VERSION "HNPBNNNYNNNNNNNNNNNNNNNNNNNNNNNNYNYYYYYYYY>4>%%%/4>'%**4YYY///"

NS_ :

BS_:

BU_: TPM TCM SCCM RF_HUB PTS ORC IC HaLF ETM ESM ESC EPS ECM Diagnost DTCM DASM CBC AFLS ADCM

BO_ 530 ECM_DIESEL: 8 ECM
 SG_ DEF_LOW : 0|2@1+ (1,0) [0|0] ""  IC
 SG_ PFW_Stat : 4|4@1+ (1,0) [0|0] ""  IC
 SG_ PrcntCplt : 8|4@1+ (10,0) [0|100] "%"  IC
 SG_ FuelFltrHtrReq : 13|2@1+ (1,0) [0|0] ""  CBC
 SG_ EngChmRq : 15|1@1+ (1,0) [0|0] ""  IC
 SG_ ECM_HMI_Timer_RQ : 16|3@1+ (1,0) [0|0] ""  IC
 SG_ PreHtIndLmp_On_Rq : 19|1@1+ (1,0) [0|0] ""  ETM,IC,CBC
 SG_ EngOilTemp_Above_Max : 20|1@1+ (1,0) [0|0] ""  IC
 SG_ PTC_REL1_RQ : 21|1@1+ (1,0) [0|0] ""  CBC
 SG_ PTC_REL2_RQ : 22|1@1+ (1,0) [0|0] ""  CBC
 SG_ PTC_REL3_RQ : 23|1@1+ (1,0) [0|0] ""  CBC
 SG_ PFW : 24|2@1+ (1,0) [0|0] ""  ETM,IC
 SG_ ParticleFltrCorrOffset : 26|4@1+ (0.03,0) [0|0.42] "" Vector__XXX
 SG_ WtrFuelIndLmp_On_Rq : 30|1@1+ (1,0) [0|0] ""  ETM,IC
 SG_ PF_RgnActv : 31|1@1+ (1,0) [0|0] ""  TCM
 SG_ Adblue_Stat : 32|6@1+ (1,0) [0|0] ""  IC
 SG_ RemainDistUnt : 38|1@1+ (1,0) [0|0] ""  IC
 SG_ Adblue_FL_LVL : 40|8@1+ (1,0) [0|100] "%"  IC
 SG_ AdblueRemainDist : 55|16@0+ (1,0) [0|65534] ""  IC

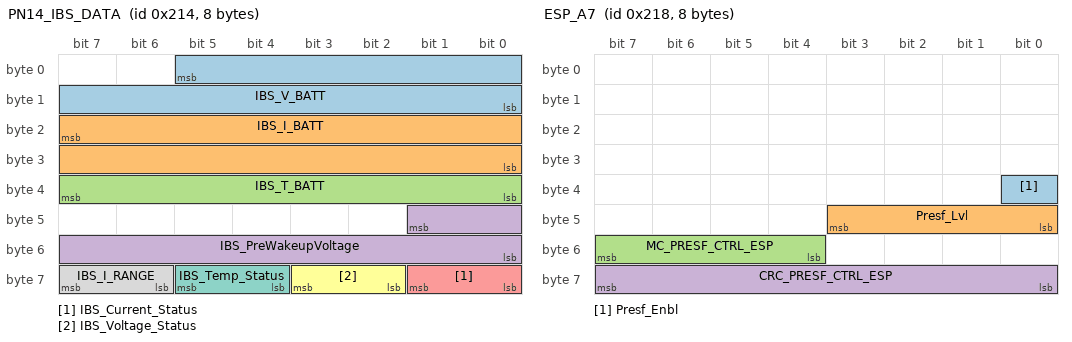
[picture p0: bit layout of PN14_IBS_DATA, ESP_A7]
BO_ 532 PN14_IBS_DATA: 8 CBC
 SG_ IBS_V_BATT : 5|14@0+ (0.0009765625,3) [3|18] "Volts"  ECM
 SG_ IBS_I_BATT : 23|16@0+ (1,-32768) [-32768|32766] "I_RANGE res."  ECM
 SG_ IBS_T_BATT : 32|8@1+ (1,-40) [-40|105] "°C"  ECM
 SG_ IBS_PreWakeupVoltage : 41|10@0+ (0.01,5) [5|15] "V"  ECM
 SG_ IBS_Current_Status : 56|2@1+ (1,0) [0|0] ""  ECM
 SG_ IBS_Voltage_Status : 58|2@1+ (1,0) [0|0] ""  ECM
 SG_ IBS_Temp_Status : 60|2@1+ (1,0) [0|0] ""  ECM
 SG_ IBS_I_RANGE : 62|2@1+ (1,0) [0|0] "Amp"  ECM

BO_ 536 ESP_A7: 8 ESC
 SG_ Presf_Enbl : 32|1@1+ (1,0) [0|0] "" Vector__XXX
 SG_ Presf_Lvl : 40|4@1+ (1,0) [0|0] "" Vector__XXX
 SG_ MC_PRESF_CTRL_ESP : 52|4@1+ (1,0) [0|15] "" Vector__XXX
 SG_ CRC_PRESF_CTRL_ESP : 56|8@1+ (1,0) [0|0] "" Vector__XXX

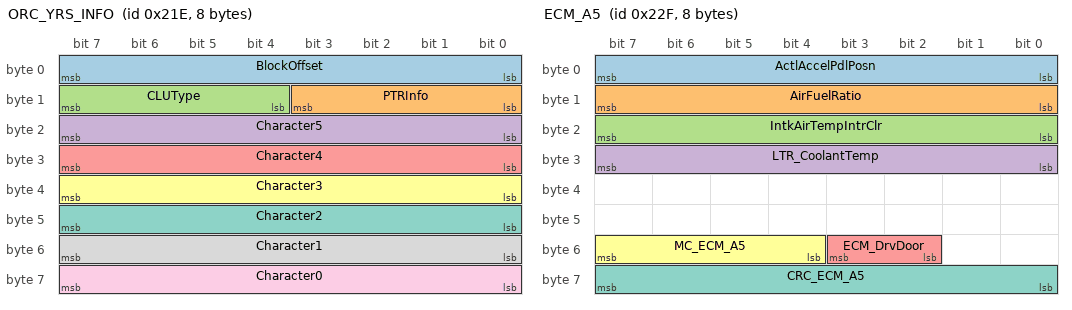
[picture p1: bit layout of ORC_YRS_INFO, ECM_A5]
BO_ 542 ORC_YRS_INFO: 8 Vector__XXX
 SG_ BlockOffset : 0|8@1+ (1,0) [0|0] ""  ESC
 SG_ PTRInfo : 8|4@1+ (1,0) [0|0] ""  ESC
 SG_ CLUType : 12|4@1+ (1,0) [0|0] ""  ESC
 SG_ Character5 : 16|8@1+ (1,0) [0|0] ""  ESC
 SG_ Character4 : 24|8@1+ (1,0) [0|0] ""  ESC
 SG_ Character3 : 32|8@1+ (1,0) [0|0] ""  ESC
 SG_ Character2 : 40|8@1+ (1,0) [0|0] ""  ESC
 SG_ Character1 : 48|8@1+ (1,0) [0|0] ""  ESC
 SG_ Character0 : 56|8@1+ (1,0) [0|0] ""  ESC

BO_ 544 EPS_1: 8 EPS
 SG_ StrClmTrq : 2|11@0+ (0.0078125,-8) [-8|7.98] "Nm"  HaLF,ECM,ESC,PTS
 SG_ TOI_Act_Sts : 3|4@1+ (1,0) [0|0] ""  HaLF,ESC,PTS
 SG_ StrClmTrqVD : 7|1@1+ (1,0) [0|0] ""  HaLF,ECM,ESC,PTS
 SG_ AssistanceTorque : 19|12@0+ (0.05,-100) [-100|104.65] "Nm"  HaLF,ESC,PTS
 SG_ PTSDriveStyleSts : 20|1@1+ (1,0) [0|0] ""  HaLF,ESC,PTS
 SG_ DSTTorqueOverlayFault : 21|1@1+ (1,0) [0|0] ""  HaLF,PTS
 SG_ HALFTorqueOverlayFault : 22|1@1+ (1,0) [0|0] ""  HaLF,ESC,PTS
 SG_ HALFTorqueOverlayIntActivated : 23|1@1+ (1,0) [0|0] ""  HaLF,ESC,PTS
 SG_ EPSMotorTorque : 34|11@0+ (0.001953125,-2) [-2|1.998047] "Nm"  HaLF
 SG_ DSTTorqueOverlayIntActivated : 37|1@1+ (1,0) [0|0] ""  HaLF,ESC
 SG_ EPSTemporaryDeactivationLDW : 38|1@1+ (1,0) [0|0] "" Vector__XXX
 SG_ EPSMotorTorqueValidData : 39|1@1+ (1,0) [0|0] ""  HaLF
 SG_ EPSHandsOnRecognition : 48|1@1+ (1,0) [0|0] ""  HaLF,ESC,PTS
 SG_ EPSTemporaryDeactivationPPPA : 49|1@1+ (1,0) [0|0] ""  HaLF,ESC,PTS
 SG_ PTSTorqueOverlayFault : 50|1@1+ (1,0) [0|0] ""  HaLF,ESC,PTS
 SG_ PTSTorqueOverlayIntActivated : 51|1@1+ (1,0) [0|0] ""  HaLF,ESC,PTS
 SG_ MC_EPS_1 : 52|4@1+ (1,0) [0|15] ""  HaLF,ECM,ESC,PTS
 SG_ CRC_EPS_1 : 56|8@1+ (1,0) [0|0] ""  HaLF,ECM,ESC,PTS

BO_ 557 SWS_8: 8 CBC
 SG_ StW_TempSts : 0|8@1+ (0.5,-40) [-40|85] "°C" Vector__XXX
 SG_ HrnSwPsd : 8|1@1+ (1,0) [0|0] ""  IC
 SG_ StW_TempSensSts : 9|2@1+ (1,0) [0|0] "" Vector__XXX
 SG_ Command_01 : 16|2@1+ (1,0) [0|0] ""  IC
 SG_ Command_02 : 18|2@1+ (1,0) [0|0] ""  IC
 SG_ Command_03 : 20|2@1+ (1,0) [0|0] ""  IC
 SG_ Command_04 : 22|2@1+ (1,0) [0|0] ""  IC
 SG_ Command_05 : 24|2@1+ (1,0) [0|0] ""  IC
 SG_ Command_06 : 26|2@1+ (1,0) [0|0] ""  IC
 SG_ Command_07 : 28|2@1+ (1,0) [0|0] ""  IC
 SG_ Command_08 : 30|2@1+ (1,0) [0|0] ""  IC
 SG_ Command_09 : 32|2@1+ (1,0) [0|0] ""  IC
 SG_ Command_10 : 34|2@1+ (1,0) [0|0] ""  IC
 SG_ Command_11 : 36|2@1+ (1,0) [0|0] ""  IC
 SG_ Command_12 : 38|2@1+ (1,0) [0|0] ""  IC
 SG_ Command_13 : 40|2@1+ (1,0) [0|0] ""  IC
 SG_ Command_14 : 42|2@1+ (1,0) [0|0] ""  IC
 SG_ Command_15 : 44|2@1+ (1,0) [0|0] ""  IC
 SG_ Command_16 : 46|2@1+ (1,0) [0|0] ""  IC

BO_ 559 ECM_A5: 8 ECM
 SG_ ActlAccelPdlPosn : 0|8@1+ (0.4,0) [0|100] "%"  DASM,ESC
 SG_ AirFuelRatio : 8|8@1+ (0.1,5.5) [5.5|18] "Lambda"  IC,CBC
 SG_ IntkAirTempIntrClr : 16|8@1+ (1,-64) [-64|190] "°C"  IC,CBC
 SG_ LTR_CoolantTemp : 24|8@1+ (1,-64) [-64|190] "°C"  IC,CBC
 SG_ ECM_DrvDoor : 50|2@1+ (1,0) [0|0] ""  DASM
 SG_ MC_ECM_A5 : 52|4@1+ (1,0) [0|15] ""  DASM
 SG_ CRC_ECM_A5 : 56|8@1+ (1,0) [0|0] ""  DASM

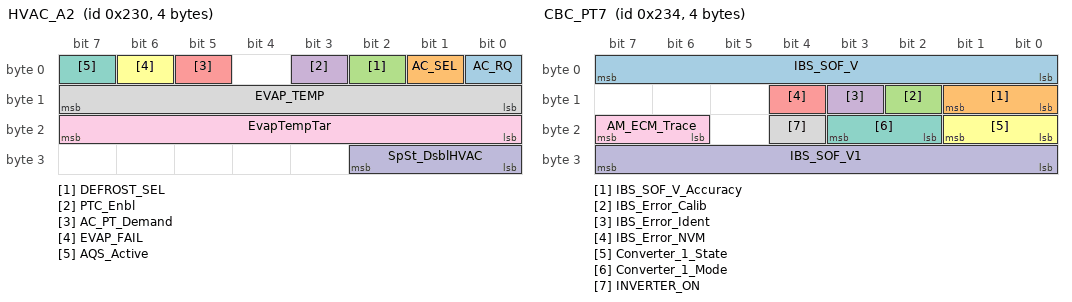
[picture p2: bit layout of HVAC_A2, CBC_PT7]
BO_ 560 HVAC_A2: 4 CBC
 SG_ AC_RQ : 0|1@1+ (1,0) [0|0] ""  ECM
 SG_ AC_SEL : 1|1@1+ (1,0) [0|0] ""  ECM
 SG_ DEFROST_SEL : 2|1@1+ (1,0) [0|0] ""  ECM
 SG_ PTC_Enbl : 3|1@1+ (1,0) [0|0] ""  ECM
 SG_ AC_PT_Demand : 5|1@1+ (1,0) [0|0] ""  ECM
 SG_ EVAP_FAIL : 6|1@1+ (1,0) [0|0] ""  ECM
 SG_ AQS_Active : 7|1@1+ (1,0) [0|0] "" Vector__XXX
 SG_ EVAP_TEMP : 8|8@1+ (0.5,-20) [-20|107] "°C"  ECM
 SG_ EvapTempTar : 16|8@1+ (0.5,-20) [-20|107] "°C"  ECM
 SG_ SpSt_DsblHVAC : 24|3@1+ (1,0) [0|0] ""  ECM

BO_ 564 CBC_PT7: 4 CBC
 SG_ IBS_SOF_V : 0|8@1+ (0.0625,0) [0|15.875] "V"  ECM
 SG_ IBS_SOF_V_Accuracy : 8|2@1+ (1,0) [0|0] ""  ECM
 SG_ IBS_Error_Calib : 10|1@1+ (1,0) [0|0] ""  ECM
 SG_ IBS_Error_Ident : 11|1@1+ (1,0) [0|0] ""  ECM
 SG_ IBS_Error_NVM : 12|1@1+ (1,0) [0|0] ""  ECM
 SG_ Converter_1_State : 16|2@1+ (1,0) [0|0] ""  ECM
 SG_ Converter_1_Mode : 18|2@1+ (1,0) [0|0] ""  ECM
 SG_ INVERTER_ON : 20|1@1+ (1,0) [0|0] ""  ECM
 SG_ AM_ECM_Trace : 22|2@1+ (1,0) [0|0] ""  ECM
 SG_ IBS_SOF_V1 : 24|8@1+ (0.0625,0) [0|15.875] "V"  ECM

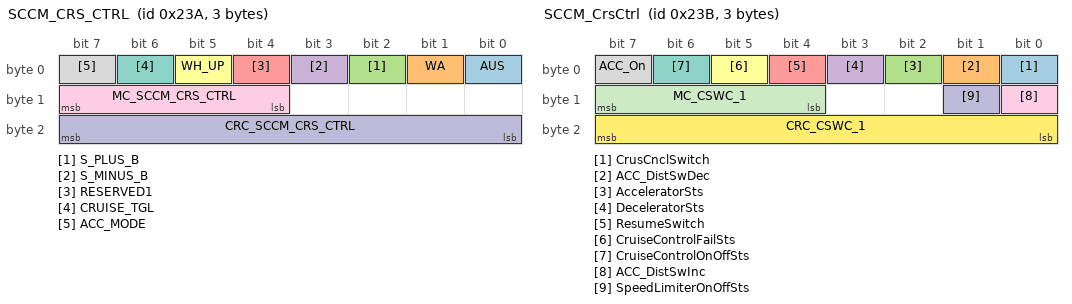
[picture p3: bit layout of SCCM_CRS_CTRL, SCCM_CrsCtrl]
BO_ 570 SCCM_CRS_CTRL: 3 Vector__XXX
 SG_ AUS : 0|1@1+ (1,0) [0|0] ""  ECM,DASM,ESC
 SG_ WA : 1|1@1+ (1,0) [0|0] ""  ECM,DASM,ESC
 SG_ S_PLUS_B : 2|1@1+ (1,0) [0|0] ""  ECM,DASM,ESC
 SG_ S_MINUS_B : 3|1@1+ (1,0) [0|0] ""  ECM,DASM,ESC
 SG_ RESERVED1 : 4|1@1+ (1,0) [0|0] ""  ECM,DASM,ESC
 SG_ WH_UP : 5|1@1+ (1,0) [0|0] ""  ECM,DASM,ESC
 SG_ CRUISE_TGL : 6|1@1+ (1,0) [0|0] ""  ECM,DASM,ESC
 SG_ ACC_MODE : 7|1@1+ (1,0) [0|0] ""  ECM,DASM,ESC
 SG_ MC_SCCM_CRS_CTRL : 12|4@1+ (1,0) [0|15] ""  ECM,DASM,ESC
 SG_ CRC_SCCM_CRS_CTRL : 16|8@1+ (1,0) [0|0] ""  ECM,DASM,ESC

BO_ 571 SCCM_CrsCtrl: 3 SCCM
 SG_ CrusCnclSwitch : 0|1@1+ (1,0) [0|0] ""  ECM,DASM,ESC
 SG_ ACC_DistSwDec : 1|1@1+ (1,0) [0|0] ""  ECM,DASM,ESC
 SG_ AcceleratorSts : 2|1@1+ (1,0) [0|0] ""  ECM,DASM,ESC
 SG_ DeceleratorSts : 3|1@1+ (1,0) [0|0] ""  ECM,DASM,ESC
 SG_ ResumeSwitch : 4|1@1+ (1,0) [0|0] ""  ECM,DASM,ESC
 SG_ CruiseControlFailSts : 5|1@1+ (1,0) [0|0] ""  ECM,DASM,ESC
 SG_ CruiseControlOnOffSts : 6|1@1+ (1,0) [0|0] ""  ECM,DASM,ESC
 SG_ ACC_On : 7|1@1+ (1,0) [0|0] ""  ECM,DASM,ESC
 SG_ ACC_DistSwInc : 8|1@1+ (1,0) [0|0] ""  ECM,DASM,ESC
 SG_ SpeedLimiterOnOffSts : 9|1@1+ (1,0) [0|0] ""  ECM,DASM,ESC
 SG_ MC_CSWC_1 : 12|4@1+ (1,0) [0|15] ""  ECM,DASM,ESC
 SG_ CRC_CSWC_1 : 16|8@1+ (1,0) [0|0] ""  ECM,DASM,ESC

BO_ 584 PN14_STAT: 8 CBC
 SG_ PN14_LS_Actv : 0|1@1+ (1,0) [0|0] ""  ECM,AFLS,TPM,PTS,IC
 SG_ PN14_Key_Off_Load_Shed : 1|2@1+ (1,0) [0|0] "" Vector__XXX
 SG_ PN14_LS_Lvl1 : 3|1@1+ (1,0) [0|0] "" Vector__XXX
 SG_ PN14_LS_Lvl2 : 4|1@1+ (1,0) [0|0] "" Vector__XXX
 SG_ PN14_LS_Lvl3 : 5|1@1+ (1,0) [0|0] "" Vector__XXX
 SG_ PN14_LS_Lvl4 : 6|1@1+ (1,0) [0|0] "" Vector__XXX
 SG_ PN14_LS_Lvl5 : 7|1@1+ (1,0) [0|0] "" Vector__XXX
 SG_ PN14_LS_Lvl6 : 8|1@1+ (1,0) [0|0] "" Vector__XXX
 SG_ PN14_LS_Lvl7 : 9|1@1+ (1,0) [0|0] "" Vector__XXX
 SG_ PN14_LS_Lvl8 : 10|1@1+ (1,0) [0|0] "" Vector__XXX
 SG_ PN14_LS_Lvl9 : 11|1@1+ (1,0) [0|0] "" Vector__XXX
 SG_ PN14_LS_Lvl10 : 12|1@1+ (1,0) [0|0] "" Vector__XXX
 SG_ IBS_SOC : 16|8@1+ (1,0) [0|100] "%"  ORC,ECM
 SG_ IBS_SOF_Q : 24|8@1+ (0.5,0) [0|127] "Ah"  ECM
 SG_ IBS_SOH_Q : 32|8@1+ (0.5,0) [0|127] "Ah"  ECM
 SG_ IBS_SOF_t : 41|10@0+ (1,0) [0|1022] "min"  ECM
 SG_ Batt_ST_Crit : 42|1@1+ (1,0) [0|0] ""  ECM
 SG_ IBS_SOC_Accuracy : 56|2@1+ (1,0) [0|0] ""  ECM
 SG_ IBS_SOF_Q_Accuracy : 58|2@1+ (1,0) [0|0] ""  ECM
 SG_ IBS_SOH_Q_Accuracy : 60|2@1+ (1,0) [0|0] ""  ECM
 SG_ IBS_SOF_t_Accuracy : 62|2@1+ (1,0) [0|0] ""  ECM

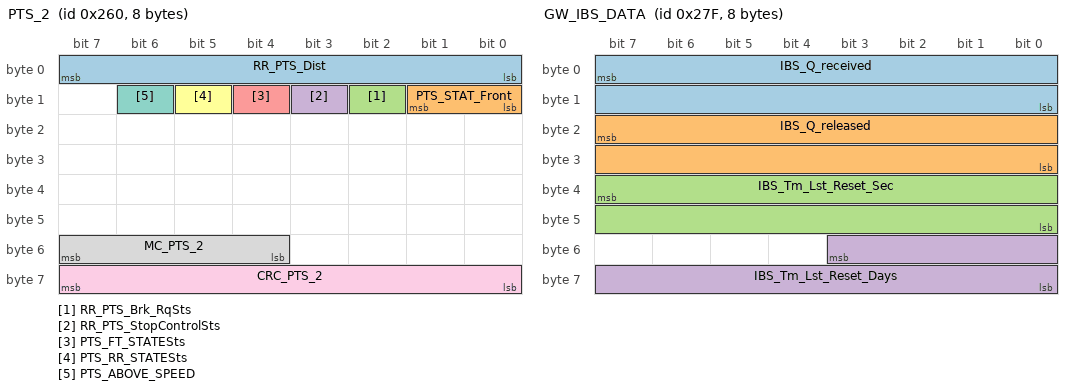
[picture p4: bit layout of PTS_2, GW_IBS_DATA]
BO_ 608 PTS_2: 8 PTS
 SG_ RR_PTS_Dist : 0|8@1+ (1,0) [0|254] "cm"  ESC
 SG_ PTS_STAT_Front : 8|2@1+ (1,0) [0|0] ""  CBC
 SG_ RR_PTS_Brk_RqSts : 10|1@1+ (1,0) [0|0] ""  ESC
 SG_ RR_PTS_StopControlSts : 11|1@1+ (1,0) [0|0] ""  ESC,CBC
 SG_ PTS_FT_STATESts : 12|1@1+ (1,0) [0|0] ""  IC
 SG_ PTS_RR_STATESts : 13|1@1+ (1,0) [0|0] ""  IC
 SG_ PTS_ABOVE_SPEED : 14|1@1+ (1,0) [0|0] ""  IC
 SG_ MC_PTS_2 : 52|4@1+ (1,0) [0|15] ""  ESC
 SG_ CRC_PTS_2 : 56|8@1+ (1,0) [0|0] ""  ESC

BO_ 624 CBC_PT8: 8 CBC
 SG_ PrkLmpFault : 0|1@1+ (1,0) [0|0] ""  IC
 SG_ LowBeamFault : 1|1@1+ (1,0) [0|0] ""  AFLS,IC
 SG_ HighBeamFault : 2|1@1+ (1,0) [0|0] ""  IC
 SG_ DRLFault : 3|1@1+ (1,0) [0|0] ""  IC
 SG_ FtFogLmpFault : 4|1@1+ (1,0) [0|0] ""  IC
 SG_ RearFogLmpFault : 5|1@1+ (1,0) [0|0] ""  IC
 SG_ SpLmpFault : 6|1@1+ (1,0) [0|0] ""  IC
 SG_ RevLmpFault : 7|1@1+ (1,0) [0|0] ""  IC
 SG_ PlateLmpFault : 8|1@1+ (1,0) [0|0] ""  IC
 SG_ TrlrSpTurnFault : 9|1@1+ (1,0) [0|0] ""  IC
 SG_ TrlrPrkFault : 10|1@1+ (1,0) [0|0] ""  IC
 SG_ HlSwFault : 11|1@1+ (1,0) [0|0] ""  IC
 SG_ AmbLgtSnsrFault : 12|1@1+ (1,0) [0|0] ""  IC
 SG_ AHB_Fault : 13|1@1+ (1,0) [0|0] ""  IC
 SG_ LgtSensFlt : 14|1@1+ (1,0) [0|0] ""  IC
 SG_ FuelTxfrSts : 42|2@1+ (1,0) [0|0] ""  ECM
 SG_ SecurePkSts : 44|3@1+ (1,0) [0|0] ""  IC
 SG_ HAZARD_STATUS : 47|1@1+ (1,0) [0|0] "" Vector__XXX
 SG_ EngineOffTimer : 51|12@0+ (1,0) [0|4080] "min"  ECM
 SG_ HL_Stat : 53|2@1+ (1,0) [0|0] "" Vector__XXX
 SG_ PNC_ALM_ACT : 55|1@1+ (1,0) [0|0] "" Vector__XXX

BO_ 632 ECM_B2: 8 ECM
 SG_ CC_SetSpdDspl : 0|8@1+ (1,0) [0|250] "km/h"  IC
 SG_ EngDrvMdStat : 8|3@1+ (1,0) [0|0] ""  TCM,CBC
 SG_ IdleShutDwnApply : 11|1@1+ (1,0) [0|0] ""  IC,CBC
 SG_ EVPmpStat : 12|2@1+ (1,0) [0|0] ""  ESC
 SG_ EconShftRq : 14|2@1+ (1,0) [0|0] ""  IC
 SG_ CoolVlvPos : 16|8@1+ (0.39374,0) [0|100] "%"  CBC
 SG_ VehMassCalc : 24|8@1+ (100,0) [0|25400] "Lbs."  DTCM,DASM,ESC
 SG_ VehMassCnfd : 32|3@1+ (1,0) [0|0] ""  DTCM,DASM,ESC
 SG_ EnblFuelTxfr : 35|1@1+ (1,0) [0|0] ""  CBC
 SG_ PerfShftRq : 36|2@1+ (1,0) [0|0] ""  TCM,IC
 SG_ CC_SetSpdDsplMPH : 40|8@1+ (1,0) [0|254] "mph"  IC
 SG_ SpStSwStat : 48|2@1+ (1,0) [0|0] ""  ORC,IC,CBC
 SG_ SpStTachMd : 50|2@1+ (1,0) [0|0] ""  IC,CBC
 SG_ SpStWarnStat : 52|4@1+ (1,0) [0|0] ""  ORC,IC
 SG_ SpStDispstat : 56|6@1+ (1,0) [0|0] ""  ORC,IC
 SG_ SpStIndRq : 62|1@1+ (1,0) [0|0] ""  IC
 SG_ SpStChmRq : 63|1@1+ (1,0) [0|0] ""  IC

BO_ 639 GW_IBS_DATA: 8 CBC
 SG_ IBS_Q_received : 7|16@0+ (0.125,0) [0|8191.75] "Ah" Vector__XXX
 SG_ IBS_Q_released : 23|16@0+ (0.125,0) [0|8191.75] "Ah" Vector__XXX
 SG_ IBS_Tm_Lst_Reset_Sec : 39|16@0+ (2,0) [0|86398] "sec"  ECM
 SG_ IBS_Tm_Lst_Reset_Days : 51|12@0+ (1,0) [0|4094] "Days" Vector__XXX

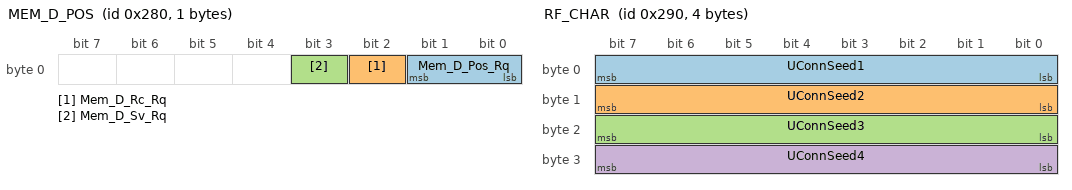
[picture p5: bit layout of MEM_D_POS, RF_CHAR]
BO_ 640 MEM_D_POS: 1 CBC
 SG_ Mem_D_Pos_Rq : 0|2@1+ (1,0) [0|0] ""  IC
 SG_ Mem_D_Rc_Rq : 2|1@1+ (1,0) [0|0] ""  IC
 SG_ Mem_D_Sv_Rq : 3|1@1+ (1,0) [0|0] ""  IC

BO_ 656 RF_CHAR: 4 RF_HUB
 SG_ UConnSeed1 : 0|8@1+ (1,0) [0|0] ""  ETM
 SG_ UConnSeed2 : 8|8@1+ (1,0) [0|0] ""  ETM
 SG_ UConnSeed3 : 16|8@1+ (1,0) [0|0] ""  ETM
 SG_ UConnSeed4 : 24|8@1+ (1,0) [0|0] ""  ETM

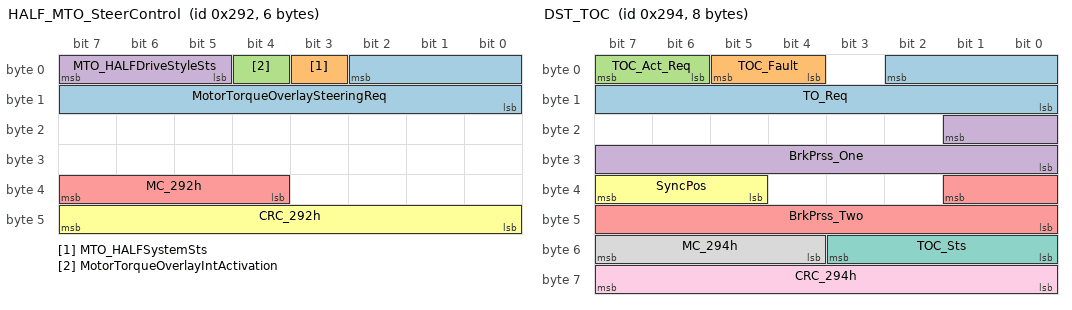
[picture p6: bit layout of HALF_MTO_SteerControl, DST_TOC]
BO_ 658 HALF_MTO_SteerControl: 6 HaLF
 SG_ MotorTorqueOverlaySteeringReq : 2|11@0+ (0.001953125,-2) [-2|1.998047] "Nm"  EPS
 SG_ MTO_HALFSystemSts : 3|1@1+ (1,0) [0|0] ""  EPS
 SG_ MotorTorqueOverlayIntActivation : 4|1@1+ (1,0) [0|0] ""  EPS
 SG_ MTO_HALFDriveStyleSts : 5|3@1+ (1,0) [0|0] ""  EPS
 SG_ MC_292h : 36|4@1+ (1,0) [0|15] ""  EPS
 SG_ CRC_292h : 40|8@1+ (1,0) [0|0] ""  EPS

BO_ 660 DST_TOC: 8 ESC
 SG_ TO_Req : 2|11@0+ (0.0078125,-8) [-8|7.9921875] "Nm"  EPS
 SG_ TOC_Fault : 4|2@1+ (1,0) [0|0] ""  EPS
 SG_ TOC_Act_Req : 6|2@1+ (1,0) [0|0] ""  EPS
 SG_ BrkPrss_One : 17|10@0+ (0.0048828125,0) [0|4.9951171875] "Volts"  ECM,EPS
 SG_ BrkPrss_Two : 33|10@0+ (0.0048828125,0) [0|4.9951171875] "Volts"  ECM,EPS
 SG_ SyncPos : 37|3@1+ (1,0) [0|0] ""  ECM,EPS
 SG_ TOC_Sts : 48|4@1+ (1,0) [0|0] ""  EPS
 SG_ MC_294h : 52|4@1+ (1,0) [0|15] ""  EPS
 SG_ CRC_294h : 56|8@1+ (1,0) [0|0] ""  EPS

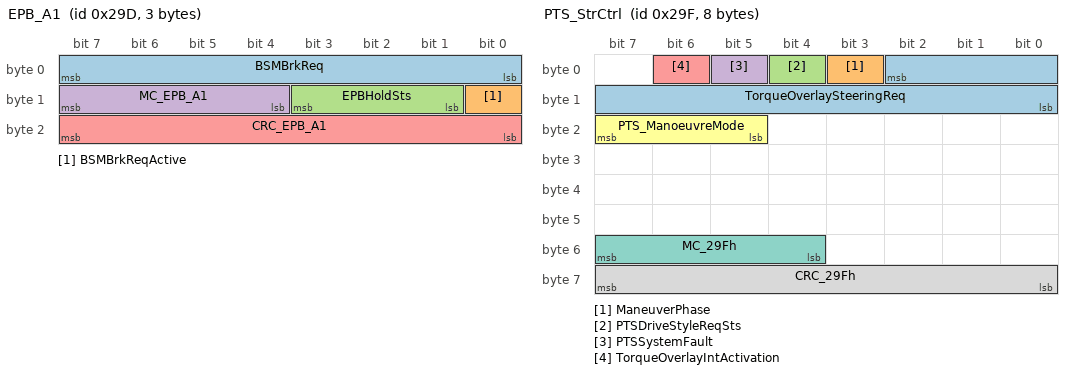
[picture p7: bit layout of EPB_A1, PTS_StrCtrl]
BO_ 669 EPB_A1: 3 Vector__XXX
 SG_ BSMBrkReq : 0|8@1+ (0.0312,0) [0|7.968] "m/s²"  ETM,TCM,ECM,DASM,ESC,CBC
 SG_ BSMBrkReqActive : 8|1@1+ (1,0) [0|0] ""  ETM,TCM,ECM,DASM,ESC,CBC
 SG_ EPBHoldSts : 9|3@1+ (1,0) [0|0] ""  ETM,ORC,TCM,ECM,DASM,ESC,CBC
 SG_ MC_EPB_A1 : 12|4@1+ (1,0) [0|15] ""  ETM,TCM,ECM,DASM,ESC,CBC
 SG_ CRC_EPB_A1 : 16|8@1+ (1,0) [0|0] ""  ETM,TCM,ECM,DASM,ESC,CBC

BO_ 671 PTS_StrCtrl: 8 PTS
 SG_ TorqueOverlaySteeringReq : 2|11@0+ (0.0078125,-8) [-8|7.9921875] "Nm"  EPS
 SG_ ManeuverPhase : 3|1@1+ (1,0) [0|0] ""  EPS
 SG_ PTSDriveStyleReqSts : 4|1@1+ (1,0) [0|0] ""  EPS
 SG_ PTSSystemFault : 5|1@1+ (1,0) [0|0] ""  EPS,IC
 SG_ TorqueOverlayIntActivation : 6|1@1+ (1,0) [0|0] ""  EPS
 SG_ PTS_ManoeuvreMode : 21|3@1+ (1,0) [0|0] ""  EPS,IC
 SG_ MC_29Fh : 52|4@1+ (1,0) [0|15] ""  EPS
 SG_ CRC_29Fh : 56|8@1+ (1,0) [0|0] ""  EPS

BO_ 672 ECM_INDICATORS: 8 ECM
 SG_ MIL_OnRq : 0|1@1+ (1,0) [0|0] ""  ORC,DASM,IC,CBC
 SG_ MIL_IND_BLINK : 1|1@1+ (1,0) [0|0] ""  ORC,IC,CBC
 SG_ ETC_IND_LMP : 2|2@1+ (1,0) [0|0] ""  ETM,IC,CBC
 SG_ MZR_MODE_ACT : 4|1@1+ (1,0) [0|0] ""  ETM,TCM,IC
 SG_ FUEL_SAV_MD_ACT : 5|2@1+ (1,0) [0|0] ""  IC,CBC
 SG_ OIL_IND_LMP_FLSH : 8|1@1+ (1,0) [0|0] ""  IC
 SG_ AutoOilChg : 9|1@1+ (1,0) [0|0] ""  IC,CBC
 SG_ EngOilIndLmp_On_Rq : 10|1@1+ (1,0) [0|0] ""  ETM,IC,CBC
 SG_ OIL_TEMP_IND_RQ : 11|2@1+ (1,0) [0|0] ""  ETM,IC
 SG_ OIL_TEMP_CHM_RQ : 13|2@1+ (1,0) [0|0] ""  ETM,IC
 SG_ ChkFuelCap : 15|1@1+ (1,0) [0|0] ""  ETM,IC
 SG_ OIL_PRESS : 16|8@1+ (4,0) [0|1016] "kPaG"  ETM,IC,CBC
 SG_ EngOilTemp : 24|8@1+ (1,-40) [-40|160] "°C"  EPS,TCM,IC,CBC
 SG_ FuelCons : 39|16@0+ (0.21668,0) [0|14200] "µl/100ms"  IC,CBC
 SG_ DefFuelEcon : 48|8@1+ (0.2,0) [0|50] "kmpl"  IC
 SG_ EngRun_Stat : 56|3@1+ (1,0) [0|0] ""  DASM,ESC,AFLS,PTS,IC,CBC,RF_HUB
 SG_ RedntHdStat : 59|2@1+ (1,0) [0|0] ""  IC

CM_ SG_ 530 DEF_LOW "DEF Low Indicator request";
CM_ SG_ 530 PFW_Stat "Particulate filter warning status";
CM_ SG_ 530 PrcntCplt "Percent complete";
CM_ SG_ 530 FuelFltrHtrReq "Fuel filter heater request on";
CM_ SG_ 530 EngChmRq "Engine chime request";
CM_ SG_ 530 ECM_HMI_Timer_RQ "DEF and DPF warning re-launch timer request";
CM_ SG_ 530 PreHtIndLmp_On_Rq "Request glow-plug (wait to start) lamp";
CM_ SG_ 530 EngOilTemp_Above_Max "Engine oil temperature too high (overheating)";
CM_ SG_ 530 PTC_REL1_RQ "Activate PTC Relay # 1 (diesel only)";
CM_ SG_ 530 PTC_REL2_RQ "Activate PTC Relay # 2 (diesel only)";
CM_ SG_ 530 PTC_REL3_RQ "Activate PTC Relay # 3 (diesel only)";
CM_ SG_ 530 PFW "Particulate filter warning";
CM_ SG_ 530 ParticleFltrCorrOffset "Particulate Filter Corection Offset SLP_MS_OFS";
CM_ SG_ 530 WtrFuelIndLmp_On_Rq "Request water in fuel lamp (diesel only)";
CM_ SG_ 530 PF_RgnActv "Particulate filter regeneration active";
CM_ SG_ 530 Adblue_Stat "Adblue status";
CM_ SG_ 530 RemainDistUnt "Adblue distance counter unit; miles = [0], km = [1]";
CM_ SG_ 530 Adblue_FL_LVL "Adblue fluid level";
CM_ SG_ 530 AdblueRemainDist "Adblue remaining distance";
CM_ SG_ 532 IBS_V_BATT "Batt. voltage measured at the terminals";
CM_ SG_ 532 IBS_I_BATT "Battery current (Using I_Range resolution)";
CM_ SG_ 532 IBS_T_BATT "Battery temperature";
CM_ SG_ 532 IBS_PreWakeupVoltage "IBS voltage before LIN wakeup";
CM_ SG_ 532 IBS_Current_Status "IBS Current Status";
CM_ SG_ 532 IBS_Voltage_Status "IBS Voltage Status";
CM_ SG_ 532 IBS_Temp_Status "IBS Temperature Status";
CM_ SG_ 532 IBS_I_RANGE "Current range sensor setting";
CM_ SG_ 536 Presf_Enbl "Presafe enabled";
CM_ SG_ 536 Presf_Lvl "Presafe level";
CM_ SG_ 536 MC_PRESF_CTRL_ESP "Message counter";
CM_ SG_ 536 CRC_PRESF_CTRL_ESP "CRC-checksum byte 1 to 7 according to SAE J1850";
CM_ SG_ 542 BlockOffset "Part number block offset";
CM_ SG_ 542 PTRInfo "Part number PTR information";
CM_ SG_ 542 CLUType "Part number CLU type";
CM_ SG_ 542 Character5 "Part number character 5";
CM_ SG_ 542 Character4 "Part number character 4";
CM_ SG_ 542 Character3 "Part number character 3";
CM_ SG_ 542 Character2 "Part number character 2";
CM_ SG_ 542 Character1 "Part number character 1";
CM_ SG_ 542 Character0 "Part number character 0";
CM_ SG_ 544 StrClmTrq "Steering column torque; counterclockwise positive [Nm]";
CM_ SG_ 544 TOI_Act_Sts "Torque overlay interface status";
CM_ SG_ 544 StrClmTrqVD "Steering column torque: valid data [1]";
CM_ SG_ 544 AssistanceTorque "Torque provided by EPS system to the shaft for the driver";
CM_ SG_ 544 PTSDriveStyleSts "PTS_TOC Actived = [1]";
CM_ SG_ 544 DSTTorqueOverlayFault "Torque overlay fault; True = 1";
CM_ SG_ 544 HALFTorqueOverlayFault "Fault of the HALF torque overlay interface";
CM_ SG_ 544 HALFTorqueOverlayIntActivated "Torque overlay interface has been successfully activated";
CM_ SG_ 544 EPSMotorTorque "EPS motor torque";
CM_ SG_ 544 DSTTorqueOverlayIntActivated "DST torque overlay interface activated; True = [1]";
CM_ SG_ 544 EPSTemporaryDeactivationLDW "Temporary deactivation of the EPS LDW torque overlay function";
CM_ SG_ 544 EPSMotorTorqueValidData "Motor torque: valid data [1]";
CM_ SG_ 544 EPSHandsOnRecognition "Driver interference during the semiautomatic parking maneuver";
CM_ SG_ 544 EPSTemporaryDeactivationPPPA "Temporary deactivation of the EPS PPPA torque overlay function";
CM_ SG_ 544 PTSTorqueOverlayFault "Fault of the PTS torque overlay interface";
CM_ SG_ 544 PTSTorqueOverlayIntActivated "Torque overlay interface has been successfully activated";
CM_ SG_ 544 MC_EPS_1 "Message counter";
CM_ SG_ 544 CRC_EPS_1 "CRC-checksum byte 1 to 7 according to SAE J1850";
CM_ SG_ 557 StW_TempSts "Steering wheel temperature";
CM_ SG_ 557 HrnSwPsd "Horn switch pressed (1=pressed)";
CM_ SG_ 557 StW_TempSensSts "Steering wheel temperature sensor status";
CM_ SG_ 557 Command_01 "Steering wheel switch 1";
CM_ SG_ 557 Command_02 "Steering wheel switch 2";
CM_ SG_ 557 Command_03 "Steering wheel switch 3";
CM_ SG_ 557 Command_04 "Steering wheel switch 4";
CM_ SG_ 557 Command_05 "Steering wheel switch 5";
CM_ SG_ 557 Command_06 "Steering wheel switch 6";
CM_ SG_ 557 Command_07 "Steering wheel switch 7";
CM_ SG_ 557 Command_08 "Steering wheel switch 8";
CM_ SG_ 557 Command_09 "Steering wheel switch 9";
CM_ SG_ 557 Command_10 "Steering wheel switch 10";
CM_ SG_ 557 Command_11 "Steering wheel switch 11";
CM_ SG_ 557 Command_12 "Steering wheel switch 12";
CM_ SG_ 557 Command_13 "Steering wheel switch 13";
CM_ SG_ 557 Command_14 "Steering wheel switch 14";
CM_ SG_ 557 Command_15 "Steering wheel switch 15";
CM_ SG_ 557 Command_16 "Steering wheel switch 16";
CM_ SG_ 559 ActlAccelPdlPosn "Throttle Pedal Position (actual)";
CM_ SG_ 559 AirFuelRatio "Air To fuel ratio";
CM_ SG_ 559 IntkAirTempIntrClr "Intake air temperature post intercooler";
CM_ SG_ 559 LTR_CoolantTemp "Low temp radiator (intercooler) coolant temperature";
CM_ SG_ 559 ECM_DrvDoor "ECM drivers door";
CM_ SG_ 559 MC_ECM_A5 "Message counter";
CM_ SG_ 559 CRC_ECM_A5 "CRC-checksum byte 1 to 7 according to SAE J1850";
CM_ SG_ 560 AC_RQ "A/C clutch request";
CM_ SG_ 560 AC_SEL "Customer has selected A/C";
CM_ SG_ 560 DEFROST_SEL "Defrost select switch";
CM_ SG_ 560 PTC_Enbl "PTC heater enable; [1] = enable";
CM_ SG_ 560 AC_PT_Demand "Maximum A/C demand to powertrain";
CM_ SG_ 560 EVAP_FAIL "Evaporator sensor failure";
CM_ SG_ 560 AQS_Active "Air quality sensor is active; active = [1]";
CM_ SG_ 560 EVAP_TEMP "AC evaporator temperature";
CM_ SG_ 560 EvapTempTar "Evaporator temperature target";
CM_ SG_ 560 SpSt_DsblHVAC "Stop start disable from HVAC";
CM_ SG_ 564 IBS_SOF_V "Predicted battery voltage during cranking V2";
CM_ SG_ 564 IBS_SOF_V_Accuracy "SOF_V accuracy status";
CM_ SG_ 564 IBS_Error_Calib "Error in IBS calibration data; Error = [1]";
CM_ SG_ 564 IBS_Error_Ident "Error in ECU identification; Error = [1]";
CM_ SG_ 564 IBS_Error_NVM "Error in IBS NVM data; Error = [1]";
CM_ SG_ 564 Converter_1_State "DC-DC converter_1 state";
CM_ SG_ 564 Converter_1_Mode "DC-DC converter_1 mode";
CM_ SG_ 564 INVERTER_ON "Inverter is on; [1] = True";
CM_ SG_ 564 AM_ECM_Trace "Aftermarket ECM trace";
CM_ SG_ 564 IBS_SOF_V1 "Predicted initial battery voltage dip during cranking";
CM_ SG_ 570 AUS "Cruise Switch: Cancel Pressed";
CM_ SG_ 570 WA "Cruise Switch: distance / launch mode pressed";
CM_ SG_ 570 S_PLUS_B "Cruise Switch: Resume/Accel Pressed";
CM_ SG_ 570 S_MINUS_B "Cruise Switch: Coast or Set/Decel Pressed";
CM_ SG_ 570 RESERVED1 "Place holder in 1,4 used in parity calculation";
CM_ SG_ 570 WH_UP "Cruise Switch: Implausible State=1";
CM_ SG_ 570 CRUISE_TGL "Cruise Switch: On/Off  Pressed";
CM_ SG_ 570 ACC_MODE "Cruise Switch: ACC or ESC mode pressed";
CM_ SG_ 570 MC_SCCM_CRS_CTRL "Message counter";
CM_ SG_ 570 CRC_SCCM_CRS_CTRL "CRC-checksum byte 1 to 2 according to SAE J1850";
CM_ SG_ 571 CrusCnclSwitch "Cruise Switch: Cancel Pressed";
CM_ SG_ 571 ACC_DistSwDec "Cruise Switch: Distance Decrease pressed";
CM_ SG_ 571 AcceleratorSts "Cruise Switch: Set/Accel Pressed";
CM_ SG_ 571 DeceleratorSts "Cruise Switch: Coast or Set/Decel Pressed";
CM_ SG_ 571 ResumeSwitch "Cruise Switch: Resume Pressed";
CM_ SG_ 571 CruiseControlFailSts "Cruise Switch: Implausible State=1";
CM_ SG_ 571 CruiseControlOnOffSts "Cruise Switch: On/Off  Pressed";
CM_ SG_ 571 ACC_On "Cruise Switch: ACC or ESC mode pressed";
CM_ SG_ 571 ACC_DistSwInc "Cruise Switch: Distance Increase pressed";
CM_ SG_ 571 SpeedLimiterOnOffSts "Cruise Switch:Speed Limiter On/Off Pressed";
CM_ SG_ 571 MC_CSWC_1 "Message counter";
CM_ SG_ 571 CRC_CSWC_1 "CRC-checksum byte 1 to 2 according to SAE J1850";
CM_ SG_ 584 PN14_LS_Actv "14 V powernet Load Shed active";
CM_ SG_ 584 PN14_Key_Off_Load_Shed "Key-off load shed";
CM_ SG_ 584 PN14_LS_Lvl1 "Load Shedding level1";
CM_ SG_ 584 PN14_LS_Lvl2 "Load Shedding level2";
CM_ SG_ 584 PN14_LS_Lvl3 "Load Shedding level3";
CM_ SG_ 584 PN14_LS_Lvl4 "Load Shedding level4";
CM_ SG_ 584 PN14_LS_Lvl5 "Load Shedding level5";
CM_ SG_ 584 PN14_LS_Lvl6 "Load Shedding level6";
CM_ SG_ 584 PN14_LS_Lvl7 "Load Shedding level7";
CM_ SG_ 584 PN14_LS_Lvl8 "Load Shedding level8";
CM_ SG_ 584 PN14_LS_Lvl9 "Load Shedding level9";
CM_ SG_ 584 PN14_LS_Lvl10 "Load Shedding level10";
CM_ SG_ 584 IBS_SOC "State of charge";
CM_ SG_ 584 IBS_SOF_Q "Residual battery charge in Ah";
CM_ SG_ 584 IBS_SOH_Q "State of health";
CM_ SG_ 584 IBS_SOF_t "Predicted time limit for start capability";
CM_ SG_ 584 Batt_ST_Crit "Battery reached critical state";
CM_ SG_ 584 IBS_SOC_Accuracy "SOC accuracy status";
CM_ SG_ 584 IBS_SOF_Q_Accuracy "SOF_Q accuracy status";
CM_ SG_ 584 IBS_SOH_Q_Accuracy "SOH_Q accuracy status";
CM_ SG_ 584 IBS_SOF_t_Accuracy "SOF_t accuracy status";
CM_ SG_ 608 RR_PTS_Dist "Rear distance to nearest obstacle";
CM_ SG_ 608 PTS_STAT_Front "Front park assist system - LED control status";
CM_ SG_ 608 RR_PTS_Brk_RqSts "PTS rear brake request flag; True = [1]";
CM_ SG_ 608 RR_PTS_StopControlSts "PTS rear park stop control status; Enabled = [1]";
CM_ SG_ 608 PTS_FT_STATESts "PTS front state status; True = [1]";
CM_ SG_ 608 PTS_RR_STATESts "PTS rear state status; True = [1]";
CM_ SG_ 608 PTS_ABOVE_SPEED "ParkSense active speed threshold is exceeded; True = [1]";
CM_ SG_ 608 MC_PTS_2 "Message counter";
CM_ SG_ 608 CRC_PTS_2 "CRC-checksum byte 1 to 7 according to SAE J1850";
CM_ SG_ 624 PrkLmpFault "Park lamp fault detected";
CM_ SG_ 624 LowBeamFault "Low beam headlamp faulted";
CM_ SG_ 624 HighBeamFault "High beam or shutter fault detected";
CM_ SG_ 624 DRLFault "DRL lamp display faulted";
CM_ SG_ 624 FtFogLmpFault "Front fog lamp fault detected";
CM_ SG_ 624 RearFogLmpFault "Rear fog lamp fault detected";
CM_ SG_ 624 SpLmpFault "Stop lamp or CHMSL display faulted";
CM_ SG_ 624 RevLmpFault "Backup lamp fault detected";
CM_ SG_ 624 PlateLmpFault "License lamp fault detected";
CM_ SG_ 624 TrlrSpTurnFault "Trailer stop or turn lamp relay control circuit is faulted";
CM_ SG_ 624 TrlrPrkFault "Trailer park lamp relay control circuit is faulted.";
CM_ SG_ 624 HlSwFault "Headlamp switch input fault";
CM_ SG_ 624 AmbLgtSnsrFault "Ambient light sensor value out of range";
CM_ SG_ 624 AHB_Fault "AHBM fault; Fault = [1]";
CM_ SG_ 624 LgtSensFlt "Light sensor fault; Fault = [1]";
CM_ SG_ 624 FuelTxfrSts "Fuel transfer relay status";
CM_ SG_ 624 SecurePkSts "Secure park status";
CM_ SG_ 624 HAZARD_STATUS "Hazard lamps; active = [1]";
CM_ SG_ 624 EngineOffTimer "Engine off timer - engine off ignition NOT lock.";
CM_ SG_ 624 HL_Stat "Headlamp status";
CM_ SG_ 624 PNC_ALM_ACT "Panic alarm active; [1] = True";
CM_ SG_ 632 CC_SetSpdDspl "Cruise control set speed for display (kmph only)";
CM_ SG_ 632 EngDrvMdStat "Engine driving mode status";
CM_ SG_ 632 IdleShutDwnApply "Idle Shut down applied; 1 = True";
CM_ SG_ 632 EVPmpStat "Electric vacuum pump status";
CM_ SG_ 632 EconShftRq "Economy transmission shift request";
CM_ SG_ 632 CoolVlvPos "Coolant (3-way) valve position";
CM_ SG_ 632 VehMassCalc "Vehicle mass calculation";
CM_ SG_ 632 VehMassCnfd "Vehicle mass confidence level";
CM_ SG_ 632 EnblFuelTxfr "Enable fuel transfer; True = [1]";
CM_ SG_ 632 PerfShftRq "Performance transmission shift request";
CM_ SG_ 632 CC_SetSpdDsplMPH "Cruise control set speed for display in miles per hour";
CM_ SG_ 632 SpStSwStat "Stop start switch status";
CM_ SG_ 632 SpStTachMd "Stop start tachometer mode";
CM_ SG_ 632 SpStWarnStat "Stop start warning status";
CM_ SG_ 632 SpStDispstat "Stop start display status";
CM_ SG_ 632 SpStIndRq "Stop start indicator request";
CM_ SG_ 632 SpStChmRq "Stop start chime request";
CM_ SG_ 639 IBS_Q_received "LifeTime charge received";
CM_ SG_ 639 IBS_Q_released "Lifetime charge released";
CM_ SG_ 639 IBS_Tm_Lst_Reset_Sec "Accumulated time since last reset in seconds";
CM_ SG_ 639 IBS_Tm_Lst_Reset_Days "Accumulated time since last reset in days";
CM_ SG_ 640 Mem_D_Pos_Rq "Memory driver - position request";
CM_ SG_ 640 Mem_D_Rc_Rq "Memory driver - recall position";
CM_ SG_ 640 Mem_D_Sv_Rq "Memory driver - save position";
CM_ SG_ 656 UConnSeed1 "Character 1";
CM_ SG_ 656 UConnSeed2 "Character 2";
CM_ SG_ 656 UConnSeed3 "Character 3";
CM_ SG_ 656 UConnSeed4 "Character 4";
CM_ SG_ 658 MotorTorqueOverlaySteeringReq "HaLF torque overlay steering request";
CM_ SG_ 658 MTO_HALFSystemSts "HaLF system status; Faulted = [1]";
CM_ SG_ 658 MotorTorqueOverlayIntActivation "Torques overlay interface activation; Active = [1]";
CM_ SG_ 658 MTO_HALFDriveStyleSts "HaLF drive style status acknowledgement";
CM_ SG_ 658 MC_292h "Message counter";
CM_ SG_ 658 CRC_292h "CRC-checksum byte 1 to 5 according to SAE J1850";
CM_ SG_ 660 TO_Req "Torque requested by the PTS torque overlay";
CM_ SG_ 660 TOC_Fault "Torque overlay controller fault";
CM_ SG_ 660 TOC_Act_Req "Torque overlay controller active request";
CM_ SG_ 660 BrkPrss_One "Brake Pressure One (P1)";
CM_ SG_ 660 BrkPrss_Two "Brake Pressure Two (P2 if supported)";
CM_ SG_ 660 SyncPos "Signal P2 sync position";
CM_ SG_ 660 TOC_Sts "Torque overlay controller status";
CM_ SG_ 660 MC_294h "Message counter";
CM_ SG_ 660 CRC_294h "CRC-checksum byte 1 to 7 according to SAE J1850";
CM_ SG_ 669 BSMBrkReq "Waiting on defined by Jingwei Sun";
CM_ SG_ 669 BSMBrkReqActive "Waiting on defined by Jingwei Sun; Active = 1";
CM_ SG_ 669 EPBHoldSts "Waiting on defined by Jingwei Sun";
CM_ SG_ 669 MC_EPB_A1 "Message counter";
CM_ SG_ 669 CRC_EPB_A1 "CRC-checksum byte 1 to 2 according to SAE J1850";
CM_ SG_ 671 TorqueOverlaySteeringReq "Torque requested by the PTS torque overlay";
CM_ SG_ 671 ManeuverPhase "Movement direction estimated by PTS; Forward = [1]";
CM_ SG_ 671 PTSDriveStyleReqSts "PTS drive style request status; Active = [1]";
CM_ SG_ 671 PTSSystemFault "PTS system fault; True = [1]";
CM_ SG_ 671 TorqueOverlayIntActivation "Torques overlay interface activiation request; Active = [1]";
CM_ SG_ 671 PTS_ManoeuvreMode "Parking maneuver mode status of the PTS";
CM_ SG_ 671 MC_29Fh "Message counter";
CM_ SG_ 671 CRC_29Fh "CRC-checksum byte 1 to 7 according to SAE J1850";
CM_ SG_ 672 MIL_OnRq "MIL on request from the engine";
CM_ SG_ 672 MIL_IND_BLINK "Request MIL blink (OBD II)";
CM_ SG_ 672 ETC_IND_LMP "ETC faulty, indicator lamp request";
CM_ SG_ 672 MZR_MODE_ACT "Mizer mode active (enabled = [1])";
CM_ SG_ 672 FUEL_SAV_MD_ACT "Engine operating in fuel efficient manner";
CM_ SG_ 672 OIL_IND_LMP_FLSH "Oil indicator lamp flash (for in plant use)";
CM_ SG_ 672 AutoOilChg "Automatic Oil Change Indicator";
CM_ SG_ 672 EngOilIndLmp_On_Rq "Request oil level/oil pressure indicator lamp";
CM_ SG_ 672 OIL_TEMP_IND_RQ "Engine oil overtemp. indicator request";
CM_ SG_ 672 OIL_TEMP_CHM_RQ "Engine oil overtemp. chime request";
CM_ SG_ 672 ChkFuelCap "Check fuel cap";
CM_ SG_ 672 OIL_PRESS "Oil pressure";
CM_ SG_ 672 EngOilTemp "Oil temperature";
CM_ SG_ 672 FuelCons "Fuel consumption";
CM_ SG_ 672 DefFuelEcon "Default fuel economy";
CM_ SG_ 672 EngRun_Stat "Engine running state";
CM_ SG_ 672 RedntHdStat "Redundant Hood Status";
BA_DEF_ SG_  "GenSigTimeout_ADCM" INT 0 65535;
BA_DEF_ SG_  "GenSigTimeout_AFLS" INT 0 65535;
BA_DEF_ SG_  "GenSigTimeout_CBC" INT 0 65535;
BA_DEF_ SG_  "GenSigTimeout_DTCM" INT 0 65535;
BA_DEF_ SG_  "GenSigTimeout_ECM" INT 0 65535;
BA_DEF_ SG_  "GenSigTimeout_EPS" INT 0 65535;
BA_DEF_ SG_  "GenSigTimeout_ESC" INT 0 65535;
BA_DEF_ SG_  "GenSigTimeout_ESM" INT 0 65535;
BA_DEF_ SG_  "GenSigTimeout_ETM" INT 0 65535;
BA_DEF_ SG_  "GenSigTimeout_HaLF" INT 0 65535;
BA_DEF_ SG_  "GenSigTimeout_IC" INT 0 65535;
BA_DEF_ SG_  "GenSigTimeout_ORC" INT 0 65535;
BA_DEF_ SG_  "GenSigTimeout_PTS" INT 0 65535;
BA_DEF_ SG_  "GenSigTimeout_RF_HUB" INT 0 65535;
BA_DEF_ SG_  "GenSigTimeout_SCCM" INT 0 65535;
BA_DEF_ SG_  "GenSigTimeout_TPM" INT 0 65535;
BA_DEF_ BO_  "GenMsgStartValue" STRING ;
BA_DEF_ SG_  "GenSigSNA" STRING ;
BA_DEF_ SG_  "FlexKomIsMotorola" ENUM  "nein","ja";
BA_DEF_ SG_  "FlexKomSigLaenge" INT 0 64;
BA_DEF_ SG_  "FlexKomSigStartPos" INT 0 63;
BA_DEF_ SG_  "FlexKomComment" STRING ;
BA_DEF_ SG_  "FlexKomSigName" STRING ;
BA_DEF_ SG_  "FlexKomSID" INT 0 2147483647;
BA_DEF_ SG_  "GenSigStartValue" HEX 0 4294967295;
BA_DEF_ SG_  "FlexKomSigStartValue" STRING ;
BA_DEF_ SG_  "GenSigCycleTimeActive" INT 0 65535;
BA_DEF_ SG_  "GenSigCycleTime" INT 0 65535;
BA_DEF_ SG_  "GenSigSendType" ENUM  "cyclicX","spontanX","cyclicIfActiveX","spontanWithDelay","cyclicAndSpontanX","cyclicAndSpontanWithDelay","spontanWithRepitition","cyclicIfActiveAndSpontanWD","cyclicIfActiveFast","cyclicWithRepeatOnDemand","none";
BA_DEF_ BO_  "GenMsgNrOfRepetitions" INT 0 65535;
BA_DEF_ BO_  "GenMsgDelayTime" INT 0 65535;
BA_DEF_ BO_  "GenMsgStartDelayTime" INT 0 65535;
BA_DEF_ BO_  "GenMsgCycleTimeActive" INT 0 65535;
BA_DEF_ BO_  "GenMsgCycleTime" INT 0 65535;
BA_DEF_ BO_  "GenMsgSendType" ENUM  "cyclicX","spontanX","cyclicIfActiveX","spontanWithDelay","cyclicAndSpontanX","cyclicAndSpontanWithDelay","spontanWithRepitition","cyclicIfActiveAndSpontanWD","cyclicIfActiveFast","cyclicWithRepeatOnDemand","none";
BA_DEF_ BO_  "DiagResponse" ENUM  "nein","ja";
BA_DEF_ BO_  "DiagRequest" ENUM  "nein","ja";
BA_DEF_ BO_  "DiagState" ENUM  "nein","ja";
BA_DEF_ BO_  "App-Botschaft" ENUM  "nein","ja";
BA_DEF_ BO_  "NWM-Botschaft" ENUM  "nein","ja";
BA_DEF_DEF_  "GenSigTimeout_ADCM" 0;
BA_DEF_DEF_  "GenSigTimeout_AFLS" 0;
BA_DEF_DEF_  "GenSigTimeout_CBC" 0;
BA_DEF_DEF_  "GenSigTimeout_DTCM" 0;
BA_DEF_DEF_  "GenSigTimeout_ECM" 0;
BA_DEF_DEF_  "GenSigTimeout_EPS" 0;
BA_DEF_DEF_  "GenSigTimeout_ESC" 0;
BA_DEF_DEF_  "GenSigTimeout_ESM" 0;
BA_DEF_DEF_  "GenSigTimeout_ETM" 0;
BA_DEF_DEF_  "GenSigTimeout_HaLF" 0;
BA_DEF_DEF_  "GenSigTimeout_IC" 0;
BA_DEF_DEF_  "GenSigTimeout_ORC" 0;
BA_DEF_DEF_  "GenSigTimeout_PTS" 0;
BA_DEF_DEF_  "GenSigTimeout_RF_HUB" 0;
BA_DEF_DEF_  "GenSigTimeout_SCCM" 0;
BA_DEF_DEF_  "GenSigTimeout_TPM" 0;
BA_DEF_DEF_  "GenMsgStartValue" "";
BA_DEF_DEF_  "GenSigSNA" "";
BA_DEF_DEF_  "FlexKomIsMotorola" "nein";
BA_DEF_DEF_  "FlexKomSigLaenge" 0;
BA_DEF_DEF_  "FlexKomSigStartPos" 0;
BA_DEF_DEF_  "FlexKomComment" "";
BA_DEF_DEF_  "FlexKomSigName" "";
BA_DEF_DEF_  "FlexKomSID" 0;
BA_DEF_DEF_  "GenSigStartValue" 0;
BA_DEF_DEF_  "FlexKomSigStartValue" "";
BA_DEF_DEF_  "GenSigCycleTimeActive" 0;
BA_DEF_DEF_  "GenSigCycleTime" 0;
BA_DEF_DEF_  "GenSigSendType" "cyclicX";
BA_DEF_DEF_  "GenMsgNrOfRepetitions" 0;
BA_DEF_DEF_  "GenMsgDelayTime" 0;
BA_DEF_DEF_  "GenMsgStartDelayTime" 0;
BA_DEF_DEF_  "GenMsgCycleTimeActive" 0;
BA_DEF_DEF_  "GenMsgCycleTime" 0;
BA_DEF_DEF_  "GenMsgSendType" "cyclicX";
BA_DEF_DEF_  "DiagResponse" "nein";
BA_DEF_DEF_  "DiagRequest" "nein";
BA_DEF_DEF_  "DiagState" "nein";
BA_DEF_DEF_  "App-Botschaft" "nein";
BA_DEF_DEF_  "NWM-Botschaft" "nein";
BA_ "GenMsgCycleTime" BO_ 530 100;
BA_ "GenMsgDelayTime" BO_ 530 20;
BA_ "GenMsgNrOfRepetitions" BO_ 530 2;
BA_ "GenMsgStartValue" BO_ 530 "000F000000FF0000h";
BA_ "GenMsgCycleTime" BO_ 532 100;
BA_ "GenMsgDelayTime" BO_ 532 20;
BA_ "GenMsgNrOfRepetitions" BO_ 532 2;
BA_ "GenMsgStartValue" BO_ 532 "3FFFFFFFFF03FFC0h";
BA_ "GenMsgStartDelayTime" BO_ 532 10;
BA_ "GenMsgSendType" BO_ 536 5;
BA_ "GenMsgCycleTime" BO_ 536 500;
BA_ "GenMsgDelayTime" BO_ 536 20;
BA_ "GenMsgNrOfRepetitions" BO_ 536 2;
BA_ "GenMsgStartValue" BO_ 536 "00000000000F00FFh";
BA_ "GenMsgSendType" BO_ 542 9;
BA_ "GenMsgCycleTime" BO_ 542 100;
BA_ "GenMsgDelayTime" BO_ 542 100;
BA_ "GenMsgNrOfRepetitions" BO_ 542 3;
BA_ "GenMsgStartValue" BO_ 542 "0000000000000000h";
BA_ "GenMsgCycleTime" BO_ 544 10;
BA_ "GenMsgDelayTime" BO_ 544 20;
BA_ "GenMsgNrOfRepetitions" BO_ 544 2;
BA_ "GenMsgStartValue" BO_ 544 "07FF0FFF1C0000FFh";
BA_ "GenMsgSendType" BO_ 557 5;
BA_ "GenMsgCycleTime" BO_ 557 1000;
BA_ "GenMsgDelayTime" BO_ 557 20;
BA_ "GenMsgNrOfRepetitions" BO_ 557 2;
BA_ "GenMsgStartValue" BO_ 557 "FF00000000000000h";
BA_ "GenMsgStartDelayTime" BO_ 557 110;
BA_ "GenMsgCycleTime" BO_ 559 20;
BA_ "GenMsgDelayTime" BO_ 559 20;
BA_ "GenMsgNrOfRepetitions" BO_ 559 2;
BA_ "GenMsgStartValue" BO_ 559 "FFFFFFFF00000CFFh";
BA_ "GenMsgSendType" BO_ 560 5;
BA_ "GenMsgCycleTime" BO_ 560 500;
BA_ "GenMsgDelayTime" BO_ 560 20;
BA_ "GenMsgNrOfRepetitions" BO_ 560 2;
BA_ "GenMsgStartValue" BO_ 560 "08000000h";
BA_ "GenMsgCycleTime" BO_ 564 100;
BA_ "GenMsgDelayTime" BO_ 564 20;
BA_ "GenMsgNrOfRepetitions" BO_ 564 2;
BA_ "GenMsgStartValue" BO_ 564 "FF0300FFh";
BA_ "GenMsgStartDelayTime" BO_ 564 10;
BA_ "GenMsgCycleTime" BO_ 570 20;
BA_ "GenMsgDelayTime" BO_ 570 20;
BA_ "GenMsgNrOfRepetitions" BO_ 570 2;
BA_ "GenMsgStartValue" BO_ 570 "0000FFh";
BA_ "GenMsgSendType" BO_ 571 1;
BA_ "GenMsgDelayTime" BO_ 571 20;
BA_ "GenMsgNrOfRepetitions" BO_ 571 2;
BA_ "GenMsgStartValue" BO_ 571 "0000FFh";
BA_ "GenMsgSendType" BO_ 584 5;
BA_ "GenMsgCycleTime" BO_ 584 500;
BA_ "GenMsgDelayTime" BO_ 584 20;
BA_ "GenMsgNrOfRepetitions" BO_ 584 2;
BA_ "GenMsgStartValue" BO_ 584 "0000FFFFFF03FFFFh";
BA_ "GenMsgStartDelayTime" BO_ 584 70;
BA_ "GenMsgSendType" BO_ 608 5;
BA_ "GenMsgCycleTime" BO_ 608 500;
BA_ "GenMsgDelayTime" BO_ 608 20;
BA_ "GenMsgNrOfRepetitions" BO_ 608 2;
BA_ "GenMsgStartValue" BO_ 608 "FF80AAAAAAAA0AFFh";
BA_ "GenMsgSendType" BO_ 624 5;
BA_ "GenMsgCycleTime" BO_ 624 1000;
BA_ "GenMsgDelayTime" BO_ 624 20;
BA_ "GenMsgNrOfRepetitions" BO_ 624 2;
BA_ "GenMsgStartValue" BO_ 624 "0000000000000FFFh";
BA_ "GenMsgStartDelayTime" BO_ 624 40;
BA_ "GenMsgCycleTime" BO_ 632 100;
BA_ "GenMsgDelayTime" BO_ 632 20;
BA_ "GenMsgNrOfRepetitions" BO_ 632 2;
BA_ "GenMsgStartValue" BO_ 632 "FF00FFFF00FF0000h";
BA_ "GenMsgCycleTime" BO_ 639 1000;
BA_ "GenMsgDelayTime" BO_ 639 20;
BA_ "GenMsgNrOfRepetitions" BO_ 639 2;
BA_ "GenMsgStartValue" BO_ 639 "FFFFFFFF00000000h";
BA_ "GenMsgStartDelayTime" BO_ 639 90;
BA_ "GenMsgSendType" BO_ 640 2;
BA_ "GenMsgCycleTimeActive" BO_ 640 100;
BA_ "GenMsgDelayTime" BO_ 640 20;
BA_ "GenMsgNrOfRepetitions" BO_ 640 2;
BA_ "GenMsgStartValue" BO_ 640 "00h";
BA_ "GenMsgSendType" BO_ 656 1;
BA_ "GenMsgDelayTime" BO_ 656 20;
BA_ "GenMsgNrOfRepetitions" BO_ 656 2;
BA_ "GenMsgStartValue" BO_ 656 "00000000h";
BA_ "GenMsgCycleTime" BO_ 658 10;
BA_ "GenMsgDelayTime" BO_ 658 20;
BA_ "GenMsgNrOfRepetitions" BO_ 658 2;
BA_ "GenMsgStartValue" BO_ 658 "0000000000FFh";
BA_ "GenMsgCycleTime" BO_ 660 20;
BA_ "GenMsgDelayTime" BO_ 660 20;
BA_ "GenMsgNrOfRepetitions" BO_ 660 2;
BA_ "GenMsgStartValue" BO_ 660 "00000000C00000FFh";
BA_ "GenMsgCycleTime" BO_ 669 20;
BA_ "GenMsgDelayTime" BO_ 669 20;
BA_ "GenMsgNrOfRepetitions" BO_ 669 2;
BA_ "GenMsgStartValue" BO_ 669 "0000FFh";
BA_ "GenMsgCycleTime" BO_ 671 20;
BA_ "GenMsgDelayTime" BO_ 671 20;
BA_ "GenMsgNrOfRepetitions" BO_ 671 2;
BA_ "GenMsgStartValue" BO_ 671 "00000000000000FFh";
BA_ "GenMsgCycleTime" BO_ 672 100;
BA_ "GenMsgDelayTime" BO_ 672 20;
BA_ "GenMsgNrOfRepetitions" BO_ 672 2;
BA_ "GenMsgStartValue" BO_ 672 "6000FFFFFFFFFF07h";
BA_ "GenSigCycleTime" SG_ 530 DEF_LOW 100;
BA_ "FlexKomSigStartValue" SG_ 530 DEF_LOW "000Fh";
BA_ "GenSigTimeout_IC" SG_ 530 DEF_LOW 1050;
BA_ "FlexKomSID" SG_ 530 DEF_LOW 1726;
BA_ "FlexKomSigStartPos" SG_ 530 DEF_LOW 7;
BA_ "FlexKomSigLaenge" SG_ 530 DEF_LOW 16;
BA_ "FlexKomSigName" SG_ 530 DEF_LOW "DEF_DPF_Pkt";
BA_ "FlexKomComment" SG_ 530 DEF_LOW "Exhaust fuel and particulate filter packet";
BA_ "FlexKomIsMotorola" SG_ 530 DEF_LOW 1;
BA_ "GenSigSNA" SG_ 530 DEF_LOW "3h";
BA_ "GenSigCycleTime" SG_ 530 PFW_Stat 100;
BA_ "FlexKomSigStartValue" SG_ 530 PFW_Stat "000Fh";
BA_ "GenSigTimeout_IC" SG_ 530 PFW_Stat 1050;
BA_ "FlexKomSID" SG_ 530 PFW_Stat 1726;
BA_ "FlexKomSigStartPos" SG_ 530 PFW_Stat 7;
BA_ "FlexKomSigLaenge" SG_ 530 PFW_Stat 16;
BA_ "FlexKomSigName" SG_ 530 PFW_Stat "DEF_DPF_Pkt";
BA_ "FlexKomComment" SG_ 530 PFW_Stat "Exhaust fuel and particulate filter packet";
BA_ "FlexKomIsMotorola" SG_ 530 PFW_Stat 1;
BA_ "GenSigSNA" SG_ 530 PFW_Stat "Fh";
BA_ "GenSigCycleTime" SG_ 530 PrcntCplt 100;
BA_ "FlexKomSigStartValue" SG_ 530 PrcntCplt "000Fh";
BA_ "GenSigStartValue" SG_ 530 PrcntCplt 15;
BA_ "GenSigTimeout_IC" SG_ 530 PrcntCplt 1050;
BA_ "FlexKomSID" SG_ 530 PrcntCplt 1726;
BA_ "FlexKomSigStartPos" SG_ 530 PrcntCplt 7;
BA_ "FlexKomSigLaenge" SG_ 530 PrcntCplt 16;
BA_ "FlexKomSigName" SG_ 530 PrcntCplt "DEF_DPF_Pkt";
BA_ "FlexKomComment" SG_ 530 PrcntCplt "Exhaust fuel and particulate filter packet";
BA_ "FlexKomIsMotorola" SG_ 530 PrcntCplt 1;
BA_ "GenSigSNA" SG_ 530 PrcntCplt "Fh";
BA_ "GenSigCycleTime" SG_ 530 FuelFltrHtrReq 100;
BA_ "FlexKomSigStartValue" SG_ 530 FuelFltrHtrReq "00h";
BA_ "GenSigTimeout_CBC" SG_ 530 FuelFltrHtrReq 1050;
BA_ "FlexKomSID" SG_ 530 FuelFltrHtrReq 1915;
BA_ "FlexKomSigStartPos" SG_ 530 FuelFltrHtrReq 14;
BA_ "FlexKomSigLaenge" SG_ 530 FuelFltrHtrReq 2;
BA_ "FlexKomSigName" SG_ 530 FuelFltrHtrReq "FuelFltrHtrReq";
BA_ "FlexKomComment" SG_ 530 FuelFltrHtrReq "Fuel filter heater request on";
BA_ "FlexKomIsMotorola" SG_ 530 FuelFltrHtrReq 1;
BA_ "GenSigSNA" SG_ 530 FuelFltrHtrReq "3h";
BA_ "GenSigCycleTime" SG_ 530 EngChmRq 100;
BA_ "FlexKomSigStartValue" SG_ 530 EngChmRq "00h";
BA_ "GenSigTimeout_IC" SG_ 530 EngChmRq 1050;
BA_ "FlexKomSID" SG_ 530 EngChmRq 1864;
BA_ "FlexKomSigStartPos" SG_ 530 EngChmRq 15;
BA_ "FlexKomSigLaenge" SG_ 530 EngChmRq 1;
BA_ "FlexKomSigName" SG_ 530 EngChmRq "EngChmRq";
BA_ "FlexKomComment" SG_ 530 EngChmRq "Engine chime request";
BA_ "FlexKomIsMotorola" SG_ 530 EngChmRq 1;
BA_ "GenSigSNA" SG_ 530 EngChmRq "0h";
BA_ "GenSigCycleTime" SG_ 530 ECM_HMI_Timer_RQ 100;
BA_ "FlexKomSigStartValue" SG_ 530 ECM_HMI_Timer_RQ "00h";
BA_ "GenSigTimeout_IC" SG_ 530 ECM_HMI_Timer_RQ 1050;
BA_ "FlexKomSID" SG_ 530 ECM_HMI_Timer_RQ 1727;
BA_ "FlexKomSigStartPos" SG_ 530 ECM_HMI_Timer_RQ 18;
BA_ "FlexKomSigLaenge" SG_ 530 ECM_HMI_Timer_RQ 3;
BA_ "FlexKomSigName" SG_ 530 ECM_HMI_Timer_RQ "ECM_HMI_Timer_RQ";
BA_ "FlexKomComment" SG_ 530 ECM_HMI_Timer_RQ "DEF and DPF warning re-launch timer request";
BA_ "FlexKomIsMotorola" SG_ 530 ECM_HMI_Timer_RQ 1;
BA_ "GenSigSNA" SG_ 530 ECM_HMI_Timer_RQ "7h";
BA_ "GenSigCycleTime" SG_ 530 PreHtIndLmp_On_Rq 100;
BA_ "FlexKomSigStartValue" SG_ 530 PreHtIndLmp_On_Rq "00h";
BA_ "GenSigTimeout_IC" SG_ 530 PreHtIndLmp_On_Rq 1050;
BA_ "GenSigTimeout_ETM" SG_ 530 PreHtIndLmp_On_Rq 1050;
BA_ "FlexKomSID" SG_ 530 PreHtIndLmp_On_Rq 720;
BA_ "FlexKomSigStartPos" SG_ 530 PreHtIndLmp_On_Rq 19;
BA_ "FlexKomSigLaenge" SG_ 530 PreHtIndLmp_On_Rq 1;
BA_ "FlexKomSigName" SG_ 530 PreHtIndLmp_On_Rq "PreHtIndLmp_On_Rq";
BA_ "FlexKomComment" SG_ 530 PreHtIndLmp_On_Rq "Request glow-plug (wait to start) lamp";
BA_ "FlexKomIsMotorola" SG_ 530 PreHtIndLmp_On_Rq 1;
BA_ "GenSigSNA" SG_ 530 PreHtIndLmp_On_Rq "0h";
BA_ "GenSigCycleTime" SG_ 530 EngOilTemp_Above_Max 100;
BA_ "FlexKomSigStartValue" SG_ 530 EngOilTemp_Above_Max "00h";
BA_ "GenSigTimeout_IC" SG_ 530 EngOilTemp_Above_Max 1050;
BA_ "FlexKomSID" SG_ 530 EngOilTemp_Above_Max 439;
BA_ "FlexKomSigStartPos" SG_ 530 EngOilTemp_Above_Max 20;
BA_ "FlexKomSigLaenge" SG_ 530 EngOilTemp_Above_Max 1;
BA_ "FlexKomSigName" SG_ 530 EngOilTemp_Above_Max "EngOilTemp_Above_Max";
BA_ "FlexKomComment" SG_ 530 EngOilTemp_Above_Max "Engine oil temperature too high (overheating)";
BA_ "FlexKomIsMotorola" SG_ 530 EngOilTemp_Above_Max 1;
BA_ "GenSigSNA" SG_ 530 EngOilTemp_Above_Max "1h";
BA_ "GenSigCycleTime" SG_ 530 PTC_REL1_RQ 100;
BA_ "FlexKomSigStartValue" SG_ 530 PTC_REL1_RQ "00h";
BA_ "FlexKomSID" SG_ 530 PTC_REL1_RQ 721;
BA_ "FlexKomSigStartPos" SG_ 530 PTC_REL1_RQ 23;
BA_ "FlexKomSigLaenge" SG_ 530 PTC_REL1_RQ 3;
BA_ "FlexKomSigName" SG_ 530 PTC_REL1_RQ "PTC_REL_RQ";
BA_ "FlexKomComment" SG_ 530 PTC_REL1_RQ "PTC relay requests";
BA_ "FlexKomIsMotorola" SG_ 530 PTC_REL1_RQ 1;
BA_ "GenSigSNA" SG_ 530 PTC_REL1_RQ "0h";
BA_ "GenSigCycleTime" SG_ 530 PTC_REL2_RQ 100;
BA_ "FlexKomSigStartValue" SG_ 530 PTC_REL2_RQ "00h";
BA_ "FlexKomSID" SG_ 530 PTC_REL2_RQ 721;
BA_ "FlexKomSigStartPos" SG_ 530 PTC_REL2_RQ 23;
BA_ "FlexKomSigLaenge" SG_ 530 PTC_REL2_RQ 3;
BA_ "FlexKomSigName" SG_ 530 PTC_REL2_RQ "PTC_REL_RQ";
BA_ "FlexKomComment" SG_ 530 PTC_REL2_RQ "PTC relay requests";
BA_ "FlexKomIsMotorola" SG_ 530 PTC_REL2_RQ 1;
BA_ "GenSigSNA" SG_ 530 PTC_REL2_RQ "0h";
BA_ "GenSigCycleTime" SG_ 530 PTC_REL3_RQ 100;
BA_ "FlexKomSigStartValue" SG_ 530 PTC_REL3_RQ "00h";
BA_ "FlexKomSID" SG_ 530 PTC_REL3_RQ 721;
BA_ "FlexKomSigStartPos" SG_ 530 PTC_REL3_RQ 23;
BA_ "FlexKomSigLaenge" SG_ 530 PTC_REL3_RQ 3;
BA_ "FlexKomSigName" SG_ 530 PTC_REL3_RQ "PTC_REL_RQ";
BA_ "FlexKomComment" SG_ 530 PTC_REL3_RQ "PTC relay requests";
BA_ "FlexKomIsMotorola" SG_ 530 PTC_REL3_RQ 1;
BA_ "GenSigSNA" SG_ 530 PTC_REL3_RQ "0h";
BA_ "GenSigCycleTime" SG_ 530 PFW 100;
BA_ "FlexKomSigStartValue" SG_ 530 PFW "00h";
BA_ "GenSigTimeout_IC" SG_ 530 PFW 1050;
BA_ "GenSigTimeout_ETM" SG_ 530 PFW 1050;
BA_ "FlexKomSID" SG_ 530 PFW 1108;
BA_ "FlexKomSigStartPos" SG_ 530 PFW 25;
BA_ "FlexKomSigLaenge" SG_ 530 PFW 2;
BA_ "FlexKomSigName" SG_ 530 PFW "PFW";
BA_ "FlexKomComment" SG_ 530 PFW "Particulate filter warning";
BA_ "FlexKomIsMotorola" SG_ 530 PFW 1;
BA_ "GenSigSNA" SG_ 530 PFW "3h";
BA_ "GenSigCycleTime" SG_ 530 ParticleFltrCorrOffset 100;
BA_ "FlexKomSigStartValue" SG_ 530 ParticleFltrCorrOffset "00h";
BA_ "FlexKomSID" SG_ 530 ParticleFltrCorrOffset 768;
BA_ "FlexKomSigStartPos" SG_ 530 ParticleFltrCorrOffset 29;
BA_ "FlexKomSigLaenge" SG_ 530 ParticleFltrCorrOffset 4;
BA_ "FlexKomSigName" SG_ 530 ParticleFltrCorrOffset "ParticleFltrCorrOffset";
BA_ "FlexKomComment" SG_ 530 ParticleFltrCorrOffset "Particulate Filter Corection Offset SLP_MS_OFS";
BA_ "FlexKomIsMotorola" SG_ 530 ParticleFltrCorrOffset 1;
BA_ "GenSigSNA" SG_ 530 ParticleFltrCorrOffset "Fh";
BA_ "GenSigCycleTime" SG_ 530 WtrFuelIndLmp_On_Rq 100;
BA_ "FlexKomSigStartValue" SG_ 530 WtrFuelIndLmp_On_Rq "00h";
BA_ "GenSigTimeout_IC" SG_ 530 WtrFuelIndLmp_On_Rq 1050;
BA_ "GenSigTimeout_ETM" SG_ 530 WtrFuelIndLmp_On_Rq 1050;
BA_ "FlexKomSID" SG_ 530 WtrFuelIndLmp_On_Rq 1109;
BA_ "FlexKomSigStartPos" SG_ 530 WtrFuelIndLmp_On_Rq 30;
BA_ "FlexKomSigLaenge" SG_ 530 WtrFuelIndLmp_On_Rq 1;
BA_ "FlexKomSigName" SG_ 530 WtrFuelIndLmp_On_Rq "WtrFuelIndLmp_On_Rq";
BA_ "FlexKomComment" SG_ 530 WtrFuelIndLmp_On_Rq "Request water in fuel lamp (diesel only)";
BA_ "FlexKomIsMotorola" SG_ 530 WtrFuelIndLmp_On_Rq 1;
BA_ "GenSigSNA" SG_ 530 WtrFuelIndLmp_On_Rq "0h";
BA_ "GenSigCycleTime" SG_ 530 PF_RgnActv 100;
BA_ "FlexKomSigStartValue" SG_ 530 PF_RgnActv "00h";
BA_ "FlexKomSID" SG_ 530 PF_RgnActv 1643;
BA_ "FlexKomSigStartPos" SG_ 530 PF_RgnActv 31;
BA_ "FlexKomSigLaenge" SG_ 530 PF_RgnActv 1;
BA_ "FlexKomSigName" SG_ 530 PF_RgnActv "PF_RgnActv";
BA_ "FlexKomComment" SG_ 530 PF_RgnActv "Particulate filter regeneration active";
BA_ "FlexKomIsMotorola" SG_ 530 PF_RgnActv 1;
BA_ "GenSigSNA" SG_ 530 PF_RgnActv "0h";
BA_ "GenSigCycleTime" SG_ 530 Adblue_Stat 100;
BA_ "FlexKomSigStartValue" SG_ 530 Adblue_Stat "00FF0000h";
BA_ "GenSigTimeout_IC" SG_ 530 Adblue_Stat 1050;
BA_ "FlexKomSID" SG_ 530 Adblue_Stat 1436;
BA_ "FlexKomSigStartPos" SG_ 530 Adblue_Stat 39;
BA_ "FlexKomSigLaenge" SG_ 530 Adblue_Stat 32;
BA_ "FlexKomSigName" SG_ 530 Adblue_Stat "AdblueDispRq";
BA_ "FlexKomComment" SG_ 530 Adblue_Stat "Adblue display request";
BA_ "FlexKomIsMotorola" SG_ 530 Adblue_Stat 1;
BA_ "GenSigSNA" SG_ 530 Adblue_Stat "3Fh";
BA_ "GenSigCycleTime" SG_ 530 RemainDistUnt 100;
BA_ "FlexKomSigStartValue" SG_ 530 RemainDistUnt "00FF0000h";
BA_ "GenSigTimeout_IC" SG_ 530 RemainDistUnt 1050;
BA_ "FlexKomSID" SG_ 530 RemainDistUnt 1436;
BA_ "FlexKomSigStartPos" SG_ 530 RemainDistUnt 39;
BA_ "FlexKomSigLaenge" SG_ 530 RemainDistUnt 32;
BA_ "FlexKomSigName" SG_ 530 RemainDistUnt "AdblueDispRq";
BA_ "FlexKomComment" SG_ 530 RemainDistUnt "Adblue display request";
BA_ "FlexKomIsMotorola" SG_ 530 RemainDistUnt 1;
BA_ "GenSigSNA" SG_ 530 RemainDistUnt "0h";
BA_ "GenSigCycleTime" SG_ 530 Adblue_FL_LVL 100;
BA_ "FlexKomSigStartValue" SG_ 530 Adblue_FL_LVL "00FF0000h";
BA_ "GenSigStartValue" SG_ 530 Adblue_FL_LVL 255;
BA_ "FlexKomSID" SG_ 530 Adblue_FL_LVL 1436;
BA_ "FlexKomSigStartPos" SG_ 530 Adblue_FL_LVL 39;
BA_ "FlexKomSigLaenge" SG_ 530 Adblue_FL_LVL 32;
BA_ "FlexKomSigName" SG_ 530 Adblue_FL_LVL "AdblueDispRq";
BA_ "FlexKomComment" SG_ 530 Adblue_FL_LVL "Adblue display request";
BA_ "FlexKomIsMotorola" SG_ 530 Adblue_FL_LVL 1;
BA_ "GenSigSNA" SG_ 530 Adblue_FL_LVL "FFh";
BA_ "GenSigCycleTime" SG_ 530 AdblueRemainDist 100;
BA_ "FlexKomSigStartValue" SG_ 530 AdblueRemainDist "00FF0000h";
BA_ "GenSigTimeout_IC" SG_ 530 AdblueRemainDist 1050;
BA_ "FlexKomSID" SG_ 530 AdblueRemainDist 1436;
BA_ "FlexKomSigStartPos" SG_ 530 AdblueRemainDist 39;
BA_ "FlexKomSigLaenge" SG_ 530 AdblueRemainDist 32;
BA_ "FlexKomSigName" SG_ 530 AdblueRemainDist "AdblueDispRq";
BA_ "FlexKomComment" SG_ 530 AdblueRemainDist "Adblue display request";
BA_ "FlexKomIsMotorola" SG_ 530 AdblueRemainDist 1;
BA_ "GenSigSNA" SG_ 530 AdblueRemainDist "FFFFh";
BA_ "GenSigCycleTime" SG_ 532 IBS_V_BATT 100;
BA_ "FlexKomSigStartValue" SG_ 532 IBS_V_BATT "3FFFFFFFFF03FFC0h";
BA_ "GenSigStartValue" SG_ 532 IBS_V_BATT 16383;
BA_ "FlexKomSID" SG_ 532 IBS_V_BATT 1094;
BA_ "FlexKomSigStartPos" SG_ 532 IBS_V_BATT 7;
BA_ "FlexKomSigLaenge" SG_ 532 IBS_V_BATT 64;
BA_ "FlexKomSigName" SG_ 532 IBS_V_BATT "PN14_IBS_DATA";
BA_ "FlexKomComment" SG_ 532 IBS_V_BATT "IBS Battery Information";
BA_ "FlexKomIsMotorola" SG_ 532 IBS_V_BATT 1;
BA_ "GenSigSNA" SG_ 532 IBS_V_BATT "3FFFh";
BA_ "GenSigCycleTime" SG_ 532 IBS_I_BATT 100;
BA_ "FlexKomSigStartValue" SG_ 532 IBS_I_BATT "3FFFFFFFFF03FFC0h";
BA_ "GenSigStartValue" SG_ 532 IBS_I_BATT 65535;
BA_ "FlexKomSID" SG_ 532 IBS_I_BATT 1094;
BA_ "FlexKomSigStartPos" SG_ 532 IBS_I_BATT 7;
BA_ "FlexKomSigLaenge" SG_ 532 IBS_I_BATT 64;
BA_ "FlexKomSigName" SG_ 532 IBS_I_BATT "PN14_IBS_DATA";
BA_ "FlexKomComment" SG_ 532 IBS_I_BATT "IBS Battery Information";
BA_ "FlexKomIsMotorola" SG_ 532 IBS_I_BATT 1;
BA_ "GenSigSNA" SG_ 532 IBS_I_BATT "FFFFh";
BA_ "GenSigCycleTime" SG_ 532 IBS_T_BATT 100;
BA_ "FlexKomSigStartValue" SG_ 532 IBS_T_BATT "3FFFFFFFFF03FFC0h";
BA_ "GenSigStartValue" SG_ 532 IBS_T_BATT 255;
BA_ "FlexKomSID" SG_ 532 IBS_T_BATT 1094;
BA_ "FlexKomSigStartPos" SG_ 532 IBS_T_BATT 7;
BA_ "FlexKomSigLaenge" SG_ 532 IBS_T_BATT 64;
BA_ "FlexKomSigName" SG_ 532 IBS_T_BATT "PN14_IBS_DATA";
BA_ "FlexKomComment" SG_ 532 IBS_T_BATT "IBS Battery Information";
BA_ "FlexKomIsMotorola" SG_ 532 IBS_T_BATT 1;
BA_ "GenSigSNA" SG_ 532 IBS_T_BATT "FFh";
BA_ "GenSigCycleTime" SG_ 532 IBS_PreWakeupVoltage 100;
BA_ "FlexKomSigStartValue" SG_ 532 IBS_PreWakeupVoltage "3FFFFFFFFF03FFC0h";
BA_ "GenSigStartValue" SG_ 532 IBS_PreWakeupVoltage 1023;
BA_ "FlexKomSID" SG_ 532 IBS_PreWakeupVoltage 1094;
BA_ "FlexKomSigStartPos" SG_ 532 IBS_PreWakeupVoltage 7;
BA_ "FlexKomSigLaenge" SG_ 532 IBS_PreWakeupVoltage 64;
BA_ "FlexKomSigName" SG_ 532 IBS_PreWakeupVoltage "PN14_IBS_DATA";
BA_ "FlexKomComment" SG_ 532 IBS_PreWakeupVoltage "IBS Battery Information";
BA_ "FlexKomIsMotorola" SG_ 532 IBS_PreWakeupVoltage 1;
BA_ "GenSigSNA" SG_ 532 IBS_PreWakeupVoltage "3FFh";
BA_ "GenSigCycleTime" SG_ 532 IBS_Current_Status 100;
BA_ "FlexKomSigStartValue" SG_ 532 IBS_Current_Status "3FFFFFFFFF03FFC0h";
BA_ "FlexKomSID" SG_ 532 IBS_Current_Status 1094;
BA_ "FlexKomSigStartPos" SG_ 532 IBS_Current_Status 7;
BA_ "FlexKomSigLaenge" SG_ 532 IBS_Current_Status 64;
BA_ "FlexKomSigName" SG_ 532 IBS_Current_Status "PN14_IBS_DATA";
BA_ "FlexKomComment" SG_ 532 IBS_Current_Status "IBS Battery Information";
BA_ "FlexKomIsMotorola" SG_ 532 IBS_Current_Status 1;
BA_ "GenSigSNA" SG_ 532 IBS_Current_Status "0h";
BA_ "GenSigCycleTime" SG_ 532 IBS_Voltage_Status 100;
BA_ "FlexKomSigStartValue" SG_ 532 IBS_Voltage_Status "3FFFFFFFFF03FFC0h";
BA_ "FlexKomSID" SG_ 532 IBS_Voltage_Status 1094;
BA_ "FlexKomSigStartPos" SG_ 532 IBS_Voltage_Status 7;
BA_ "FlexKomSigLaenge" SG_ 532 IBS_Voltage_Status 64;
BA_ "FlexKomSigName" SG_ 532 IBS_Voltage_Status "PN14_IBS_DATA";
BA_ "FlexKomComment" SG_ 532 IBS_Voltage_Status "IBS Battery Information";
BA_ "FlexKomIsMotorola" SG_ 532 IBS_Voltage_Status 1;
BA_ "GenSigSNA" SG_ 532 IBS_Voltage_Status "0h";
BA_ "GenSigCycleTime" SG_ 532 IBS_Temp_Status 100;
BA_ "FlexKomSigStartValue" SG_ 532 IBS_Temp_Status "3FFFFFFFFF03FFC0h";
BA_ "FlexKomSID" SG_ 532 IBS_Temp_Status 1094;
BA_ "FlexKomSigStartPos" SG_ 532 IBS_Temp_Status 7;
BA_ "FlexKomSigLaenge" SG_ 532 IBS_Temp_Status 64;
BA_ "FlexKomSigName" SG_ 532 IBS_Temp_Status "PN14_IBS_DATA";
BA_ "FlexKomComment" SG_ 532 IBS_Temp_Status "IBS Battery Information";
BA_ "FlexKomIsMotorola" SG_ 532 IBS_Temp_Status 1;
BA_ "GenSigSNA" SG_ 532 IBS_Temp_Status "0h";
BA_ "GenSigCycleTime" SG_ 532 IBS_I_RANGE 100;
BA_ "FlexKomSigStartValue" SG_ 532 IBS_I_RANGE "3FFFFFFFFF03FFC0h";
BA_ "GenSigStartValue" SG_ 532 IBS_I_RANGE 3;
BA_ "FlexKomSID" SG_ 532 IBS_I_RANGE 1094;
BA_ "FlexKomSigStartPos" SG_ 532 IBS_I_RANGE 7;
BA_ "FlexKomSigLaenge" SG_ 532 IBS_I_RANGE 64;
BA_ "FlexKomSigName" SG_ 532 IBS_I_RANGE "PN14_IBS_DATA";
BA_ "FlexKomComment" SG_ 532 IBS_I_RANGE "IBS Battery Information";
BA_ "FlexKomIsMotorola" SG_ 532 IBS_I_RANGE 1;
BA_ "GenSigSNA" SG_ 532 IBS_I_RANGE "3h";
BA_ "GenSigSendType" SG_ 536 Presf_Enbl 5;
BA_ "GenSigCycleTime" SG_ 536 Presf_Enbl 500;
BA_ "FlexKomSigStartValue" SG_ 536 Presf_Enbl "000F00FFh";
BA_ "FlexKomSID" SG_ 536 Presf_Enbl 10;
BA_ "FlexKomSigStartPos" SG_ 536 Presf_Enbl 39;
BA_ "FlexKomSigLaenge" SG_ 536 Presf_Enbl 32;
BA_ "FlexKomSigName" SG_ 536 Presf_Enbl "PresfCtrl_ESP";
BA_ "FlexKomComment" SG_ 536 Presf_Enbl "Presafe control";
BA_ "FlexKomIsMotorola" SG_ 536 Presf_Enbl 1;
BA_ "GenSigSNA" SG_ 536 Presf_Enbl "0h";
BA_ "GenSigSendType" SG_ 536 Presf_Lvl 5;
BA_ "GenSigCycleTime" SG_ 536 Presf_Lvl 500;
BA_ "FlexKomSigStartValue" SG_ 536 Presf_Lvl "000F00FFh";
BA_ "GenSigStartValue" SG_ 536 Presf_Lvl 15;
BA_ "FlexKomSID" SG_ 536 Presf_Lvl 10;
BA_ "FlexKomSigStartPos" SG_ 536 Presf_Lvl 39;
BA_ "FlexKomSigLaenge" SG_ 536 Presf_Lvl 32;
BA_ "FlexKomSigName" SG_ 536 Presf_Lvl "PresfCtrl_ESP";
BA_ "FlexKomComment" SG_ 536 Presf_Lvl "Presafe control";
BA_ "FlexKomIsMotorola" SG_ 536 Presf_Lvl 1;
BA_ "GenSigSNA" SG_ 536 Presf_Lvl "Fh";
BA_ "GenSigSendType" SG_ 536 MC_PRESF_CTRL_ESP 5;
BA_ "GenSigCycleTime" SG_ 536 MC_PRESF_CTRL_ESP 500;
BA_ "FlexKomSigStartValue" SG_ 536 MC_PRESF_CTRL_ESP "000F00FFh";
BA_ "FlexKomSID" SG_ 536 MC_PRESF_CTRL_ESP 10;
BA_ "FlexKomSigStartPos" SG_ 536 MC_PRESF_CTRL_ESP 39;
BA_ "FlexKomSigLaenge" SG_ 536 MC_PRESF_CTRL_ESP 32;
BA_ "FlexKomSigName" SG_ 536 MC_PRESF_CTRL_ESP "PresfCtrl_ESP";
BA_ "FlexKomComment" SG_ 536 MC_PRESF_CTRL_ESP "Presafe control";
BA_ "FlexKomIsMotorola" SG_ 536 MC_PRESF_CTRL_ESP 1;
BA_ "GenSigSNA" SG_ 536 MC_PRESF_CTRL_ESP "0h";
BA_ "GenSigSendType" SG_ 536 CRC_PRESF_CTRL_ESP 5;
BA_ "GenSigCycleTime" SG_ 536 CRC_PRESF_CTRL_ESP 500;
BA_ "FlexKomSigStartValue" SG_ 536 CRC_PRESF_CTRL_ESP "000F00FFh";
BA_ "GenSigStartValue" SG_ 536 CRC_PRESF_CTRL_ESP 255;
BA_ "FlexKomSID" SG_ 536 CRC_PRESF_CTRL_ESP 10;
BA_ "FlexKomSigStartPos" SG_ 536 CRC_PRESF_CTRL_ESP 39;
BA_ "FlexKomSigLaenge" SG_ 536 CRC_PRESF_CTRL_ESP 32;
BA_ "FlexKomSigName" SG_ 536 CRC_PRESF_CTRL_ESP "PresfCtrl_ESP";
BA_ "FlexKomComment" SG_ 536 CRC_PRESF_CTRL_ESP "Presafe control";
BA_ "FlexKomIsMotorola" SG_ 536 CRC_PRESF_CTRL_ESP 1;
BA_ "GenSigSNA" SG_ 536 CRC_PRESF_CTRL_ESP "FFh";
BA_ "GenSigSendType" SG_ 542 BlockOffset 9;
BA_ "GenSigCycleTime" SG_ 542 BlockOffset 100;
BA_ "FlexKomSigStartValue" SG_ 542 BlockOffset "0000000000000000h";
BA_ "FlexKomSID" SG_ 542 BlockOffset 1588;
BA_ "FlexKomSigStartPos" SG_ 542 BlockOffset 7;
BA_ "FlexKomSigLaenge" SG_ 542 BlockOffset 64;
BA_ "FlexKomSigName" SG_ 542 BlockOffset "ORC_YRS_INFO";
BA_ "FlexKomComment" SG_ 542 BlockOffset "Traceability - part number information packet";
BA_ "FlexKomIsMotorola" SG_ 542 BlockOffset 1;
BA_ "GenSigSNA" SG_ 542 BlockOffset "0h";
BA_ "GenSigSendType" SG_ 542 PTRInfo 9;
BA_ "GenSigCycleTime" SG_ 542 PTRInfo 100;
BA_ "FlexKomSigStartValue" SG_ 542 PTRInfo "0000000000000000h";
BA_ "FlexKomSID" SG_ 542 PTRInfo 1588;
BA_ "FlexKomSigStartPos" SG_ 542 PTRInfo 7;
BA_ "FlexKomSigLaenge" SG_ 542 PTRInfo 64;
BA_ "FlexKomSigName" SG_ 542 PTRInfo "ORC_YRS_INFO";
BA_ "FlexKomComment" SG_ 542 PTRInfo "Traceability - part number information packet";
BA_ "FlexKomIsMotorola" SG_ 542 PTRInfo 1;
BA_ "GenSigSNA" SG_ 542 PTRInfo "0h";
BA_ "GenSigSendType" SG_ 542 CLUType 9;
BA_ "GenSigCycleTime" SG_ 542 CLUType 100;
BA_ "FlexKomSigStartValue" SG_ 542 CLUType "0000000000000000h";
BA_ "FlexKomSID" SG_ 542 CLUType 1588;
BA_ "FlexKomSigStartPos" SG_ 542 CLUType 7;
BA_ "FlexKomSigLaenge" SG_ 542 CLUType 64;
BA_ "FlexKomSigName" SG_ 542 CLUType "ORC_YRS_INFO";
BA_ "FlexKomComment" SG_ 542 CLUType "Traceability - part number information packet";
BA_ "FlexKomIsMotorola" SG_ 542 CLUType 1;
BA_ "GenSigSNA" SG_ 542 CLUType "0h";
BA_ "GenSigSendType" SG_ 542 Character5 9;
BA_ "GenSigCycleTime" SG_ 542 Character5 100;
BA_ "FlexKomSigStartValue" SG_ 542 Character5 "0000000000000000h";
BA_ "FlexKomSID" SG_ 542 Character5 1588;
BA_ "FlexKomSigStartPos" SG_ 542 Character5 7;
BA_ "FlexKomSigLaenge" SG_ 542 Character5 64;
BA_ "FlexKomSigName" SG_ 542 Character5 "ORC_YRS_INFO";
BA_ "FlexKomComment" SG_ 542 Character5 "Traceability - part number information packet";
BA_ "FlexKomIsMotorola" SG_ 542 Character5 1;
BA_ "GenSigSNA" SG_ 542 Character5 "0h";
BA_ "GenSigSendType" SG_ 542 Character4 9;
BA_ "GenSigCycleTime" SG_ 542 Character4 100;
BA_ "FlexKomSigStartValue" SG_ 542 Character4 "0000000000000000h";
BA_ "FlexKomSID" SG_ 542 Character4 1588;
BA_ "FlexKomSigStartPos" SG_ 542 Character4 7;
BA_ "FlexKomSigLaenge" SG_ 542 Character4 64;
BA_ "FlexKomSigName" SG_ 542 Character4 "ORC_YRS_INFO";
BA_ "FlexKomComment" SG_ 542 Character4 "Traceability - part number information packet";
BA_ "FlexKomIsMotorola" SG_ 542 Character4 1;
BA_ "GenSigSNA" SG_ 542 Character4 "0h";
BA_ "GenSigSendType" SG_ 542 Character3 9;
BA_ "GenSigCycleTime" SG_ 542 Character3 100;
BA_ "FlexKomSigStartValue" SG_ 542 Character3 "0000000000000000h";
BA_ "FlexKomSID" SG_ 542 Character3 1588;
BA_ "FlexKomSigStartPos" SG_ 542 Character3 7;
BA_ "FlexKomSigLaenge" SG_ 542 Character3 64;
BA_ "FlexKomSigName" SG_ 542 Character3 "ORC_YRS_INFO";
BA_ "FlexKomComment" SG_ 542 Character3 "Traceability - part number information packet";
BA_ "FlexKomIsMotorola" SG_ 542 Character3 1;
BA_ "GenSigSNA" SG_ 542 Character3 "0h";
BA_ "GenSigSendType" SG_ 542 Character2 9;
BA_ "GenSigCycleTime" SG_ 542 Character2 100;
BA_ "FlexKomSigStartValue" SG_ 542 Character2 "0000000000000000h";
BA_ "FlexKomSID" SG_ 542 Character2 1588;
BA_ "FlexKomSigStartPos" SG_ 542 Character2 7;
BA_ "FlexKomSigLaenge" SG_ 542 Character2 64;
BA_ "FlexKomSigName" SG_ 542 Character2 "ORC_YRS_INFO";
BA_ "FlexKomComment" SG_ 542 Character2 "Traceability - part number information packet";
BA_ "FlexKomIsMotorola" SG_ 542 Character2 1;
BA_ "GenSigSNA" SG_ 542 Character2 "0h";
BA_ "GenSigSendType" SG_ 542 Character1 9;
BA_ "GenSigCycleTime" SG_ 542 Character1 100;
BA_ "FlexKomSigStartValue" SG_ 542 Character1 "0000000000000000h";
BA_ "FlexKomSID" SG_ 542 Character1 1588;
BA_ "FlexKomSigStartPos" SG_ 542 Character1 7;
BA_ "FlexKomSigLaenge" SG_ 542 Character1 64;
BA_ "FlexKomSigName" SG_ 542 Character1 "ORC_YRS_INFO";
BA_ "FlexKomComment" SG_ 542 Character1 "Traceability - part number information packet";
BA_ "FlexKomIsMotorola" SG_ 542 Character1 1;
BA_ "GenSigSNA" SG_ 542 Character1 "0h";
BA_ "GenSigSendType" SG_ 542 Character0 9;
BA_ "GenSigCycleTime" SG_ 542 Character0 100;
BA_ "FlexKomSigStartValue" SG_ 542 Character0 "0000000000000000h";
BA_ "FlexKomSID" SG_ 542 Character0 1588;
BA_ "FlexKomSigStartPos" SG_ 542 Character0 7;
BA_ "FlexKomSigLaenge" SG_ 542 Character0 64;
BA_ "FlexKomSigName" SG_ 542 Character0 "ORC_YRS_INFO";
BA_ "FlexKomComment" SG_ 542 Character0 "Traceability - part number information packet";
BA_ "FlexKomIsMotorola" SG_ 542 Character0 1;
BA_ "GenSigSNA" SG_ 542 Character0 "0h";
BA_ "GenSigCycleTime" SG_ 544 StrClmTrq 10;
BA_ "FlexKomSigStartValue" SG_ 544 StrClmTrq "07FF0FFF1C0000FFh";
BA_ "GenSigStartValue" SG_ 544 StrClmTrq 2047;
BA_ "GenSigTimeout_PTS" SG_ 544 StrClmTrq 105;
BA_ "GenSigTimeout_HaLF" SG_ 544 StrClmTrq 105;
BA_ "FlexKomSID" SG_ 544 StrClmTrq 1415;
BA_ "FlexKomSigStartPos" SG_ 544 StrClmTrq 7;
BA_ "FlexKomSigLaenge" SG_ 544 StrClmTrq 64;
BA_ "FlexKomSigName" SG_ 544 StrClmTrq "EPS_1_PKT";
BA_ "FlexKomComment" SG_ 544 StrClmTrq "EPS_1 packet";
BA_ "FlexKomIsMotorola" SG_ 544 StrClmTrq 1;
BA_ "GenSigSNA" SG_ 544 StrClmTrq "7FFh";
BA_ "GenSigCycleTime" SG_ 544 TOI_Act_Sts 10;
BA_ "FlexKomSigStartValue" SG_ 544 TOI_Act_Sts "07FF0FFF1C0000FFh";
BA_ "GenSigTimeout_PTS" SG_ 544 TOI_Act_Sts 105;
BA_ "GenSigTimeout_HaLF" SG_ 544 TOI_Act_Sts 105;
BA_ "FlexKomSID" SG_ 544 TOI_Act_Sts 1415;
BA_ "FlexKomSigStartPos" SG_ 544 TOI_Act_Sts 7;
BA_ "FlexKomSigLaenge" SG_ 544 TOI_Act_Sts 64;
BA_ "FlexKomSigName" SG_ 544 TOI_Act_Sts "EPS_1_PKT";
BA_ "FlexKomComment" SG_ 544 TOI_Act_Sts "EPS_1 packet";
BA_ "FlexKomIsMotorola" SG_ 544 TOI_Act_Sts 1;
BA_ "GenSigSNA" SG_ 544 TOI_Act_Sts "Fh";
BA_ "GenSigCycleTime" SG_ 544 StrClmTrqVD 10;
BA_ "FlexKomSigStartValue" SG_ 544 StrClmTrqVD "07FF0FFF1C0000FFh";
BA_ "GenSigTimeout_PTS" SG_ 544 StrClmTrqVD 105;
BA_ "GenSigTimeout_HaLF" SG_ 544 StrClmTrqVD 105;
BA_ "FlexKomSID" SG_ 544 StrClmTrqVD 1415;
BA_ "FlexKomSigStartPos" SG_ 544 StrClmTrqVD 7;
BA_ "FlexKomSigLaenge" SG_ 544 StrClmTrqVD 64;
BA_ "FlexKomSigName" SG_ 544 StrClmTrqVD "EPS_1_PKT";
BA_ "FlexKomComment" SG_ 544 StrClmTrqVD "EPS_1 packet";
BA_ "FlexKomIsMotorola" SG_ 544 StrClmTrqVD 1;
BA_ "GenSigSNA" SG_ 544 StrClmTrqVD "0h";
BA_ "GenSigCycleTime" SG_ 544 AssistanceTorque 10;
BA_ "FlexKomSigStartValue" SG_ 544 AssistanceTorque "07FF0FFF1C0000FFh";
BA_ "GenSigStartValue" SG_ 544 AssistanceTorque 4095;
BA_ "GenSigTimeout_PTS" SG_ 544 AssistanceTorque 105;
BA_ "GenSigTimeout_HaLF" SG_ 544 AssistanceTorque 105;
BA_ "FlexKomSID" SG_ 544 AssistanceTorque 1415;
BA_ "FlexKomSigStartPos" SG_ 544 AssistanceTorque 7;
BA_ "FlexKomSigLaenge" SG_ 544 AssistanceTorque 64;
BA_ "FlexKomSigName" SG_ 544 AssistanceTorque "EPS_1_PKT";
BA_ "FlexKomComment" SG_ 544 AssistanceTorque "EPS_1 packet";
BA_ "FlexKomIsMotorola" SG_ 544 AssistanceTorque 1;
BA_ "GenSigSNA" SG_ 544 AssistanceTorque "FFFh";
BA_ "GenSigCycleTime" SG_ 544 PTSDriveStyleSts 10;
BA_ "FlexKomSigStartValue" SG_ 544 PTSDriveStyleSts "07FF0FFF1C0000FFh";
BA_ "GenSigTimeout_PTS" SG_ 544 PTSDriveStyleSts 105;
BA_ "GenSigTimeout_HaLF" SG_ 544 PTSDriveStyleSts 105;
BA_ "FlexKomSID" SG_ 544 PTSDriveStyleSts 1415;
BA_ "FlexKomSigStartPos" SG_ 544 PTSDriveStyleSts 7;
BA_ "FlexKomSigLaenge" SG_ 544 PTSDriveStyleSts 64;
BA_ "FlexKomSigName" SG_ 544 PTSDriveStyleSts "EPS_1_PKT";
BA_ "FlexKomComment" SG_ 544 PTSDriveStyleSts "EPS_1 packet";
BA_ "FlexKomIsMotorola" SG_ 544 PTSDriveStyleSts 1;
BA_ "GenSigSNA" SG_ 544 PTSDriveStyleSts "0h";
BA_ "GenSigCycleTime" SG_ 544 DSTTorqueOverlayFault 10;
BA_ "FlexKomSigStartValue" SG_ 544 DSTTorqueOverlayFault "07FF0FFF1C0000FFh";
BA_ "GenSigTimeout_PTS" SG_ 544 DSTTorqueOverlayFault 105;
BA_ "GenSigTimeout_HaLF" SG_ 544 DSTTorqueOverlayFault 105;
BA_ "FlexKomSID" SG_ 544 DSTTorqueOverlayFault 1415;
BA_ "FlexKomSigStartPos" SG_ 544 DSTTorqueOverlayFault 7;
BA_ "FlexKomSigLaenge" SG_ 544 DSTTorqueOverlayFault 64;
BA_ "FlexKomSigName" SG_ 544 DSTTorqueOverlayFault "EPS_1_PKT";
BA_ "FlexKomComment" SG_ 544 DSTTorqueOverlayFault "EPS_1 packet";
BA_ "FlexKomIsMotorola" SG_ 544 DSTTorqueOverlayFault 1;
BA_ "GenSigSNA" SG_ 544 DSTTorqueOverlayFault "0h";
BA_ "GenSigCycleTime" SG_ 544 HALFTorqueOverlayFault 10;
BA_ "FlexKomSigStartValue" SG_ 544 HALFTorqueOverlayFault "07FF0FFF1C0000FFh";
BA_ "GenSigTimeout_PTS" SG_ 544 HALFTorqueOverlayFault 105;
BA_ "GenSigTimeout_HaLF" SG_ 544 HALFTorqueOverlayFault 105;
BA_ "FlexKomSID" SG_ 544 HALFTorqueOverlayFault 1415;
BA_ "FlexKomSigStartPos" SG_ 544 HALFTorqueOverlayFault 7;
BA_ "FlexKomSigLaenge" SG_ 544 HALFTorqueOverlayFault 64;
BA_ "FlexKomSigName" SG_ 544 HALFTorqueOverlayFault "EPS_1_PKT";
BA_ "FlexKomComment" SG_ 544 HALFTorqueOverlayFault "EPS_1 packet";
BA_ "FlexKomIsMotorola" SG_ 544 HALFTorqueOverlayFault 1;
BA_ "GenSigSNA" SG_ 544 HALFTorqueOverlayFault "0h";
BA_ "GenSigCycleTime" SG_ 544 HALFTorqueOverlayIntActivated 10;
BA_ "FlexKomSigStartValue" SG_ 544 HALFTorqueOverlayIntActivated "07FF0FFF1C0000FFh";
BA_ "GenSigTimeout_PTS" SG_ 544 HALFTorqueOverlayIntActivated 105;
BA_ "GenSigTimeout_HaLF" SG_ 544 HALFTorqueOverlayIntActivated 105;
BA_ "FlexKomSID" SG_ 544 HALFTorqueOverlayIntActivated 1415;
BA_ "FlexKomSigStartPos" SG_ 544 HALFTorqueOverlayIntActivated 7;
BA_ "FlexKomSigLaenge" SG_ 544 HALFTorqueOverlayIntActivated 64;
BA_ "FlexKomSigName" SG_ 544 HALFTorqueOverlayIntActivated "EPS_1_PKT";
BA_ "FlexKomComment" SG_ 544 HALFTorqueOverlayIntActivated "EPS_1 packet";
BA_ "FlexKomIsMotorola" SG_ 544 HALFTorqueOverlayIntActivated 1;
BA_ "GenSigSNA" SG_ 544 HALFTorqueOverlayIntActivated "0h";
BA_ "GenSigCycleTime" SG_ 544 EPSMotorTorque 10;
BA_ "FlexKomSigStartValue" SG_ 544 EPSMotorTorque "07FF0FFF1C0000FFh";
BA_ "GenSigStartValue" SG_ 544 EPSMotorTorque 1024;
BA_ "GenSigTimeout_HaLF" SG_ 544 EPSMotorTorque 105;
BA_ "FlexKomSID" SG_ 544 EPSMotorTorque 1415;
BA_ "FlexKomSigStartPos" SG_ 544 EPSMotorTorque 7;
BA_ "FlexKomSigLaenge" SG_ 544 EPSMotorTorque 64;
BA_ "FlexKomSigName" SG_ 544 EPSMotorTorque "EPS_1_PKT";
BA_ "FlexKomComment" SG_ 544 EPSMotorTorque "EPS_1 packet";
BA_ "FlexKomIsMotorola" SG_ 544 EPSMotorTorque 1;
BA_ "GenSigSNA" SG_ 544 EPSMotorTorque "400h";
BA_ "GenSigCycleTime" SG_ 544 DSTTorqueOverlayIntActivated 10;
BA_ "FlexKomSigStartValue" SG_ 544 DSTTorqueOverlayIntActivated "07FF0FFF1C0000FFh";
BA_ "GenSigTimeout_HaLF" SG_ 544 DSTTorqueOverlayIntActivated 105;
BA_ "FlexKomSID" SG_ 544 DSTTorqueOverlayIntActivated 1415;
BA_ "FlexKomSigStartPos" SG_ 544 DSTTorqueOverlayIntActivated 7;
BA_ "FlexKomSigLaenge" SG_ 544 DSTTorqueOverlayIntActivated 64;
BA_ "FlexKomSigName" SG_ 544 DSTTorqueOverlayIntActivated "EPS_1_PKT";
BA_ "FlexKomComment" SG_ 544 DSTTorqueOverlayIntActivated "EPS_1 packet";
BA_ "FlexKomIsMotorola" SG_ 544 DSTTorqueOverlayIntActivated 1;
BA_ "GenSigSNA" SG_ 544 DSTTorqueOverlayIntActivated "0h";
BA_ "GenSigCycleTime" SG_ 544 EPSTemporaryDeactivationLDW 10;
BA_ "FlexKomSigStartValue" SG_ 544 EPSTemporaryDeactivationLDW "07FF0FFF1C0000FFh";
BA_ "FlexKomSID" SG_ 544 EPSTemporaryDeactivationLDW 1415;
BA_ "FlexKomSigStartPos" SG_ 544 EPSTemporaryDeactivationLDW 7;
BA_ "FlexKomSigLaenge" SG_ 544 EPSTemporaryDeactivationLDW 64;
BA_ "FlexKomSigName" SG_ 544 EPSTemporaryDeactivationLDW "EPS_1_PKT";
BA_ "FlexKomComment" SG_ 544 EPSTemporaryDeactivationLDW "EPS_1 packet";
BA_ "FlexKomIsMotorola" SG_ 544 EPSTemporaryDeactivationLDW 1;
BA_ "GenSigSNA" SG_ 544 EPSTemporaryDeactivationLDW "0h";
BA_ "GenSigCycleTime" SG_ 544 EPSMotorTorqueValidData 10;
BA_ "FlexKomSigStartValue" SG_ 544 EPSMotorTorqueValidData "07FF0FFF1C0000FFh";
BA_ "GenSigTimeout_HaLF" SG_ 544 EPSMotorTorqueValidData 105;
BA_ "FlexKomSID" SG_ 544 EPSMotorTorqueValidData 1415;
BA_ "FlexKomSigStartPos" SG_ 544 EPSMotorTorqueValidData 7;
BA_ "FlexKomSigLaenge" SG_ 544 EPSMotorTorqueValidData 64;
BA_ "FlexKomSigName" SG_ 544 EPSMotorTorqueValidData "EPS_1_PKT";
BA_ "FlexKomComment" SG_ 544 EPSMotorTorqueValidData "EPS_1 packet";
BA_ "FlexKomIsMotorola" SG_ 544 EPSMotorTorqueValidData 1;
BA_ "GenSigSNA" SG_ 544 EPSMotorTorqueValidData "0h";
BA_ "GenSigCycleTime" SG_ 544 EPSHandsOnRecognition 10;
BA_ "FlexKomSigStartValue" SG_ 544 EPSHandsOnRecognition "07FF0FFF1C0000FFh";
BA_ "GenSigTimeout_PTS" SG_ 544 EPSHandsOnRecognition 105;
BA_ "GenSigTimeout_HaLF" SG_ 544 EPSHandsOnRecognition 105;
BA_ "FlexKomSID" SG_ 544 EPSHandsOnRecognition 1415;
BA_ "FlexKomSigStartPos" SG_ 544 EPSHandsOnRecognition 7;
BA_ "FlexKomSigLaenge" SG_ 544 EPSHandsOnRecognition 64;
BA_ "FlexKomSigName" SG_ 544 EPSHandsOnRecognition "EPS_1_PKT";
BA_ "FlexKomComment" SG_ 544 EPSHandsOnRecognition "EPS_1 packet";
BA_ "FlexKomIsMotorola" SG_ 544 EPSHandsOnRecognition 1;
BA_ "GenSigSNA" SG_ 544 EPSHandsOnRecognition "0h";
BA_ "GenSigCycleTime" SG_ 544 EPSTemporaryDeactivationPPPA 10;
BA_ "FlexKomSigStartValue" SG_ 544 EPSTemporaryDeactivationPPPA "07FF0FFF1C0000FFh";
BA_ "GenSigTimeout_PTS" SG_ 544 EPSTemporaryDeactivationPPPA 105;
BA_ "GenSigTimeout_HaLF" SG_ 544 EPSTemporaryDeactivationPPPA 105;
BA_ "FlexKomSID" SG_ 544 EPSTemporaryDeactivationPPPA 1415;
BA_ "FlexKomSigStartPos" SG_ 544 EPSTemporaryDeactivationPPPA 7;
BA_ "FlexKomSigLaenge" SG_ 544 EPSTemporaryDeactivationPPPA 64;
BA_ "FlexKomSigName" SG_ 544 EPSTemporaryDeactivationPPPA "EPS_1_PKT";
BA_ "FlexKomComment" SG_ 544 EPSTemporaryDeactivationPPPA "EPS_1 packet";
BA_ "FlexKomIsMotorola" SG_ 544 EPSTemporaryDeactivationPPPA 1;
BA_ "GenSigSNA" SG_ 544 EPSTemporaryDeactivationPPPA "0h";
BA_ "GenSigCycleTime" SG_ 544 PTSTorqueOverlayFault 10;
BA_ "FlexKomSigStartValue" SG_ 544 PTSTorqueOverlayFault "07FF0FFF1C0000FFh";
BA_ "GenSigTimeout_PTS" SG_ 544 PTSTorqueOverlayFault 105;
BA_ "GenSigTimeout_HaLF" SG_ 544 PTSTorqueOverlayFault 105;
BA_ "FlexKomSID" SG_ 544 PTSTorqueOverlayFault 1415;
BA_ "FlexKomSigStartPos" SG_ 544 PTSTorqueOverlayFault 7;
BA_ "FlexKomSigLaenge" SG_ 544 PTSTorqueOverlayFault 64;
BA_ "FlexKomSigName" SG_ 544 PTSTorqueOverlayFault "EPS_1_PKT";
BA_ "FlexKomComment" SG_ 544 PTSTorqueOverlayFault "EPS_1 packet";
BA_ "FlexKomIsMotorola" SG_ 544 PTSTorqueOverlayFault 1;
BA_ "GenSigSNA" SG_ 544 PTSTorqueOverlayFault "0h";
BA_ "GenSigCycleTime" SG_ 544 PTSTorqueOverlayIntActivated 10;
BA_ "FlexKomSigStartValue" SG_ 544 PTSTorqueOverlayIntActivated "07FF0FFF1C0000FFh";
BA_ "GenSigTimeout_PTS" SG_ 544 PTSTorqueOverlayIntActivated 105;
BA_ "GenSigTimeout_HaLF" SG_ 544 PTSTorqueOverlayIntActivated 105;
BA_ "FlexKomSID" SG_ 544 PTSTorqueOverlayIntActivated 1415;
BA_ "FlexKomSigStartPos" SG_ 544 PTSTorqueOverlayIntActivated 7;
BA_ "FlexKomSigLaenge" SG_ 544 PTSTorqueOverlayIntActivated 64;
BA_ "FlexKomSigName" SG_ 544 PTSTorqueOverlayIntActivated "EPS_1_PKT";
BA_ "FlexKomComment" SG_ 544 PTSTorqueOverlayIntActivated "EPS_1 packet";
BA_ "FlexKomIsMotorola" SG_ 544 PTSTorqueOverlayIntActivated 1;
BA_ "GenSigSNA" SG_ 544 PTSTorqueOverlayIntActivated "0h";
BA_ "GenSigCycleTime" SG_ 544 MC_EPS_1 10;
BA_ "FlexKomSigStartValue" SG_ 544 MC_EPS_1 "07FF0FFF1C0000FFh";
BA_ "GenSigTimeout_PTS" SG_ 544 MC_EPS_1 105;
BA_ "GenSigTimeout_HaLF" SG_ 544 MC_EPS_1 105;
BA_ "FlexKomSID" SG_ 544 MC_EPS_1 1415;
BA_ "FlexKomSigStartPos" SG_ 544 MC_EPS_1 7;
BA_ "FlexKomSigLaenge" SG_ 544 MC_EPS_1 64;
BA_ "FlexKomSigName" SG_ 544 MC_EPS_1 "EPS_1_PKT";
BA_ "FlexKomComment" SG_ 544 MC_EPS_1 "EPS_1 packet";
BA_ "FlexKomIsMotorola" SG_ 544 MC_EPS_1 1;
BA_ "GenSigSNA" SG_ 544 MC_EPS_1 "0h";
BA_ "GenSigCycleTime" SG_ 544 CRC_EPS_1 10;
BA_ "FlexKomSigStartValue" SG_ 544 CRC_EPS_1 "07FF0FFF1C0000FFh";
BA_ "GenSigStartValue" SG_ 544 CRC_EPS_1 255;
BA_ "GenSigTimeout_PTS" SG_ 544 CRC_EPS_1 105;
BA_ "GenSigTimeout_HaLF" SG_ 544 CRC_EPS_1 105;
BA_ "FlexKomSID" SG_ 544 CRC_EPS_1 1415;
BA_ "FlexKomSigStartPos" SG_ 544 CRC_EPS_1 7;
BA_ "FlexKomSigLaenge" SG_ 544 CRC_EPS_1 64;
BA_ "FlexKomSigName" SG_ 544 CRC_EPS_1 "EPS_1_PKT";
BA_ "FlexKomComment" SG_ 544 CRC_EPS_1 "EPS_1 packet";
BA_ "FlexKomIsMotorola" SG_ 544 CRC_EPS_1 1;
BA_ "GenSigSNA" SG_ 544 CRC_EPS_1 "FFh";
BA_ "GenSigSendType" SG_ 557 StW_TempSts 5;
BA_ "GenSigCycleTime" SG_ 557 StW_TempSts 1000;
BA_ "FlexKomSigStartValue" SG_ 557 StW_TempSts "FF00000000000000h";
BA_ "GenSigStartValue" SG_ 557 StW_TempSts 255;
BA_ "FlexKomSID" SG_ 557 StW_TempSts 1811;
BA_ "FlexKomSigStartPos" SG_ 557 StW_TempSts 7;
BA_ "FlexKomSigLaenge" SG_ 557 StW_TempSts 64;
BA_ "FlexKomSigName" SG_ 557 StW_TempSts "SWS8_Pkt";
BA_ "FlexKomComment" SG_ 557 StW_TempSts "Steering wheel switch packet";
BA_ "FlexKomIsMotorola" SG_ 557 StW_TempSts 1;
BA_ "GenSigSNA" SG_ 557 StW_TempSts "FFh";
BA_ "GenSigSendType" SG_ 557 HrnSwPsd 5;
BA_ "GenSigCycleTime" SG_ 557 HrnSwPsd 1000;
BA_ "FlexKomSigStartValue" SG_ 557 HrnSwPsd "FF00000000000000h";
BA_ "GenSigTimeout_IC" SG_ 557 HrnSwPsd 10500;
BA_ "FlexKomSID" SG_ 557 HrnSwPsd 1811;
BA_ "FlexKomSigStartPos" SG_ 557 HrnSwPsd 7;
BA_ "FlexKomSigLaenge" SG_ 557 HrnSwPsd 64;
BA_ "FlexKomSigName" SG_ 557 HrnSwPsd "SWS8_Pkt";
BA_ "FlexKomComment" SG_ 557 HrnSwPsd "Steering wheel switch packet";
BA_ "FlexKomIsMotorola" SG_ 557 HrnSwPsd 1;
BA_ "GenSigSNA" SG_ 557 HrnSwPsd "0h";
BA_ "GenSigSendType" SG_ 557 StW_TempSensSts 5;
BA_ "GenSigCycleTime" SG_ 557 StW_TempSensSts 1000;
BA_ "FlexKomSigStartValue" SG_ 557 StW_TempSensSts "FF00000000000000h";
BA_ "FlexKomSID" SG_ 557 StW_TempSensSts 1811;
BA_ "FlexKomSigStartPos" SG_ 557 StW_TempSensSts 7;
BA_ "FlexKomSigLaenge" SG_ 557 StW_TempSensSts 64;
BA_ "FlexKomSigName" SG_ 557 StW_TempSensSts "SWS8_Pkt";
BA_ "FlexKomComment" SG_ 557 StW_TempSensSts "Steering wheel switch packet";
BA_ "FlexKomIsMotorola" SG_ 557 StW_TempSensSts 1;
BA_ "GenSigSNA" SG_ 557 StW_TempSensSts "3h";
BA_ "GenSigSendType" SG_ 557 Command_01 5;
BA_ "GenSigCycleTime" SG_ 557 Command_01 1000;
BA_ "FlexKomSigStartValue" SG_ 557 Command_01 "FF00000000000000h";
BA_ "GenSigTimeout_IC" SG_ 557 Command_01 10500;
BA_ "FlexKomSID" SG_ 557 Command_01 1811;
BA_ "FlexKomSigStartPos" SG_ 557 Command_01 7;
BA_ "FlexKomSigLaenge" SG_ 557 Command_01 64;
BA_ "FlexKomSigName" SG_ 557 Command_01 "SWS8_Pkt";
BA_ "FlexKomComment" SG_ 557 Command_01 "Steering wheel switch packet";
BA_ "FlexKomIsMotorola" SG_ 557 Command_01 1;
BA_ "GenSigSNA" SG_ 557 Command_01 "3h";
BA_ "GenSigSendType" SG_ 557 Command_02 5;
BA_ "GenSigCycleTime" SG_ 557 Command_02 1000;
BA_ "FlexKomSigStartValue" SG_ 557 Command_02 "FF00000000000000h";
BA_ "GenSigTimeout_IC" SG_ 557 Command_02 10500;
BA_ "FlexKomSID" SG_ 557 Command_02 1811;
BA_ "FlexKomSigStartPos" SG_ 557 Command_02 7;
BA_ "FlexKomSigLaenge" SG_ 557 Command_02 64;
BA_ "FlexKomSigName" SG_ 557 Command_02 "SWS8_Pkt";
BA_ "FlexKomComment" SG_ 557 Command_02 "Steering wheel switch packet";
BA_ "FlexKomIsMotorola" SG_ 557 Command_02 1;
BA_ "GenSigSNA" SG_ 557 Command_02 "3h";
BA_ "GenSigSendType" SG_ 557 Command_03 5;
BA_ "GenSigCycleTime" SG_ 557 Command_03 1000;
BA_ "FlexKomSigStartValue" SG_ 557 Command_03 "FF00000000000000h";
BA_ "GenSigTimeout_IC" SG_ 557 Command_03 10500;
BA_ "FlexKomSID" SG_ 557 Command_03 1811;
BA_ "FlexKomSigStartPos" SG_ 557 Command_03 7;
BA_ "FlexKomSigLaenge" SG_ 557 Command_03 64;
BA_ "FlexKomSigName" SG_ 557 Command_03 "SWS8_Pkt";
BA_ "FlexKomComment" SG_ 557 Command_03 "Steering wheel switch packet";
BA_ "FlexKomIsMotorola" SG_ 557 Command_03 1;
BA_ "GenSigSNA" SG_ 557 Command_03 "3h";
BA_ "GenSigSendType" SG_ 557 Command_04 5;
BA_ "GenSigCycleTime" SG_ 557 Command_04 1000;
BA_ "FlexKomSigStartValue" SG_ 557 Command_04 "FF00000000000000h";
BA_ "GenSigTimeout_IC" SG_ 557 Command_04 10500;
BA_ "FlexKomSID" SG_ 557 Command_04 1811;
BA_ "FlexKomSigStartPos" SG_ 557 Command_04 7;
BA_ "FlexKomSigLaenge" SG_ 557 Command_04 64;
BA_ "FlexKomSigName" SG_ 557 Command_04 "SWS8_Pkt";
BA_ "FlexKomComment" SG_ 557 Command_04 "Steering wheel switch packet";
BA_ "FlexKomIsMotorola" SG_ 557 Command_04 1;
BA_ "GenSigSNA" SG_ 557 Command_04 "3h";
BA_ "GenSigSendType" SG_ 557 Command_05 5;
BA_ "GenSigCycleTime" SG_ 557 Command_05 1000;
BA_ "FlexKomSigStartValue" SG_ 557 Command_05 "FF00000000000000h";
BA_ "GenSigTimeout_IC" SG_ 557 Command_05 10500;
BA_ "FlexKomSID" SG_ 557 Command_05 1811;
BA_ "FlexKomSigStartPos" SG_ 557 Command_05 7;
BA_ "FlexKomSigLaenge" SG_ 557 Command_05 64;
BA_ "FlexKomSigName" SG_ 557 Command_05 "SWS8_Pkt";
BA_ "FlexKomComment" SG_ 557 Command_05 "Steering wheel switch packet";
BA_ "FlexKomIsMotorola" SG_ 557 Command_05 1;
BA_ "GenSigSNA" SG_ 557 Command_05 "3h";
BA_ "GenSigSendType" SG_ 557 Command_06 5;
BA_ "GenSigCycleTime" SG_ 557 Command_06 1000;
BA_ "FlexKomSigStartValue" SG_ 557 Command_06 "FF00000000000000h";
BA_ "GenSigTimeout_IC" SG_ 557 Command_06 10500;
BA_ "FlexKomSID" SG_ 557 Command_06 1811;
BA_ "FlexKomSigStartPos" SG_ 557 Command_06 7;
BA_ "FlexKomSigLaenge" SG_ 557 Command_06 64;
BA_ "FlexKomSigName" SG_ 557 Command_06 "SWS8_Pkt";
BA_ "FlexKomComment" SG_ 557 Command_06 "Steering wheel switch packet";
BA_ "FlexKomIsMotorola" SG_ 557 Command_06 1;
BA_ "GenSigSNA" SG_ 557 Command_06 "3h";
BA_ "GenSigSendType" SG_ 557 Command_07 5;
BA_ "GenSigCycleTime" SG_ 557 Command_07 1000;
BA_ "FlexKomSigStartValue" SG_ 557 Command_07 "FF00000000000000h";
BA_ "GenSigTimeout_IC" SG_ 557 Command_07 10500;
BA_ "FlexKomSID" SG_ 557 Command_07 1811;
BA_ "FlexKomSigStartPos" SG_ 557 Command_07 7;
BA_ "FlexKomSigLaenge" SG_ 557 Command_07 64;
BA_ "FlexKomSigName" SG_ 557 Command_07 "SWS8_Pkt";
BA_ "FlexKomComment" SG_ 557 Command_07 "Steering wheel switch packet";
BA_ "FlexKomIsMotorola" SG_ 557 Command_07 1;
BA_ "GenSigSNA" SG_ 557 Command_07 "3h";
BA_ "GenSigSendType" SG_ 557 Command_08 5;
BA_ "GenSigCycleTime" SG_ 557 Command_08 1000;
BA_ "FlexKomSigStartValue" SG_ 557 Command_08 "FF00000000000000h";
BA_ "GenSigTimeout_IC" SG_ 557 Command_08 10500;
BA_ "FlexKomSID" SG_ 557 Command_08 1811;
BA_ "FlexKomSigStartPos" SG_ 557 Command_08 7;
BA_ "FlexKomSigLaenge" SG_ 557 Command_08 64;
BA_ "FlexKomSigName" SG_ 557 Command_08 "SWS8_Pkt";
BA_ "FlexKomComment" SG_ 557 Command_08 "Steering wheel switch packet";
BA_ "FlexKomIsMotorola" SG_ 557 Command_08 1;
BA_ "GenSigSNA" SG_ 557 Command_08 "3h";
BA_ "GenSigSendType" SG_ 557 Command_09 5;
BA_ "GenSigCycleTime" SG_ 557 Command_09 1000;
BA_ "FlexKomSigStartValue" SG_ 557 Command_09 "FF00000000000000h";
BA_ "GenSigTimeout_IC" SG_ 557 Command_09 10500;
BA_ "FlexKomSID" SG_ 557 Command_09 1811;
BA_ "FlexKomSigStartPos" SG_ 557 Command_09 7;
BA_ "FlexKomSigLaenge" SG_ 557 Command_09 64;
BA_ "FlexKomSigName" SG_ 557 Command_09 "SWS8_Pkt";
BA_ "FlexKomComment" SG_ 557 Command_09 "Steering wheel switch packet";
BA_ "FlexKomIsMotorola" SG_ 557 Command_09 1;
BA_ "GenSigSNA" SG_ 557 Command_09 "3h";
BA_ "GenSigSendType" SG_ 557 Command_10 5;
BA_ "GenSigCycleTime" SG_ 557 Command_10 1000;
BA_ "FlexKomSigStartValue" SG_ 557 Command_10 "FF00000000000000h";
BA_ "GenSigTimeout_IC" SG_ 557 Command_10 10500;
BA_ "FlexKomSID" SG_ 557 Command_10 1811;
BA_ "FlexKomSigStartPos" SG_ 557 Command_10 7;
BA_ "FlexKomSigLaenge" SG_ 557 Command_10 64;
BA_ "FlexKomSigName" SG_ 557 Command_10 "SWS8_Pkt";
BA_ "FlexKomComment" SG_ 557 Command_10 "Steering wheel switch packet";
BA_ "FlexKomIsMotorola" SG_ 557 Command_10 1;
BA_ "GenSigSNA" SG_ 557 Command_10 "3h";
BA_ "GenSigSendType" SG_ 557 Command_11 5;
BA_ "GenSigCycleTime" SG_ 557 Command_11 1000;
BA_ "FlexKomSigStartValue" SG_ 557 Command_11 "FF00000000000000h";
BA_ "GenSigTimeout_IC" SG_ 557 Command_11 10500;
BA_ "FlexKomSID" SG_ 557 Command_11 1811;
BA_ "FlexKomSigStartPos" SG_ 557 Command_11 7;
BA_ "FlexKomSigLaenge" SG_ 557 Command_11 64;
BA_ "FlexKomSigName" SG_ 557 Command_11 "SWS8_Pkt";
BA_ "FlexKomComment" SG_ 557 Command_11 "Steering wheel switch packet";
BA_ "FlexKomIsMotorola" SG_ 557 Command_11 1;
BA_ "GenSigSNA" SG_ 557 Command_11 "3h";
BA_ "GenSigSendType" SG_ 557 Command_12 5;
BA_ "GenSigCycleTime" SG_ 557 Command_12 1000;
BA_ "FlexKomSigStartValue" SG_ 557 Command_12 "FF00000000000000h";
BA_ "GenSigTimeout_IC" SG_ 557 Command_12 10500;
BA_ "FlexKomSID" SG_ 557 Command_12 1811;
BA_ "FlexKomSigStartPos" SG_ 557 Command_12 7;
BA_ "FlexKomSigLaenge" SG_ 557 Command_12 64;
BA_ "FlexKomSigName" SG_ 557 Command_12 "SWS8_Pkt";
BA_ "FlexKomComment" SG_ 557 Command_12 "Steering wheel switch packet";
BA_ "FlexKomIsMotorola" SG_ 557 Command_12 1;
BA_ "GenSigSNA" SG_ 557 Command_12 "3h";
BA_ "GenSigSendType" SG_ 557 Command_13 5;
BA_ "GenSigCycleTime" SG_ 557 Command_13 1000;
BA_ "FlexKomSigStartValue" SG_ 557 Command_13 "FF00000000000000h";
BA_ "GenSigTimeout_IC" SG_ 557 Command_13 10500;
BA_ "FlexKomSID" SG_ 557 Command_13 1811;
BA_ "FlexKomSigStartPos" SG_ 557 Command_13 7;
BA_ "FlexKomSigLaenge" SG_ 557 Command_13 64;
BA_ "FlexKomSigName" SG_ 557 Command_13 "SWS8_Pkt";
BA_ "FlexKomComment" SG_ 557 Command_13 "Steering wheel switch packet";
BA_ "FlexKomIsMotorola" SG_ 557 Command_13 1;
BA_ "GenSigSNA" SG_ 557 Command_13 "3h";
BA_ "GenSigSendType" SG_ 557 Command_14 5;
BA_ "GenSigCycleTime" SG_ 557 Command_14 1000;
BA_ "FlexKomSigStartValue" SG_ 557 Command_14 "FF00000000000000h";
BA_ "GenSigTimeout_IC" SG_ 557 Command_14 10500;
BA_ "FlexKomSID" SG_ 557 Command_14 1811;
BA_ "FlexKomSigStartPos" SG_ 557 Command_14 7;
BA_ "FlexKomSigLaenge" SG_ 557 Command_14 64;
BA_ "FlexKomSigName" SG_ 557 Command_14 "SWS8_Pkt";
BA_ "FlexKomComment" SG_ 557 Command_14 "Steering wheel switch packet";
BA_ "FlexKomIsMotorola" SG_ 557 Command_14 1;
BA_ "GenSigSNA" SG_ 557 Command_14 "3h";
BA_ "GenSigSendType" SG_ 557 Command_15 5;
BA_ "GenSigCycleTime" SG_ 557 Command_15 1000;
BA_ "FlexKomSigStartValue" SG_ 557 Command_15 "FF00000000000000h";
BA_ "GenSigTimeout_IC" SG_ 557 Command_15 10500;
BA_ "FlexKomSID" SG_ 557 Command_15 1811;
BA_ "FlexKomSigStartPos" SG_ 557 Command_15 7;
BA_ "FlexKomSigLaenge" SG_ 557 Command_15 64;
BA_ "FlexKomSigName" SG_ 557 Command_15 "SWS8_Pkt";
BA_ "FlexKomComment" SG_ 557 Command_15 "Steering wheel switch packet";
BA_ "FlexKomIsMotorola" SG_ 557 Command_15 1;
BA_ "GenSigSNA" SG_ 557 Command_15 "3h";
BA_ "GenSigSendType" SG_ 557 Command_16 5;
BA_ "GenSigCycleTime" SG_ 557 Command_16 1000;
BA_ "FlexKomSigStartValue" SG_ 557 Command_16 "FF00000000000000h";
BA_ "GenSigTimeout_IC" SG_ 557 Command_16 10500;
BA_ "FlexKomSID" SG_ 557 Command_16 1811;
BA_ "FlexKomSigStartPos" SG_ 557 Command_16 7;
BA_ "FlexKomSigLaenge" SG_ 557 Command_16 64;
BA_ "FlexKomSigName" SG_ 557 Command_16 "SWS8_Pkt";
BA_ "FlexKomComment" SG_ 557 Command_16 "Steering wheel switch packet";
BA_ "FlexKomIsMotorola" SG_ 557 Command_16 1;
BA_ "GenSigSNA" SG_ 557 Command_16 "3h";
BA_ "GenSigCycleTime" SG_ 559 ActlAccelPdlPosn 20;
BA_ "FlexKomSigStartValue" SG_ 559 ActlAccelPdlPosn "FFFFFFFF00000CFFh";
BA_ "GenSigStartValue" SG_ 559 ActlAccelPdlPosn 255;
BA_ "FlexKomSID" SG_ 559 ActlAccelPdlPosn 1821;
BA_ "FlexKomSigStartPos" SG_ 559 ActlAccelPdlPosn 7;
BA_ "FlexKomSigLaenge" SG_ 559 ActlAccelPdlPosn 64;
BA_ "FlexKomSigName" SG_ 559 ActlAccelPdlPosn "ECM_A5_PKT";
BA_ "FlexKomComment" SG_ 559 ActlAccelPdlPosn "ECM_A5 Packet";
BA_ "FlexKomIsMotorola" SG_ 559 ActlAccelPdlPosn 1;
BA_ "GenSigSNA" SG_ 559 ActlAccelPdlPosn "FFh";
BA_ "GenSigCycleTime" SG_ 559 AirFuelRatio 20;
BA_ "FlexKomSigStartValue" SG_ 559 AirFuelRatio "FFFFFFFF00000CFFh";
BA_ "GenSigStartValue" SG_ 559 AirFuelRatio 255;
BA_ "GenSigTimeout_CBC" SG_ 559 AirFuelRatio 210;
BA_ "GenSigTimeout_IC" SG_ 559 AirFuelRatio 210;
BA_ "FlexKomSID" SG_ 559 AirFuelRatio 1821;
BA_ "FlexKomSigStartPos" SG_ 559 AirFuelRatio 7;
BA_ "FlexKomSigLaenge" SG_ 559 AirFuelRatio 64;
BA_ "FlexKomSigName" SG_ 559 AirFuelRatio "ECM_A5_PKT";
BA_ "FlexKomComment" SG_ 559 AirFuelRatio "ECM_A5 Packet";
BA_ "FlexKomIsMotorola" SG_ 559 AirFuelRatio 1;
BA_ "GenSigSNA" SG_ 559 AirFuelRatio "FFh";
BA_ "GenSigCycleTime" SG_ 559 IntkAirTempIntrClr 20;
BA_ "FlexKomSigStartValue" SG_ 559 IntkAirTempIntrClr "FFFFFFFF00000CFFh";
BA_ "GenSigStartValue" SG_ 559 IntkAirTempIntrClr 255;
BA_ "GenSigTimeout_CBC" SG_ 559 IntkAirTempIntrClr 210;
BA_ "GenSigTimeout_IC" SG_ 559 IntkAirTempIntrClr 210;
BA_ "FlexKomSID" SG_ 559 IntkAirTempIntrClr 1821;
BA_ "FlexKomSigStartPos" SG_ 559 IntkAirTempIntrClr 7;
BA_ "FlexKomSigLaenge" SG_ 559 IntkAirTempIntrClr 64;
BA_ "FlexKomSigName" SG_ 559 IntkAirTempIntrClr "ECM_A5_PKT";
BA_ "FlexKomComment" SG_ 559 IntkAirTempIntrClr "ECM_A5 Packet";
BA_ "FlexKomIsMotorola" SG_ 559 IntkAirTempIntrClr 1;
BA_ "GenSigSNA" SG_ 559 IntkAirTempIntrClr "FFh";
BA_ "GenSigCycleTime" SG_ 559 LTR_CoolantTemp 20;
BA_ "FlexKomSigStartValue" SG_ 559 LTR_CoolantTemp "FFFFFFFF00000CFFh";
BA_ "GenSigStartValue" SG_ 559 LTR_CoolantTemp 255;
BA_ "GenSigTimeout_CBC" SG_ 559 LTR_CoolantTemp 210;
BA_ "GenSigTimeout_IC" SG_ 559 LTR_CoolantTemp 210;
BA_ "FlexKomSID" SG_ 559 LTR_CoolantTemp 1821;
BA_ "FlexKomSigStartPos" SG_ 559 LTR_CoolantTemp 7;
BA_ "FlexKomSigLaenge" SG_ 559 LTR_CoolantTemp 64;
BA_ "FlexKomSigName" SG_ 559 LTR_CoolantTemp "ECM_A5_PKT";
BA_ "FlexKomComment" SG_ 559 LTR_CoolantTemp "ECM_A5 Packet";
BA_ "FlexKomIsMotorola" SG_ 559 LTR_CoolantTemp 1;
BA_ "GenSigSNA" SG_ 559 LTR_CoolantTemp "FFh";
BA_ "GenSigCycleTime" SG_ 559 ECM_DrvDoor 20;
BA_ "FlexKomSigStartValue" SG_ 559 ECM_DrvDoor "FFFFFFFF00000CFFh";
BA_ "GenSigStartValue" SG_ 559 ECM_DrvDoor 3;
BA_ "FlexKomSID" SG_ 559 ECM_DrvDoor 1821;
BA_ "FlexKomSigStartPos" SG_ 559 ECM_DrvDoor 7;
BA_ "FlexKomSigLaenge" SG_ 559 ECM_DrvDoor 64;
BA_ "FlexKomSigName" SG_ 559 ECM_DrvDoor "ECM_A5_PKT";
BA_ "FlexKomComment" SG_ 559 ECM_DrvDoor "ECM_A5 Packet";
BA_ "FlexKomIsMotorola" SG_ 559 ECM_DrvDoor 1;
BA_ "GenSigSNA" SG_ 559 ECM_DrvDoor "3h";
BA_ "GenSigCycleTime" SG_ 559 MC_ECM_A5 20;
BA_ "FlexKomSigStartValue" SG_ 559 MC_ECM_A5 "FFFFFFFF00000CFFh";
BA_ "FlexKomSID" SG_ 559 MC_ECM_A5 1821;
BA_ "FlexKomSigStartPos" SG_ 559 MC_ECM_A5 7;
BA_ "FlexKomSigLaenge" SG_ 559 MC_ECM_A5 64;
BA_ "FlexKomSigName" SG_ 559 MC_ECM_A5 "ECM_A5_PKT";
BA_ "FlexKomComment" SG_ 559 MC_ECM_A5 "ECM_A5 Packet";
BA_ "FlexKomIsMotorola" SG_ 559 MC_ECM_A5 1;
BA_ "GenSigSNA" SG_ 559 MC_ECM_A5 "0h";
BA_ "GenSigCycleTime" SG_ 559 CRC_ECM_A5 20;
BA_ "FlexKomSigStartValue" SG_ 559 CRC_ECM_A5 "FFFFFFFF00000CFFh";
BA_ "GenSigStartValue" SG_ 559 CRC_ECM_A5 255;
BA_ "FlexKomSID" SG_ 559 CRC_ECM_A5 1821;
BA_ "FlexKomSigStartPos" SG_ 559 CRC_ECM_A5 7;
BA_ "FlexKomSigLaenge" SG_ 559 CRC_ECM_A5 64;
BA_ "FlexKomSigName" SG_ 559 CRC_ECM_A5 "ECM_A5_PKT";
BA_ "FlexKomComment" SG_ 559 CRC_ECM_A5 "ECM_A5 Packet";
BA_ "FlexKomIsMotorola" SG_ 559 CRC_ECM_A5 1;
BA_ "GenSigSNA" SG_ 559 CRC_ECM_A5 "FFh";
BA_ "GenSigSendType" SG_ 560 AC_RQ 5;
BA_ "GenSigCycleTime" SG_ 560 AC_RQ 500;
BA_ "FlexKomSigStartValue" SG_ 560 AC_RQ "00h";
BA_ "FlexKomSID" SG_ 560 AC_RQ 27;
BA_ "FlexKomSigLaenge" SG_ 560 AC_RQ 1;
BA_ "FlexKomSigName" SG_ 560 AC_RQ "AC_RQ";
BA_ "FlexKomComment" SG_ 560 AC_RQ "A/C clutch request";
BA_ "FlexKomIsMotorola" SG_ 560 AC_RQ 1;
BA_ "GenSigSNA" SG_ 560 AC_RQ "0h";
BA_ "GenSigSendType" SG_ 560 AC_SEL 5;
BA_ "GenSigCycleTime" SG_ 560 AC_SEL 500;
BA_ "FlexKomSigStartValue" SG_ 560 AC_SEL "00h";
BA_ "FlexKomSID" SG_ 560 AC_SEL 31;
BA_ "FlexKomSigStartPos" SG_ 560 AC_SEL 1;
BA_ "FlexKomSigLaenge" SG_ 560 AC_SEL 1;
BA_ "FlexKomSigName" SG_ 560 AC_SEL "AC_SEL";
BA_ "FlexKomComment" SG_ 560 AC_SEL "Customer has selected A/C";
BA_ "FlexKomIsMotorola" SG_ 560 AC_SEL 1;
BA_ "GenSigSNA" SG_ 560 AC_SEL "0h";
BA_ "GenSigSendType" SG_ 560 DEFROST_SEL 5;
BA_ "GenSigCycleTime" SG_ 560 DEFROST_SEL 500;
BA_ "FlexKomSigStartValue" SG_ 560 DEFROST_SEL "00h";
BA_ "FlexKomSID" SG_ 560 DEFROST_SEL 28;
BA_ "FlexKomSigStartPos" SG_ 560 DEFROST_SEL 2;
BA_ "FlexKomSigLaenge" SG_ 560 DEFROST_SEL 1;
BA_ "FlexKomSigName" SG_ 560 DEFROST_SEL "DEFROST_SEL";
BA_ "FlexKomComment" SG_ 560 DEFROST_SEL "Defrost select switch";
BA_ "FlexKomIsMotorola" SG_ 560 DEFROST_SEL 1;
BA_ "GenSigSNA" SG_ 560 DEFROST_SEL "0h";
BA_ "GenSigSendType" SG_ 560 PTC_Enbl 5;
BA_ "GenSigCycleTime" SG_ 560 PTC_Enbl 500;
BA_ "FlexKomSigStartValue" SG_ 560 PTC_Enbl "01h";
BA_ "GenSigStartValue" SG_ 560 PTC_Enbl 1;
BA_ "FlexKomSID" SG_ 560 PTC_Enbl 33;
BA_ "FlexKomSigStartPos" SG_ 560 PTC_Enbl 3;
BA_ "FlexKomSigLaenge" SG_ 560 PTC_Enbl 1;
BA_ "FlexKomSigName" SG_ 560 PTC_Enbl "PTC_Enbl";
BA_ "FlexKomComment" SG_ 560 PTC_Enbl "PTC heater enable; [1] = enable";
BA_ "FlexKomIsMotorola" SG_ 560 PTC_Enbl 1;
BA_ "GenSigSNA" SG_ 560 PTC_Enbl "1h";
BA_ "GenSigSendType" SG_ 560 AC_PT_Demand 5;
BA_ "GenSigCycleTime" SG_ 560 AC_PT_Demand 500;
BA_ "FlexKomSigStartValue" SG_ 560 AC_PT_Demand "00h";
BA_ "FlexKomSID" SG_ 560 AC_PT_Demand 1945;
BA_ "FlexKomSigStartPos" SG_ 560 AC_PT_Demand 5;
BA_ "FlexKomSigLaenge" SG_ 560 AC_PT_Demand 1;
BA_ "FlexKomSigName" SG_ 560 AC_PT_Demand "AC_PT_Demand";
BA_ "FlexKomComment" SG_ 560 AC_PT_Demand "Maximum A/C demand to powertrain";
BA_ "FlexKomIsMotorola" SG_ 560 AC_PT_Demand 1;
BA_ "GenSigSNA" SG_ 560 AC_PT_Demand "0h";
BA_ "GenSigSendType" SG_ 560 EVAP_FAIL 5;
BA_ "GenSigCycleTime" SG_ 560 EVAP_FAIL 500;
BA_ "FlexKomSigStartValue" SG_ 560 EVAP_FAIL "00h";
BA_ "FlexKomSID" SG_ 560 EVAP_FAIL 1409;
BA_ "FlexKomSigStartPos" SG_ 560 EVAP_FAIL 6;
BA_ "FlexKomSigLaenge" SG_ 560 EVAP_FAIL 1;
BA_ "FlexKomSigName" SG_ 560 EVAP_FAIL "EVAP_FAIL";
BA_ "FlexKomComment" SG_ 560 EVAP_FAIL "Evaporator sensor failure";
BA_ "FlexKomIsMotorola" SG_ 560 EVAP_FAIL 1;
BA_ "GenSigSNA" SG_ 560 EVAP_FAIL "0h";
BA_ "GenSigSendType" SG_ 560 AQS_Active 5;
BA_ "GenSigCycleTime" SG_ 560 AQS_Active 500;
BA_ "FlexKomSigStartValue" SG_ 560 AQS_Active "00h";
BA_ "FlexKomSID" SG_ 560 AQS_Active 1740;
BA_ "FlexKomSigStartPos" SG_ 560 AQS_Active 7;
BA_ "FlexKomSigLaenge" SG_ 560 AQS_Active 1;
BA_ "FlexKomSigName" SG_ 560 AQS_Active "AQS_Active";
BA_ "FlexKomComment" SG_ 560 AQS_Active "Air quality sensor is active; active = [1]";
BA_ "FlexKomIsMotorola" SG_ 560 AQS_Active 1;
BA_ "GenSigSNA" SG_ 560 AQS_Active "0h";
BA_ "GenSigSendType" SG_ 560 EVAP_TEMP 5;
BA_ "GenSigCycleTime" SG_ 560 EVAP_TEMP 500;
BA_ "FlexKomSigStartValue" SG_ 560 EVAP_TEMP "00h";
BA_ "FlexKomSID" SG_ 560 EVAP_TEMP 29;
BA_ "FlexKomSigStartPos" SG_ 560 EVAP_TEMP 15;
BA_ "FlexKomSigLaenge" SG_ 560 EVAP_TEMP 8;
BA_ "FlexKomSigName" SG_ 560 EVAP_TEMP "EVAP_TEMP";
BA_ "FlexKomComment" SG_ 560 EVAP_TEMP "AC evaporator temperature";
BA_ "FlexKomIsMotorola" SG_ 560 EVAP_TEMP 1;
BA_ "GenSigSNA" SG_ 560 EVAP_TEMP "FFh";
BA_ "GenSigSendType" SG_ 560 EvapTempTar 5;
BA_ "GenSigCycleTime" SG_ 560 EvapTempTar 500;
BA_ "FlexKomSigStartValue" SG_ 560 EvapTempTar "00h";
BA_ "FlexKomSID" SG_ 560 EvapTempTar 30;
BA_ "FlexKomSigStartPos" SG_ 560 EvapTempTar 23;
BA_ "FlexKomSigLaenge" SG_ 560 EvapTempTar 8;
BA_ "FlexKomSigName" SG_ 560 EvapTempTar "EvapTempTar";
BA_ "FlexKomComment" SG_ 560 EvapTempTar "Evaporator temperature target";
BA_ "FlexKomIsMotorola" SG_ 560 EvapTempTar 1;
BA_ "GenSigSNA" SG_ 560 EvapTempTar "FFh";
BA_ "GenSigSendType" SG_ 560 SpSt_DsblHVAC 5;
BA_ "GenSigCycleTime" SG_ 560 SpSt_DsblHVAC 500;
BA_ "FlexKomSigStartValue" SG_ 560 SpSt_DsblHVAC "00h";
BA_ "FlexKomSID" SG_ 560 SpSt_DsblHVAC 1555;
BA_ "FlexKomSigStartPos" SG_ 560 SpSt_DsblHVAC 26;
BA_ "FlexKomSigLaenge" SG_ 560 SpSt_DsblHVAC 3;
BA_ "FlexKomSigName" SG_ 560 SpSt_DsblHVAC "SpSt_DsblHVAC";
BA_ "FlexKomComment" SG_ 560 SpSt_DsblHVAC "Stop start disable from HVAC";
BA_ "FlexKomIsMotorola" SG_ 560 SpSt_DsblHVAC 1;
BA_ "GenSigSNA" SG_ 560 SpSt_DsblHVAC "7h";
BA_ "GenSigCycleTime" SG_ 564 IBS_SOF_V 100;
BA_ "FlexKomSigStartValue" SG_ 564 IBS_SOF_V "FF0300FFh";
BA_ "GenSigStartValue" SG_ 564 IBS_SOF_V 255;
BA_ "FlexKomSID" SG_ 564 IBS_SOF_V 1405;
BA_ "FlexKomSigStartPos" SG_ 564 IBS_SOF_V 7;
BA_ "FlexKomSigLaenge" SG_ 564 IBS_SOF_V 32;
BA_ "FlexKomSigName" SG_ 564 IBS_SOF_V "PN14_IBS_DATA_2";
BA_ "FlexKomComment" SG_ 564 IBS_SOF_V "IBS Battery Information additional";
BA_ "FlexKomIsMotorola" SG_ 564 IBS_SOF_V 1;
BA_ "GenSigSNA" SG_ 564 IBS_SOF_V "FFh";
BA_ "GenSigCycleTime" SG_ 564 IBS_SOF_V_Accuracy 100;
BA_ "FlexKomSigStartValue" SG_ 564 IBS_SOF_V_Accuracy "FF0300FFh";
BA_ "GenSigStartValue" SG_ 564 IBS_SOF_V_Accuracy 3;
BA_ "FlexKomSID" SG_ 564 IBS_SOF_V_Accuracy 1405;
BA_ "FlexKomSigStartPos" SG_ 564 IBS_SOF_V_Accuracy 7;
BA_ "FlexKomSigLaenge" SG_ 564 IBS_SOF_V_Accuracy 32;
BA_ "FlexKomSigName" SG_ 564 IBS_SOF_V_Accuracy "PN14_IBS_DATA_2";
BA_ "FlexKomComment" SG_ 564 IBS_SOF_V_Accuracy "IBS Battery Information additional";
BA_ "FlexKomIsMotorola" SG_ 564 IBS_SOF_V_Accuracy 1;
BA_ "GenSigSNA" SG_ 564 IBS_SOF_V_Accuracy "3h";
BA_ "GenSigCycleTime" SG_ 564 IBS_Error_Calib 100;
BA_ "FlexKomSigStartValue" SG_ 564 IBS_Error_Calib "FF0300FFh";
BA_ "FlexKomSID" SG_ 564 IBS_Error_Calib 1405;
BA_ "FlexKomSigStartPos" SG_ 564 IBS_Error_Calib 7;
BA_ "FlexKomSigLaenge" SG_ 564 IBS_Error_Calib 32;
BA_ "FlexKomSigName" SG_ 564 IBS_Error_Calib "PN14_IBS_DATA_2";
BA_ "FlexKomComment" SG_ 564 IBS_Error_Calib "IBS Battery Information additional";
BA_ "FlexKomIsMotorola" SG_ 564 IBS_Error_Calib 1;
BA_ "GenSigSNA" SG_ 564 IBS_Error_Calib "0h";
BA_ "GenSigCycleTime" SG_ 564 IBS_Error_Ident 100;
BA_ "FlexKomSigStartValue" SG_ 564 IBS_Error_Ident "FF0300FFh";
BA_ "FlexKomSID" SG_ 564 IBS_Error_Ident 1405;
BA_ "FlexKomSigStartPos" SG_ 564 IBS_Error_Ident 7;
BA_ "FlexKomSigLaenge" SG_ 564 IBS_Error_Ident 32;
BA_ "FlexKomSigName" SG_ 564 IBS_Error_Ident "PN14_IBS_DATA_2";
BA_ "FlexKomComment" SG_ 564 IBS_Error_Ident "IBS Battery Information additional";
BA_ "FlexKomIsMotorola" SG_ 564 IBS_Error_Ident 1;
BA_ "GenSigSNA" SG_ 564 IBS_Error_Ident "0h";
BA_ "GenSigCycleTime" SG_ 564 IBS_Error_NVM 100;
BA_ "FlexKomSigStartValue" SG_ 564 IBS_Error_NVM "FF0300FFh";
BA_ "FlexKomSID" SG_ 564 IBS_Error_NVM 1405;
BA_ "FlexKomSigStartPos" SG_ 564 IBS_Error_NVM 7;
BA_ "FlexKomSigLaenge" SG_ 564 IBS_Error_NVM 32;
BA_ "FlexKomSigName" SG_ 564 IBS_Error_NVM "PN14_IBS_DATA_2";
BA_ "FlexKomComment" SG_ 564 IBS_Error_NVM "IBS Battery Information additional";
BA_ "FlexKomIsMotorola" SG_ 564 IBS_Error_NVM 1;
BA_ "GenSigSNA" SG_ 564 IBS_Error_NVM "0h";
BA_ "GenSigCycleTime" SG_ 564 Converter_1_State 100;
BA_ "FlexKomSigStartValue" SG_ 564 Converter_1_State "00h";
BA_ "FlexKomSID" SG_ 564 Converter_1_State 1406;
BA_ "FlexKomSigStartPos" SG_ 564 Converter_1_State 23;
BA_ "FlexKomSigLaenge" SG_ 564 Converter_1_State 8;
BA_ "FlexKomSigName" SG_ 564 Converter_1_State "DC_2_DC_INFO";
BA_ "FlexKomComment" SG_ 564 Converter_1_State "DC to DC information";
BA_ "FlexKomIsMotorola" SG_ 564 Converter_1_State 1;
BA_ "GenSigSNA" SG_ 564 Converter_1_State "0h";
BA_ "GenSigCycleTime" SG_ 564 Converter_1_Mode 100;
BA_ "FlexKomSigStartValue" SG_ 564 Converter_1_Mode "00h";
BA_ "FlexKomSID" SG_ 564 Converter_1_Mode 1406;
BA_ "FlexKomSigStartPos" SG_ 564 Converter_1_Mode 23;
BA_ "FlexKomSigLaenge" SG_ 564 Converter_1_Mode 8;
BA_ "FlexKomSigName" SG_ 564 Converter_1_Mode "DC_2_DC_INFO";
BA_ "FlexKomComment" SG_ 564 Converter_1_Mode "DC to DC information";
BA_ "FlexKomIsMotorola" SG_ 564 Converter_1_Mode 1;
BA_ "GenSigSNA" SG_ 564 Converter_1_Mode "0h";
BA_ "GenSigCycleTime" SG_ 564 INVERTER_ON 100;
BA_ "FlexKomSigStartValue" SG_ 564 INVERTER_ON "00h";
BA_ "FlexKomSID" SG_ 564 INVERTER_ON 831;
BA_ "FlexKomSigStartPos" SG_ 564 INVERTER_ON 20;
BA_ "FlexKomSigLaenge" SG_ 564 INVERTER_ON 1;
BA_ "FlexKomSigName" SG_ 564 INVERTER_ON "INVERTER_ON";
BA_ "FlexKomComment" SG_ 564 INVERTER_ON "Inverter is on; [1] = True";
BA_ "FlexKomIsMotorola" SG_ 564 INVERTER_ON 1;
BA_ "GenSigSNA" SG_ 564 INVERTER_ON "0h";
BA_ "GenSigCycleTime" SG_ 564 AM_ECM_Trace 100;
BA_ "FlexKomSigStartValue" SG_ 564 AM_ECM_Trace "00h";
BA_ "FlexKomSID" SG_ 564 AM_ECM_Trace 1942;
BA_ "FlexKomSigStartPos" SG_ 564 AM_ECM_Trace 23;
BA_ "FlexKomSigLaenge" SG_ 564 AM_ECM_Trace 2;
BA_ "FlexKomSigName" SG_ 564 AM_ECM_Trace "AM_ECM_Trace";
BA_ "FlexKomComment" SG_ 564 AM_ECM_Trace "Aftermarket ECM trace";
BA_ "FlexKomIsMotorola" SG_ 564 AM_ECM_Trace 1;
BA_ "GenSigSNA" SG_ 564 AM_ECM_Trace "3h";
BA_ "GenSigCycleTime" SG_ 564 IBS_SOF_V1 100;
BA_ "FlexKomSigStartValue" SG_ 564 IBS_SOF_V1 "FF0300FFh";
BA_ "GenSigStartValue" SG_ 564 IBS_SOF_V1 255;
BA_ "FlexKomSID" SG_ 564 IBS_SOF_V1 1405;
BA_ "FlexKomSigStartPos" SG_ 564 IBS_SOF_V1 7;
BA_ "FlexKomSigLaenge" SG_ 564 IBS_SOF_V1 32;
BA_ "FlexKomSigName" SG_ 564 IBS_SOF_V1 "PN14_IBS_DATA_2";
BA_ "FlexKomComment" SG_ 564 IBS_SOF_V1 "IBS Battery Information additional";
BA_ "FlexKomIsMotorola" SG_ 564 IBS_SOF_V1 1;
BA_ "GenSigSNA" SG_ 564 IBS_SOF_V1 "FFh";
BA_ "GenSigCycleTime" SG_ 570 AUS 20;
BA_ "FlexKomSigStartValue" SG_ 570 AUS "0000FFh";
BA_ "FlexKomSID" SG_ 570 AUS 421;
BA_ "FlexKomSigStartPos" SG_ 570 AUS 7;
BA_ "FlexKomSigLaenge" SG_ 570 AUS 24;
BA_ "FlexKomSigName" SG_ 570 AUS "CrsCtrlLvrStat";
BA_ "FlexKomComment" SG_ 570 AUS "Cruise Control Lever Status";
BA_ "FlexKomIsMotorola" SG_ 570 AUS 1;
BA_ "GenSigSNA" SG_ 570 AUS "0h";
BA_ "GenSigCycleTime" SG_ 570 WA 20;
BA_ "FlexKomSigStartValue" SG_ 570 WA "0000FFh";
BA_ "FlexKomSID" SG_ 570 WA 421;
BA_ "FlexKomSigStartPos" SG_ 570 WA 7;
BA_ "FlexKomSigLaenge" SG_ 570 WA 24;
BA_ "FlexKomSigName" SG_ 570 WA "CrsCtrlLvrStat";
BA_ "FlexKomComment" SG_ 570 WA "Cruise Control Lever Status";
BA_ "FlexKomIsMotorola" SG_ 570 WA 1;
BA_ "GenSigSNA" SG_ 570 WA "0h";
BA_ "GenSigCycleTime" SG_ 570 S_PLUS_B 20;
BA_ "FlexKomSigStartValue" SG_ 570 S_PLUS_B "0000FFh";
BA_ "FlexKomSID" SG_ 570 S_PLUS_B 421;
BA_ "FlexKomSigStartPos" SG_ 570 S_PLUS_B 7;
BA_ "FlexKomSigLaenge" SG_ 570 S_PLUS_B 24;
BA_ "FlexKomSigName" SG_ 570 S_PLUS_B "CrsCtrlLvrStat";
BA_ "FlexKomComment" SG_ 570 S_PLUS_B "Cruise Control Lever Status";
BA_ "FlexKomIsMotorola" SG_ 570 S_PLUS_B 1;
BA_ "GenSigSNA" SG_ 570 S_PLUS_B "0h";
BA_ "GenSigCycleTime" SG_ 570 S_MINUS_B 20;
BA_ "FlexKomSigStartValue" SG_ 570 S_MINUS_B "0000FFh";
BA_ "FlexKomSID" SG_ 570 S_MINUS_B 421;
BA_ "FlexKomSigStartPos" SG_ 570 S_MINUS_B 7;
BA_ "FlexKomSigLaenge" SG_ 570 S_MINUS_B 24;
BA_ "FlexKomSigName" SG_ 570 S_MINUS_B "CrsCtrlLvrStat";
BA_ "FlexKomComment" SG_ 570 S_MINUS_B "Cruise Control Lever Status";
BA_ "FlexKomIsMotorola" SG_ 570 S_MINUS_B 1;
BA_ "GenSigSNA" SG_ 570 S_MINUS_B "0h";
BA_ "GenSigCycleTime" SG_ 570 RESERVED1 20;
BA_ "FlexKomSigStartValue" SG_ 570 RESERVED1 "0000FFh";
BA_ "FlexKomSID" SG_ 570 RESERVED1 421;
BA_ "FlexKomSigStartPos" SG_ 570 RESERVED1 7;
BA_ "FlexKomSigLaenge" SG_ 570 RESERVED1 24;
BA_ "FlexKomSigName" SG_ 570 RESERVED1 "CrsCtrlLvrStat";
BA_ "FlexKomComment" SG_ 570 RESERVED1 "Cruise Control Lever Status";
BA_ "FlexKomIsMotorola" SG_ 570 RESERVED1 1;
BA_ "GenSigSNA" SG_ 570 RESERVED1 "0h";
BA_ "GenSigCycleTime" SG_ 570 WH_UP 20;
BA_ "FlexKomSigStartValue" SG_ 570 WH_UP "0000FFh";
BA_ "FlexKomSID" SG_ 570 WH_UP 421;
BA_ "FlexKomSigStartPos" SG_ 570 WH_UP 7;
BA_ "FlexKomSigLaenge" SG_ 570 WH_UP 24;
BA_ "FlexKomSigName" SG_ 570 WH_UP "CrsCtrlLvrStat";
BA_ "FlexKomComment" SG_ 570 WH_UP "Cruise Control Lever Status";
BA_ "FlexKomIsMotorola" SG_ 570 WH_UP 1;
BA_ "GenSigSNA" SG_ 570 WH_UP "0h";
BA_ "GenSigCycleTime" SG_ 570 CRUISE_TGL 20;
BA_ "FlexKomSigStartValue" SG_ 570 CRUISE_TGL "0000FFh";
BA_ "FlexKomSID" SG_ 570 CRUISE_TGL 421;
BA_ "FlexKomSigStartPos" SG_ 570 CRUISE_TGL 7;
BA_ "FlexKomSigLaenge" SG_ 570 CRUISE_TGL 24;
BA_ "FlexKomSigName" SG_ 570 CRUISE_TGL "CrsCtrlLvrStat";
BA_ "FlexKomComment" SG_ 570 CRUISE_TGL "Cruise Control Lever Status";
BA_ "FlexKomIsMotorola" SG_ 570 CRUISE_TGL 1;
BA_ "GenSigSNA" SG_ 570 CRUISE_TGL "0h";
BA_ "GenSigCycleTime" SG_ 570 ACC_MODE 20;
BA_ "FlexKomSigStartValue" SG_ 570 ACC_MODE "0000FFh";
BA_ "FlexKomSID" SG_ 570 ACC_MODE 421;
BA_ "FlexKomSigStartPos" SG_ 570 ACC_MODE 7;
BA_ "FlexKomSigLaenge" SG_ 570 ACC_MODE 24;
BA_ "FlexKomSigName" SG_ 570 ACC_MODE "CrsCtrlLvrStat";
BA_ "FlexKomComment" SG_ 570 ACC_MODE "Cruise Control Lever Status";
BA_ "FlexKomIsMotorola" SG_ 570 ACC_MODE 1;
BA_ "GenSigSNA" SG_ 570 ACC_MODE "0h";
BA_ "GenSigCycleTime" SG_ 570 MC_SCCM_CRS_CTRL 20;
BA_ "FlexKomSigStartValue" SG_ 570 MC_SCCM_CRS_CTRL "0000FFh";
BA_ "FlexKomSID" SG_ 570 MC_SCCM_CRS_CTRL 421;
BA_ "FlexKomSigStartPos" SG_ 570 MC_SCCM_CRS_CTRL 7;
BA_ "FlexKomSigLaenge" SG_ 570 MC_SCCM_CRS_CTRL 24;
BA_ "FlexKomSigName" SG_ 570 MC_SCCM_CRS_CTRL "CrsCtrlLvrStat";
BA_ "FlexKomComment" SG_ 570 MC_SCCM_CRS_CTRL "Cruise Control Lever Status";
BA_ "FlexKomIsMotorola" SG_ 570 MC_SCCM_CRS_CTRL 1;
BA_ "GenSigSNA" SG_ 570 MC_SCCM_CRS_CTRL "0h";
BA_ "GenSigCycleTime" SG_ 570 CRC_SCCM_CRS_CTRL 20;
BA_ "FlexKomSigStartValue" SG_ 570 CRC_SCCM_CRS_CTRL "0000FFh";
BA_ "GenSigStartValue" SG_ 570 CRC_SCCM_CRS_CTRL 255;
BA_ "FlexKomSID" SG_ 570 CRC_SCCM_CRS_CTRL 421;
BA_ "FlexKomSigStartPos" SG_ 570 CRC_SCCM_CRS_CTRL 7;
BA_ "FlexKomSigLaenge" SG_ 570 CRC_SCCM_CRS_CTRL 24;
BA_ "FlexKomSigName" SG_ 570 CRC_SCCM_CRS_CTRL "CrsCtrlLvrStat";
BA_ "FlexKomComment" SG_ 570 CRC_SCCM_CRS_CTRL "Cruise Control Lever Status";
BA_ "FlexKomIsMotorola" SG_ 570 CRC_SCCM_CRS_CTRL 1;
BA_ "GenSigSNA" SG_ 570 CRC_SCCM_CRS_CTRL "FFh";
BA_ "GenSigSendType" SG_ 571 CrusCnclSwitch 1;
BA_ "FlexKomSigStartValue" SG_ 571 CrusCnclSwitch "0000FFh";
BA_ "FlexKomSID" SG_ 571 CrusCnclSwitch 1848;
BA_ "FlexKomSigStartPos" SG_ 571 CrusCnclSwitch 7;
BA_ "FlexKomSigLaenge" SG_ 571 CrusCnclSwitch 24;
BA_ "FlexKomSigName" SG_ 571 CrusCnclSwitch "CrsCtrlLvrSts";
BA_ "FlexKomComment" SG_ 571 CrusCnclSwitch "Cruise Control Lever Status";
BA_ "FlexKomIsMotorola" SG_ 571 CrusCnclSwitch 1;
BA_ "GenSigSNA" SG_ 571 CrusCnclSwitch "0h";
BA_ "GenSigSendType" SG_ 571 ACC_DistSwDec 1;
BA_ "FlexKomSigStartValue" SG_ 571 ACC_DistSwDec "0000FFh";
BA_ "FlexKomSID" SG_ 571 ACC_DistSwDec 1848;
BA_ "FlexKomSigStartPos" SG_ 571 ACC_DistSwDec 7;
BA_ "FlexKomSigLaenge" SG_ 571 ACC_DistSwDec 24;
BA_ "FlexKomSigName" SG_ 571 ACC_DistSwDec "CrsCtrlLvrSts";
BA_ "FlexKomComment" SG_ 571 ACC_DistSwDec "Cruise Control Lever Status";
BA_ "FlexKomIsMotorola" SG_ 571 ACC_DistSwDec 1;
BA_ "GenSigSNA" SG_ 571 ACC_DistSwDec "0h";
BA_ "GenSigSendType" SG_ 571 AcceleratorSts 1;
BA_ "FlexKomSigStartValue" SG_ 571 AcceleratorSts "0000FFh";
BA_ "FlexKomSID" SG_ 571 AcceleratorSts 1848;
BA_ "FlexKomSigStartPos" SG_ 571 AcceleratorSts 7;
BA_ "FlexKomSigLaenge" SG_ 571 AcceleratorSts 24;
BA_ "FlexKomSigName" SG_ 571 AcceleratorSts "CrsCtrlLvrSts";
BA_ "FlexKomComment" SG_ 571 AcceleratorSts "Cruise Control Lever Status";
BA_ "FlexKomIsMotorola" SG_ 571 AcceleratorSts 1;
BA_ "GenSigSNA" SG_ 571 AcceleratorSts "0h";
BA_ "GenSigSendType" SG_ 571 DeceleratorSts 1;
BA_ "FlexKomSigStartValue" SG_ 571 DeceleratorSts "0000FFh";
BA_ "FlexKomSID" SG_ 571 DeceleratorSts 1848;
BA_ "FlexKomSigStartPos" SG_ 571 DeceleratorSts 7;
BA_ "FlexKomSigLaenge" SG_ 571 DeceleratorSts 24;
BA_ "FlexKomSigName" SG_ 571 DeceleratorSts "CrsCtrlLvrSts";
BA_ "FlexKomComment" SG_ 571 DeceleratorSts "Cruise Control Lever Status";
BA_ "FlexKomIsMotorola" SG_ 571 DeceleratorSts 1;
BA_ "GenSigSNA" SG_ 571 DeceleratorSts "0h";
BA_ "GenSigSendType" SG_ 571 ResumeSwitch 1;
BA_ "FlexKomSigStartValue" SG_ 571 ResumeSwitch "0000FFh";
BA_ "FlexKomSID" SG_ 571 ResumeSwitch 1848;
BA_ "FlexKomSigStartPos" SG_ 571 ResumeSwitch 7;
BA_ "FlexKomSigLaenge" SG_ 571 ResumeSwitch 24;
BA_ "FlexKomSigName" SG_ 571 ResumeSwitch "CrsCtrlLvrSts";
BA_ "FlexKomComment" SG_ 571 ResumeSwitch "Cruise Control Lever Status";
BA_ "FlexKomIsMotorola" SG_ 571 ResumeSwitch 1;
BA_ "GenSigSNA" SG_ 571 ResumeSwitch "0h";
BA_ "GenSigSendType" SG_ 571 CruiseControlFailSts 1;
BA_ "FlexKomSigStartValue" SG_ 571 CruiseControlFailSts "0000FFh";
BA_ "FlexKomSID" SG_ 571 CruiseControlFailSts 1848;
BA_ "FlexKomSigStartPos" SG_ 571 CruiseControlFailSts 7;
BA_ "FlexKomSigLaenge" SG_ 571 CruiseControlFailSts 24;
BA_ "FlexKomSigName" SG_ 571 CruiseControlFailSts "CrsCtrlLvrSts";
BA_ "FlexKomComment" SG_ 571 CruiseControlFailSts "Cruise Control Lever Status";
BA_ "FlexKomIsMotorola" SG_ 571 CruiseControlFailSts 1;
BA_ "GenSigSNA" SG_ 571 CruiseControlFailSts "0h";
BA_ "GenSigSendType" SG_ 571 CruiseControlOnOffSts 1;
BA_ "FlexKomSigStartValue" SG_ 571 CruiseControlOnOffSts "0000FFh";
BA_ "FlexKomSID" SG_ 571 CruiseControlOnOffSts 1848;
BA_ "FlexKomSigStartPos" SG_ 571 CruiseControlOnOffSts 7;
BA_ "FlexKomSigLaenge" SG_ 571 CruiseControlOnOffSts 24;
BA_ "FlexKomSigName" SG_ 571 CruiseControlOnOffSts "CrsCtrlLvrSts";
BA_ "FlexKomComment" SG_ 571 CruiseControlOnOffSts "Cruise Control Lever Status";
BA_ "FlexKomIsMotorola" SG_ 571 CruiseControlOnOffSts 1;
BA_ "GenSigSNA" SG_ 571 CruiseControlOnOffSts "0h";
BA_ "GenSigSendType" SG_ 571 ACC_On 1;
BA_ "FlexKomSigStartValue" SG_ 571 ACC_On "0000FFh";
BA_ "FlexKomSID" SG_ 571 ACC_On 1848;
BA_ "FlexKomSigStartPos" SG_ 571 ACC_On 7;
BA_ "FlexKomSigLaenge" SG_ 571 ACC_On 24;
BA_ "FlexKomSigName" SG_ 571 ACC_On "CrsCtrlLvrSts";
BA_ "FlexKomComment" SG_ 571 ACC_On "Cruise Control Lever Status";
BA_ "FlexKomIsMotorola" SG_ 571 ACC_On 1;
BA_ "GenSigSNA" SG_ 571 ACC_On "0h";
BA_ "GenSigSendType" SG_ 571 ACC_DistSwInc 1;
BA_ "FlexKomSigStartValue" SG_ 571 ACC_DistSwInc "0000FFh";
BA_ "FlexKomSID" SG_ 571 ACC_DistSwInc 1848;
BA_ "FlexKomSigStartPos" SG_ 571 ACC_DistSwInc 7;
BA_ "FlexKomSigLaenge" SG_ 571 ACC_DistSwInc 24;
BA_ "FlexKomSigName" SG_ 571 ACC_DistSwInc "CrsCtrlLvrSts";
BA_ "FlexKomComment" SG_ 571 ACC_DistSwInc "Cruise Control Lever Status";
BA_ "FlexKomIsMotorola" SG_ 571 ACC_DistSwInc 1;
BA_ "GenSigSNA" SG_ 571 ACC_DistSwInc "0h";
BA_ "GenSigSendType" SG_ 571 SpeedLimiterOnOffSts 1;
BA_ "FlexKomSigStartValue" SG_ 571 SpeedLimiterOnOffSts "0000FFh";
BA_ "FlexKomSID" SG_ 571 SpeedLimiterOnOffSts 1848;
BA_ "FlexKomSigStartPos" SG_ 571 SpeedLimiterOnOffSts 7;
BA_ "FlexKomSigLaenge" SG_ 571 SpeedLimiterOnOffSts 24;
BA_ "FlexKomSigName" SG_ 571 SpeedLimiterOnOffSts "CrsCtrlLvrSts";
BA_ "FlexKomComment" SG_ 571 SpeedLimiterOnOffSts "Cruise Control Lever Status";
BA_ "FlexKomIsMotorola" SG_ 571 SpeedLimiterOnOffSts 1;
BA_ "GenSigSNA" SG_ 571 SpeedLimiterOnOffSts "0h";
BA_ "GenSigSendType" SG_ 571 MC_CSWC_1 1;
BA_ "FlexKomSigStartValue" SG_ 571 MC_CSWC_1 "0000FFh";
BA_ "FlexKomSID" SG_ 571 MC_CSWC_1 1848;
BA_ "FlexKomSigStartPos" SG_ 571 MC_CSWC_1 7;
BA_ "FlexKomSigLaenge" SG_ 571 MC_CSWC_1 24;
BA_ "FlexKomSigName" SG_ 571 MC_CSWC_1 "CrsCtrlLvrSts";
BA_ "FlexKomComment" SG_ 571 MC_CSWC_1 "Cruise Control Lever Status";
BA_ "FlexKomIsMotorola" SG_ 571 MC_CSWC_1 1;
BA_ "GenSigSNA" SG_ 571 MC_CSWC_1 "0h";
BA_ "GenSigSendType" SG_ 571 CRC_CSWC_1 1;
BA_ "FlexKomSigStartValue" SG_ 571 CRC_CSWC_1 "0000FFh";
BA_ "GenSigStartValue" SG_ 571 CRC_CSWC_1 255;
BA_ "FlexKomSID" SG_ 571 CRC_CSWC_1 1848;
BA_ "FlexKomSigStartPos" SG_ 571 CRC_CSWC_1 7;
BA_ "FlexKomSigLaenge" SG_ 571 CRC_CSWC_1 24;
BA_ "FlexKomSigName" SG_ 571 CRC_CSWC_1 "CrsCtrlLvrSts";
BA_ "FlexKomComment" SG_ 571 CRC_CSWC_1 "Cruise Control Lever Status";
BA_ "FlexKomIsMotorola" SG_ 571 CRC_CSWC_1 1;
BA_ "GenSigSNA" SG_ 571 CRC_CSWC_1 "FFh";
BA_ "GenSigSendType" SG_ 584 PN14_LS_Actv 5;
BA_ "GenSigCycleTime" SG_ 584 PN14_LS_Actv 500;
BA_ "FlexKomSigStartValue" SG_ 584 PN14_LS_Actv "0000FFFFFF03FFFFh";
BA_ "GenSigTimeout_IC" SG_ 584 PN14_LS_Actv 5250;
BA_ "FlexKomSID" SG_ 584 PN14_LS_Actv 1092;
BA_ "FlexKomSigStartPos" SG_ 584 PN14_LS_Actv 7;
BA_ "FlexKomSigLaenge" SG_ 584 PN14_LS_Actv 64;
BA_ "FlexKomSigName" SG_ 584 PN14_LS_Actv "PN14_LHC_Stat";
BA_ "FlexKomComment" SG_ 584 PN14_LS_Actv "14 V powernet limp-home cutoff state";
BA_ "FlexKomIsMotorola" SG_ 584 PN14_LS_Actv 1;
BA_ "GenSigSNA" SG_ 584 PN14_LS_Actv "0h";
BA_ "GenSigSendType" SG_ 584 PN14_Key_Off_Load_Shed 5;
BA_ "GenSigCycleTime" SG_ 584 PN14_Key_Off_Load_Shed 500;
BA_ "FlexKomSigStartValue" SG_ 584 PN14_Key_Off_Load_Shed "0000FFFFFF03FFFFh";
BA_ "FlexKomSID" SG_ 584 PN14_Key_Off_Load_Shed 1092;
BA_ "FlexKomSigStartPos" SG_ 584 PN14_Key_Off_Load_Shed 7;
BA_ "FlexKomSigLaenge" SG_ 584 PN14_Key_Off_Load_Shed 64;
BA_ "FlexKomSigName" SG_ 584 PN14_Key_Off_Load_Shed "PN14_LHC_Stat";
BA_ "FlexKomComment" SG_ 584 PN14_Key_Off_Load_Shed "14 V powernet limp-home cutoff state";
BA_ "FlexKomIsMotorola" SG_ 584 PN14_Key_Off_Load_Shed 1;
BA_ "GenSigSNA" SG_ 584 PN14_Key_Off_Load_Shed "3h";
BA_ "GenSigSendType" SG_ 584 PN14_LS_Lvl1 5;
BA_ "GenSigCycleTime" SG_ 584 PN14_LS_Lvl1 500;
BA_ "FlexKomSigStartValue" SG_ 584 PN14_LS_Lvl1 "0000FFFFFF03FFFFh";
BA_ "FlexKomSID" SG_ 584 PN14_LS_Lvl1 1092;
BA_ "FlexKomSigStartPos" SG_ 584 PN14_LS_Lvl1 7;
BA_ "FlexKomSigLaenge" SG_ 584 PN14_LS_Lvl1 64;
BA_ "FlexKomSigName" SG_ 584 PN14_LS_Lvl1 "PN14_LHC_Stat";
BA_ "FlexKomComment" SG_ 584 PN14_LS_Lvl1 "14 V powernet limp-home cutoff state";
BA_ "FlexKomIsMotorola" SG_ 584 PN14_LS_Lvl1 1;
BA_ "GenSigSNA" SG_ 584 PN14_LS_Lvl1 "0h";
BA_ "GenSigSendType" SG_ 584 PN14_LS_Lvl2 5;
BA_ "GenSigCycleTime" SG_ 584 PN14_LS_Lvl2 500;
BA_ "FlexKomSigStartValue" SG_ 584 PN14_LS_Lvl2 "0000FFFFFF03FFFFh";
BA_ "FlexKomSID" SG_ 584 PN14_LS_Lvl2 1092;
BA_ "FlexKomSigStartPos" SG_ 584 PN14_LS_Lvl2 7;
BA_ "FlexKomSigLaenge" SG_ 584 PN14_LS_Lvl2 64;
BA_ "FlexKomSigName" SG_ 584 PN14_LS_Lvl2 "PN14_LHC_Stat";
BA_ "FlexKomComment" SG_ 584 PN14_LS_Lvl2 "14 V powernet limp-home cutoff state";
BA_ "FlexKomIsMotorola" SG_ 584 PN14_LS_Lvl2 1;
BA_ "GenSigSNA" SG_ 584 PN14_LS_Lvl2 "0h";
BA_ "GenSigSendType" SG_ 584 PN14_LS_Lvl3 5;
BA_ "GenSigCycleTime" SG_ 584 PN14_LS_Lvl3 500;
BA_ "FlexKomSigStartValue" SG_ 584 PN14_LS_Lvl3 "0000FFFFFF03FFFFh";
BA_ "FlexKomSID" SG_ 584 PN14_LS_Lvl3 1092;
BA_ "FlexKomSigStartPos" SG_ 584 PN14_LS_Lvl3 7;
BA_ "FlexKomSigLaenge" SG_ 584 PN14_LS_Lvl3 64;
BA_ "FlexKomSigName" SG_ 584 PN14_LS_Lvl3 "PN14_LHC_Stat";
BA_ "FlexKomComment" SG_ 584 PN14_LS_Lvl3 "14 V powernet limp-home cutoff state";
BA_ "FlexKomIsMotorola" SG_ 584 PN14_LS_Lvl3 1;
BA_ "GenSigSNA" SG_ 584 PN14_LS_Lvl3 "0h";
BA_ "GenSigSendType" SG_ 584 PN14_LS_Lvl4 5;
BA_ "GenSigCycleTime" SG_ 584 PN14_LS_Lvl4 500;
BA_ "FlexKomSigStartValue" SG_ 584 PN14_LS_Lvl4 "0000FFFFFF03FFFFh";
BA_ "FlexKomSID" SG_ 584 PN14_LS_Lvl4 1092;
BA_ "FlexKomSigStartPos" SG_ 584 PN14_LS_Lvl4 7;
BA_ "FlexKomSigLaenge" SG_ 584 PN14_LS_Lvl4 64;
BA_ "FlexKomSigName" SG_ 584 PN14_LS_Lvl4 "PN14_LHC_Stat";
BA_ "FlexKomComment" SG_ 584 PN14_LS_Lvl4 "14 V powernet limp-home cutoff state";
BA_ "FlexKomIsMotorola" SG_ 584 PN14_LS_Lvl4 1;
BA_ "GenSigSNA" SG_ 584 PN14_LS_Lvl4 "0h";
BA_ "GenSigSendType" SG_ 584 PN14_LS_Lvl5 5;
BA_ "GenSigCycleTime" SG_ 584 PN14_LS_Lvl5 500;
BA_ "FlexKomSigStartValue" SG_ 584 PN14_LS_Lvl5 "0000FFFFFF03FFFFh";
BA_ "FlexKomSID" SG_ 584 PN14_LS_Lvl5 1092;
BA_ "FlexKomSigStartPos" SG_ 584 PN14_LS_Lvl5 7;
BA_ "FlexKomSigLaenge" SG_ 584 PN14_LS_Lvl5 64;
BA_ "FlexKomSigName" SG_ 584 PN14_LS_Lvl5 "PN14_LHC_Stat";
BA_ "FlexKomComment" SG_ 584 PN14_LS_Lvl5 "14 V powernet limp-home cutoff state";
BA_ "FlexKomIsMotorola" SG_ 584 PN14_LS_Lvl5 1;
BA_ "GenSigSNA" SG_ 584 PN14_LS_Lvl5 "0h";
BA_ "GenSigSendType" SG_ 584 PN14_LS_Lvl6 5;
BA_ "GenSigCycleTime" SG_ 584 PN14_LS_Lvl6 500;
BA_ "FlexKomSigStartValue" SG_ 584 PN14_LS_Lvl6 "0000FFFFFF03FFFFh";
BA_ "FlexKomSID" SG_ 584 PN14_LS_Lvl6 1092;
BA_ "FlexKomSigStartPos" SG_ 584 PN14_LS_Lvl6 7;
BA_ "FlexKomSigLaenge" SG_ 584 PN14_LS_Lvl6 64;
BA_ "FlexKomSigName" SG_ 584 PN14_LS_Lvl6 "PN14_LHC_Stat";
BA_ "FlexKomComment" SG_ 584 PN14_LS_Lvl6 "14 V powernet limp-home cutoff state";
BA_ "FlexKomIsMotorola" SG_ 584 PN14_LS_Lvl6 1;
BA_ "GenSigSNA" SG_ 584 PN14_LS_Lvl6 "0h";
BA_ "GenSigSendType" SG_ 584 PN14_LS_Lvl7 5;
BA_ "GenSigCycleTime" SG_ 584 PN14_LS_Lvl7 500;
BA_ "FlexKomSigStartValue" SG_ 584 PN14_LS_Lvl7 "0000FFFFFF03FFFFh";
BA_ "FlexKomSID" SG_ 584 PN14_LS_Lvl7 1092;
BA_ "FlexKomSigStartPos" SG_ 584 PN14_LS_Lvl7 7;
BA_ "FlexKomSigLaenge" SG_ 584 PN14_LS_Lvl7 64;
BA_ "FlexKomSigName" SG_ 584 PN14_LS_Lvl7 "PN14_LHC_Stat";
BA_ "FlexKomComment" SG_ 584 PN14_LS_Lvl7 "14 V powernet limp-home cutoff state";
BA_ "FlexKomIsMotorola" SG_ 584 PN14_LS_Lvl7 1;
BA_ "GenSigSNA" SG_ 584 PN14_LS_Lvl7 "0h";
BA_ "GenSigSendType" SG_ 584 PN14_LS_Lvl8 5;
BA_ "GenSigCycleTime" SG_ 584 PN14_LS_Lvl8 500;
BA_ "FlexKomSigStartValue" SG_ 584 PN14_LS_Lvl8 "0000FFFFFF03FFFFh";
BA_ "FlexKomSID" SG_ 584 PN14_LS_Lvl8 1092;
BA_ "FlexKomSigStartPos" SG_ 584 PN14_LS_Lvl8 7;
BA_ "FlexKomSigLaenge" SG_ 584 PN14_LS_Lvl8 64;
BA_ "FlexKomSigName" SG_ 584 PN14_LS_Lvl8 "PN14_LHC_Stat";
BA_ "FlexKomComment" SG_ 584 PN14_LS_Lvl8 "14 V powernet limp-home cutoff state";
BA_ "FlexKomIsMotorola" SG_ 584 PN14_LS_Lvl8 1;
BA_ "GenSigSNA" SG_ 584 PN14_LS_Lvl8 "0h";
BA_ "GenSigSendType" SG_ 584 PN14_LS_Lvl9 5;
BA_ "GenSigCycleTime" SG_ 584 PN14_LS_Lvl9 500;
BA_ "FlexKomSigStartValue" SG_ 584 PN14_LS_Lvl9 "0000FFFFFF03FFFFh";
BA_ "FlexKomSID" SG_ 584 PN14_LS_Lvl9 1092;
BA_ "FlexKomSigStartPos" SG_ 584 PN14_LS_Lvl9 7;
BA_ "FlexKomSigLaenge" SG_ 584 PN14_LS_Lvl9 64;
BA_ "FlexKomSigName" SG_ 584 PN14_LS_Lvl9 "PN14_LHC_Stat";
BA_ "FlexKomComment" SG_ 584 PN14_LS_Lvl9 "14 V powernet limp-home cutoff state";
BA_ "FlexKomIsMotorola" SG_ 584 PN14_LS_Lvl9 1;
BA_ "GenSigSNA" SG_ 584 PN14_LS_Lvl9 "0h";
BA_ "GenSigSendType" SG_ 584 PN14_LS_Lvl10 5;
BA_ "GenSigCycleTime" SG_ 584 PN14_LS_Lvl10 500;
BA_ "FlexKomSigStartValue" SG_ 584 PN14_LS_Lvl10 "0000FFFFFF03FFFFh";
BA_ "FlexKomSID" SG_ 584 PN14_LS_Lvl10 1092;
BA_ "FlexKomSigStartPos" SG_ 584 PN14_LS_Lvl10 7;
BA_ "FlexKomSigLaenge" SG_ 584 PN14_LS_Lvl10 64;
BA_ "FlexKomSigName" SG_ 584 PN14_LS_Lvl10 "PN14_LHC_Stat";
BA_ "FlexKomComment" SG_ 584 PN14_LS_Lvl10 "14 V powernet limp-home cutoff state";
BA_ "FlexKomIsMotorola" SG_ 584 PN14_LS_Lvl10 1;
BA_ "GenSigSNA" SG_ 584 PN14_LS_Lvl10 "0h";
BA_ "GenSigSendType" SG_ 584 IBS_SOC 5;
BA_ "GenSigCycleTime" SG_ 584 IBS_SOC 500;
BA_ "FlexKomSigStartValue" SG_ 584 IBS_SOC "0000FFFFFF03FFFFh";
BA_ "GenSigStartValue" SG_ 584 IBS_SOC 255;
BA_ "GenSigTimeout_ORC" SG_ 584 IBS_SOC 1750;
BA_ "FlexKomSID" SG_ 584 IBS_SOC 1092;
BA_ "FlexKomSigStartPos" SG_ 584 IBS_SOC 7;
BA_ "FlexKomSigLaenge" SG_ 584 IBS_SOC 64;
BA_ "FlexKomSigName" SG_ 584 IBS_SOC "PN14_LHC_Stat";
BA_ "FlexKomComment" SG_ 584 IBS_SOC "14 V powernet limp-home cutoff state";
BA_ "FlexKomIsMotorola" SG_ 584 IBS_SOC 1;
BA_ "GenSigSNA" SG_ 584 IBS_SOC "FFh";
BA_ "GenSigSendType" SG_ 584 IBS_SOF_Q 5;
BA_ "GenSigCycleTime" SG_ 584 IBS_SOF_Q 500;
BA_ "FlexKomSigStartValue" SG_ 584 IBS_SOF_Q "0000FFFFFF03FFFFh";
BA_ "GenSigStartValue" SG_ 584 IBS_SOF_Q 255;
BA_ "FlexKomSID" SG_ 584 IBS_SOF_Q 1092;
BA_ "FlexKomSigStartPos" SG_ 584 IBS_SOF_Q 7;
BA_ "FlexKomSigLaenge" SG_ 584 IBS_SOF_Q 64;
BA_ "FlexKomSigName" SG_ 584 IBS_SOF_Q "PN14_LHC_Stat";
BA_ "FlexKomComment" SG_ 584 IBS_SOF_Q "14 V powernet limp-home cutoff state";
BA_ "FlexKomIsMotorola" SG_ 584 IBS_SOF_Q 1;
BA_ "GenSigSNA" SG_ 584 IBS_SOF_Q "FFh";
BA_ "GenSigSendType" SG_ 584 IBS_SOH_Q 5;
BA_ "GenSigCycleTime" SG_ 584 IBS_SOH_Q 500;
BA_ "FlexKomSigStartValue" SG_ 584 IBS_SOH_Q "0000FFFFFF03FFFFh";
BA_ "GenSigStartValue" SG_ 584 IBS_SOH_Q 255;
BA_ "FlexKomSID" SG_ 584 IBS_SOH_Q 1092;
BA_ "FlexKomSigStartPos" SG_ 584 IBS_SOH_Q 7;
BA_ "FlexKomSigLaenge" SG_ 584 IBS_SOH_Q 64;
BA_ "FlexKomSigName" SG_ 584 IBS_SOH_Q "PN14_LHC_Stat";
BA_ "FlexKomComment" SG_ 584 IBS_SOH_Q "14 V powernet limp-home cutoff state";
BA_ "FlexKomIsMotorola" SG_ 584 IBS_SOH_Q 1;
BA_ "GenSigSNA" SG_ 584 IBS_SOH_Q "FFh";
BA_ "GenSigSendType" SG_ 584 IBS_SOF_t 5;
BA_ "GenSigCycleTime" SG_ 584 IBS_SOF_t 500;
BA_ "FlexKomSigStartValue" SG_ 584 IBS_SOF_t "0000FFFFFF03FFFFh";
BA_ "GenSigStartValue" SG_ 584 IBS_SOF_t 1023;
BA_ "FlexKomSID" SG_ 584 IBS_SOF_t 1092;
BA_ "FlexKomSigStartPos" SG_ 584 IBS_SOF_t 7;
BA_ "FlexKomSigLaenge" SG_ 584 IBS_SOF_t 64;
BA_ "FlexKomSigName" SG_ 584 IBS_SOF_t "PN14_LHC_Stat";
BA_ "FlexKomComment" SG_ 584 IBS_SOF_t "14 V powernet limp-home cutoff state";
BA_ "FlexKomIsMotorola" SG_ 584 IBS_SOF_t 1;
BA_ "GenSigSNA" SG_ 584 IBS_SOF_t "3FFh";
BA_ "GenSigSendType" SG_ 584 Batt_ST_Crit 5;
BA_ "GenSigCycleTime" SG_ 584 Batt_ST_Crit 500;
BA_ "FlexKomSigStartValue" SG_ 584 Batt_ST_Crit "0000FFFFFF03FFFFh";
BA_ "FlexKomSID" SG_ 584 Batt_ST_Crit 1092;
BA_ "FlexKomSigStartPos" SG_ 584 Batt_ST_Crit 7;
BA_ "FlexKomSigLaenge" SG_ 584 Batt_ST_Crit 64;
BA_ "FlexKomSigName" SG_ 584 Batt_ST_Crit "PN14_LHC_Stat";
BA_ "FlexKomComment" SG_ 584 Batt_ST_Crit "14 V powernet limp-home cutoff state";
BA_ "FlexKomIsMotorola" SG_ 584 Batt_ST_Crit 1;
BA_ "GenSigSNA" SG_ 584 Batt_ST_Crit "0h";
BA_ "GenSigSendType" SG_ 584 IBS_SOC_Accuracy 5;
BA_ "GenSigCycleTime" SG_ 584 IBS_SOC_Accuracy 500;
BA_ "FlexKomSigStartValue" SG_ 584 IBS_SOC_Accuracy "0000FFFFFF03FFFFh";
BA_ "GenSigStartValue" SG_ 584 IBS_SOC_Accuracy 3;
BA_ "FlexKomSID" SG_ 584 IBS_SOC_Accuracy 1092;
BA_ "FlexKomSigStartPos" SG_ 584 IBS_SOC_Accuracy 7;
BA_ "FlexKomSigLaenge" SG_ 584 IBS_SOC_Accuracy 64;
BA_ "FlexKomSigName" SG_ 584 IBS_SOC_Accuracy "PN14_LHC_Stat";
BA_ "FlexKomComment" SG_ 584 IBS_SOC_Accuracy "14 V powernet limp-home cutoff state";
BA_ "FlexKomIsMotorola" SG_ 584 IBS_SOC_Accuracy 1;
BA_ "GenSigSNA" SG_ 584 IBS_SOC_Accuracy "3h";
BA_ "GenSigSendType" SG_ 584 IBS_SOF_Q_Accuracy 5;
BA_ "GenSigCycleTime" SG_ 584 IBS_SOF_Q_Accuracy 500;
BA_ "FlexKomSigStartValue" SG_ 584 IBS_SOF_Q_Accuracy "0000FFFFFF03FFFFh";
BA_ "GenSigStartValue" SG_ 584 IBS_SOF_Q_Accuracy 3;
BA_ "FlexKomSID" SG_ 584 IBS_SOF_Q_Accuracy 1092;
BA_ "FlexKomSigStartPos" SG_ 584 IBS_SOF_Q_Accuracy 7;
BA_ "FlexKomSigLaenge" SG_ 584 IBS_SOF_Q_Accuracy 64;
BA_ "FlexKomSigName" SG_ 584 IBS_SOF_Q_Accuracy "PN14_LHC_Stat";
BA_ "FlexKomComment" SG_ 584 IBS_SOF_Q_Accuracy "14 V powernet limp-home cutoff state";
BA_ "FlexKomIsMotorola" SG_ 584 IBS_SOF_Q_Accuracy 1;
BA_ "GenSigSNA" SG_ 584 IBS_SOF_Q_Accuracy "3h";
BA_ "GenSigSendType" SG_ 584 IBS_SOH_Q_Accuracy 5;
BA_ "GenSigCycleTime" SG_ 584 IBS_SOH_Q_Accuracy 500;
BA_ "FlexKomSigStartValue" SG_ 584 IBS_SOH_Q_Accuracy "0000FFFFFF03FFFFh";
BA_ "GenSigStartValue" SG_ 584 IBS_SOH_Q_Accuracy 3;
BA_ "FlexKomSID" SG_ 584 IBS_SOH_Q_Accuracy 1092;
BA_ "FlexKomSigStartPos" SG_ 584 IBS_SOH_Q_Accuracy 7;
BA_ "FlexKomSigLaenge" SG_ 584 IBS_SOH_Q_Accuracy 64;
BA_ "FlexKomSigName" SG_ 584 IBS_SOH_Q_Accuracy "PN14_LHC_Stat";
BA_ "FlexKomComment" SG_ 584 IBS_SOH_Q_Accuracy "14 V powernet limp-home cutoff state";
BA_ "FlexKomIsMotorola" SG_ 584 IBS_SOH_Q_Accuracy 1;
BA_ "GenSigSNA" SG_ 584 IBS_SOH_Q_Accuracy "3h";
BA_ "GenSigSendType" SG_ 584 IBS_SOF_t_Accuracy 5;
BA_ "GenSigCycleTime" SG_ 584 IBS_SOF_t_Accuracy 500;
BA_ "FlexKomSigStartValue" SG_ 584 IBS_SOF_t_Accuracy "0000FFFFFF03FFFFh";
BA_ "GenSigStartValue" SG_ 584 IBS_SOF_t_Accuracy 3;
BA_ "FlexKomSID" SG_ 584 IBS_SOF_t_Accuracy 1092;
BA_ "FlexKomSigStartPos" SG_ 584 IBS_SOF_t_Accuracy 7;
BA_ "FlexKomSigLaenge" SG_ 584 IBS_SOF_t_Accuracy 64;
BA_ "FlexKomSigName" SG_ 584 IBS_SOF_t_Accuracy "PN14_LHC_Stat";
BA_ "FlexKomComment" SG_ 584 IBS_SOF_t_Accuracy "14 V powernet limp-home cutoff state";
BA_ "FlexKomIsMotorola" SG_ 584 IBS_SOF_t_Accuracy 1;
BA_ "GenSigSNA" SG_ 584 IBS_SOF_t_Accuracy "3h";
BA_ "GenSigSendType" SG_ 608 RR_PTS_Dist 5;
BA_ "GenSigCycleTime" SG_ 608 RR_PTS_Dist 500;
BA_ "FlexKomSigStartValue" SG_ 608 RR_PTS_Dist "FF80AAAAAAAA0AFFh";
BA_ "GenSigStartValue" SG_ 608 RR_PTS_Dist 255;
BA_ "FlexKomSID" SG_ 608 RR_PTS_Dist 1954;
BA_ "FlexKomSigStartPos" SG_ 608 RR_PTS_Dist 7;
BA_ "FlexKomSigLaenge" SG_ 608 RR_PTS_Dist 64;
BA_ "FlexKomSigName" SG_ 608 RR_PTS_Dist "PTS_2_Pkt";
BA_ "FlexKomComment" SG_ 608 RR_PTS_Dist "PTS 2 message packet";
BA_ "FlexKomIsMotorola" SG_ 608 RR_PTS_Dist 1;
BA_ "GenSigSNA" SG_ 608 RR_PTS_Dist "FFh";
BA_ "GenSigSendType" SG_ 608 PTS_STAT_Front 5;
BA_ "GenSigCycleTime" SG_ 608 PTS_STAT_Front 500;
BA_ "FlexKomSigStartValue" SG_ 608 PTS_STAT_Front "FF80AAAAAAAA0AFFh";
BA_ "GenSigTimeout_CBC" SG_ 608 PTS_STAT_Front 5250;
BA_ "FlexKomSID" SG_ 608 PTS_STAT_Front 1954;
BA_ "FlexKomSigStartPos" SG_ 608 PTS_STAT_Front 7;
BA_ "FlexKomSigLaenge" SG_ 608 PTS_STAT_Front 64;
BA_ "FlexKomSigName" SG_ 608 PTS_STAT_Front "PTS_2_Pkt";
BA_ "FlexKomComment" SG_ 608 PTS_STAT_Front "PTS 2 message packet";
BA_ "FlexKomIsMotorola" SG_ 608 PTS_STAT_Front 1;
BA_ "GenSigSNA" SG_ 608 PTS_STAT_Front "3h";
BA_ "GenSigSendType" SG_ 608 RR_PTS_Brk_RqSts 5;
BA_ "GenSigCycleTime" SG_ 608 RR_PTS_Brk_RqSts 500;
BA_ "FlexKomSigStartValue" SG_ 608 RR_PTS_Brk_RqSts "FF80AAAAAAAA0AFFh";
BA_ "FlexKomSID" SG_ 608 RR_PTS_Brk_RqSts 1954;
BA_ "FlexKomSigStartPos" SG_ 608 RR_PTS_Brk_RqSts 7;
BA_ "FlexKomSigLaenge" SG_ 608 RR_PTS_Brk_RqSts 64;
BA_ "FlexKomSigName" SG_ 608 RR_PTS_Brk_RqSts "PTS_2_Pkt";
BA_ "FlexKomComment" SG_ 608 RR_PTS_Brk_RqSts "PTS 2 message packet";
BA_ "FlexKomIsMotorola" SG_ 608 RR_PTS_Brk_RqSts 1;
BA_ "GenSigSNA" SG_ 608 RR_PTS_Brk_RqSts "0h";
BA_ "GenSigSendType" SG_ 608 RR_PTS_StopControlSts 5;
BA_ "GenSigCycleTime" SG_ 608 RR_PTS_StopControlSts 500;
BA_ "FlexKomSigStartValue" SG_ 608 RR_PTS_StopControlSts "FF80AAAAAAAA0AFFh";
BA_ "FlexKomSID" SG_ 608 RR_PTS_StopControlSts 1954;
BA_ "FlexKomSigStartPos" SG_ 608 RR_PTS_StopControlSts 7;
BA_ "FlexKomSigLaenge" SG_ 608 RR_PTS_StopControlSts 64;
BA_ "FlexKomSigName" SG_ 608 RR_PTS_StopControlSts "PTS_2_Pkt";
BA_ "FlexKomComment" SG_ 608 RR_PTS_StopControlSts "PTS 2 message packet";
BA_ "FlexKomIsMotorola" SG_ 608 RR_PTS_StopControlSts 1;
BA_ "GenSigSNA" SG_ 608 RR_PTS_StopControlSts "0h";
BA_ "GenSigSendType" SG_ 608 PTS_FT_STATESts 5;
BA_ "GenSigCycleTime" SG_ 608 PTS_FT_STATESts 500;
BA_ "FlexKomSigStartValue" SG_ 608 PTS_FT_STATESts "FF80AAAAAAAA0AFFh";
BA_ "GenSigTimeout_IC" SG_ 608 PTS_FT_STATESts 5250;
BA_ "FlexKomSID" SG_ 608 PTS_FT_STATESts 1954;
BA_ "FlexKomSigStartPos" SG_ 608 PTS_FT_STATESts 7;
BA_ "FlexKomSigLaenge" SG_ 608 PTS_FT_STATESts 64;
BA_ "FlexKomSigName" SG_ 608 PTS_FT_STATESts "PTS_2_Pkt";
BA_ "FlexKomComment" SG_ 608 PTS_FT_STATESts "PTS 2 message packet";
BA_ "FlexKomIsMotorola" SG_ 608 PTS_FT_STATESts 1;
BA_ "GenSigSNA" SG_ 608 PTS_FT_STATESts "0h";
BA_ "GenSigSendType" SG_ 608 PTS_RR_STATESts 5;
BA_ "GenSigCycleTime" SG_ 608 PTS_RR_STATESts 500;
BA_ "FlexKomSigStartValue" SG_ 608 PTS_RR_STATESts "FF80AAAAAAAA0AFFh";
BA_ "GenSigTimeout_IC" SG_ 608 PTS_RR_STATESts 5250;
BA_ "FlexKomSID" SG_ 608 PTS_RR_STATESts 1954;
BA_ "FlexKomSigStartPos" SG_ 608 PTS_RR_STATESts 7;
BA_ "FlexKomSigLaenge" SG_ 608 PTS_RR_STATESts 64;
BA_ "FlexKomSigName" SG_ 608 PTS_RR_STATESts "PTS_2_Pkt";
BA_ "FlexKomComment" SG_ 608 PTS_RR_STATESts "PTS 2 message packet";
BA_ "FlexKomIsMotorola" SG_ 608 PTS_RR_STATESts 1;
BA_ "GenSigSNA" SG_ 608 PTS_RR_STATESts "0h";
BA_ "GenSigSendType" SG_ 608 PTS_ABOVE_SPEED 5;
BA_ "GenSigCycleTime" SG_ 608 PTS_ABOVE_SPEED 500;
BA_ "FlexKomSigStartValue" SG_ 608 PTS_ABOVE_SPEED "FF80AAAAAAAA0AFFh";
BA_ "GenSigTimeout_IC" SG_ 608 PTS_ABOVE_SPEED 5250;
BA_ "FlexKomSID" SG_ 608 PTS_ABOVE_SPEED 1954;
BA_ "FlexKomSigStartPos" SG_ 608 PTS_ABOVE_SPEED 7;
BA_ "FlexKomSigLaenge" SG_ 608 PTS_ABOVE_SPEED 64;
BA_ "FlexKomSigName" SG_ 608 PTS_ABOVE_SPEED "PTS_2_Pkt";
BA_ "FlexKomComment" SG_ 608 PTS_ABOVE_SPEED "PTS 2 message packet";
BA_ "FlexKomIsMotorola" SG_ 608 PTS_ABOVE_SPEED 1;
BA_ "GenSigSNA" SG_ 608 PTS_ABOVE_SPEED "0h";
BA_ "GenSigSendType" SG_ 608 MC_PTS_2 5;
BA_ "GenSigCycleTime" SG_ 608 MC_PTS_2 500;
BA_ "FlexKomSigStartValue" SG_ 608 MC_PTS_2 "FF80AAAAAAAA0AFFh";
BA_ "FlexKomSID" SG_ 608 MC_PTS_2 1954;
BA_ "FlexKomSigStartPos" SG_ 608 MC_PTS_2 7;
BA_ "FlexKomSigLaenge" SG_ 608 MC_PTS_2 64;
BA_ "FlexKomSigName" SG_ 608 MC_PTS_2 "PTS_2_Pkt";
BA_ "FlexKomComment" SG_ 608 MC_PTS_2 "PTS 2 message packet";
BA_ "FlexKomIsMotorola" SG_ 608 MC_PTS_2 1;
BA_ "GenSigSNA" SG_ 608 MC_PTS_2 "0h";
BA_ "GenSigSendType" SG_ 608 CRC_PTS_2 5;
BA_ "GenSigCycleTime" SG_ 608 CRC_PTS_2 500;
BA_ "FlexKomSigStartValue" SG_ 608 CRC_PTS_2 "FF80AAAAAAAA0AFFh";
BA_ "GenSigStartValue" SG_ 608 CRC_PTS_2 255;
BA_ "FlexKomSID" SG_ 608 CRC_PTS_2 1954;
BA_ "FlexKomSigStartPos" SG_ 608 CRC_PTS_2 7;
BA_ "FlexKomSigLaenge" SG_ 608 CRC_PTS_2 64;
BA_ "FlexKomSigName" SG_ 608 CRC_PTS_2 "PTS_2_Pkt";
BA_ "FlexKomComment" SG_ 608 CRC_PTS_2 "PTS 2 message packet";
BA_ "FlexKomIsMotorola" SG_ 608 CRC_PTS_2 1;
BA_ "GenSigSNA" SG_ 608 CRC_PTS_2 "FFh";
BA_ "GenSigSendType" SG_ 624 PrkLmpFault 5;
BA_ "GenSigCycleTime" SG_ 624 PrkLmpFault 1000;
BA_ "FlexKomSigStartValue" SG_ 624 PrkLmpFault "0000h";
BA_ "GenSigTimeout_IC" SG_ 624 PrkLmpFault 10500;
BA_ "FlexKomSID" SG_ 624 PrkLmpFault 1673;
BA_ "FlexKomSigStartPos" SG_ 624 PrkLmpFault 7;
BA_ "FlexKomSigLaenge" SG_ 624 PrkLmpFault 16;
BA_ "FlexKomSigName" SG_ 624 PrkLmpFault "CBC_FltPkt";
BA_ "FlexKomComment" SG_ 624 PrkLmpFault "CBC fault information packet";
BA_ "FlexKomIsMotorola" SG_ 624 PrkLmpFault 1;
BA_ "GenSigSNA" SG_ 624 PrkLmpFault "0h";
BA_ "GenSigSendType" SG_ 624 LowBeamFault 5;
BA_ "GenSigCycleTime" SG_ 624 LowBeamFault 1000;
BA_ "FlexKomSigStartValue" SG_ 624 LowBeamFault "0000h";
BA_ "GenSigTimeout_IC" SG_ 624 LowBeamFault 10500;
BA_ "FlexKomSID" SG_ 624 LowBeamFault 1673;
BA_ "FlexKomSigStartPos" SG_ 624 LowBeamFault 7;
BA_ "FlexKomSigLaenge" SG_ 624 LowBeamFault 16;
BA_ "FlexKomSigName" SG_ 624 LowBeamFault "CBC_FltPkt";
BA_ "FlexKomComment" SG_ 624 LowBeamFault "CBC fault information packet";
BA_ "FlexKomIsMotorola" SG_ 624 LowBeamFault 1;
BA_ "GenSigSNA" SG_ 624 LowBeamFault "0h";
BA_ "GenSigSendType" SG_ 624 HighBeamFault 5;
BA_ "GenSigCycleTime" SG_ 624 HighBeamFault 1000;
BA_ "FlexKomSigStartValue" SG_ 624 HighBeamFault "0000h";
BA_ "GenSigTimeout_IC" SG_ 624 HighBeamFault 10500;
BA_ "FlexKomSID" SG_ 624 HighBeamFault 1673;
BA_ "FlexKomSigStartPos" SG_ 624 HighBeamFault 7;
BA_ "FlexKomSigLaenge" SG_ 624 HighBeamFault 16;
BA_ "FlexKomSigName" SG_ 624 HighBeamFault "CBC_FltPkt";
BA_ "FlexKomComment" SG_ 624 HighBeamFault "CBC fault information packet";
BA_ "FlexKomIsMotorola" SG_ 624 HighBeamFault 1;
BA_ "GenSigSNA" SG_ 624 HighBeamFault "0h";
BA_ "GenSigSendType" SG_ 624 DRLFault 5;
BA_ "GenSigCycleTime" SG_ 624 DRLFault 1000;
BA_ "FlexKomSigStartValue" SG_ 624 DRLFault "0000h";
BA_ "GenSigTimeout_IC" SG_ 624 DRLFault 10500;
BA_ "FlexKomSID" SG_ 624 DRLFault 1673;
BA_ "FlexKomSigStartPos" SG_ 624 DRLFault 7;
BA_ "FlexKomSigLaenge" SG_ 624 DRLFault 16;
BA_ "FlexKomSigName" SG_ 624 DRLFault "CBC_FltPkt";
BA_ "FlexKomComment" SG_ 624 DRLFault "CBC fault information packet";
BA_ "FlexKomIsMotorola" SG_ 624 DRLFault 1;
BA_ "GenSigSNA" SG_ 624 DRLFault "0h";
BA_ "GenSigSendType" SG_ 624 FtFogLmpFault 5;
BA_ "GenSigCycleTime" SG_ 624 FtFogLmpFault 1000;
BA_ "FlexKomSigStartValue" SG_ 624 FtFogLmpFault "0000h";
BA_ "GenSigTimeout_IC" SG_ 624 FtFogLmpFault 10500;
BA_ "FlexKomSID" SG_ 624 FtFogLmpFault 1673;
BA_ "FlexKomSigStartPos" SG_ 624 FtFogLmpFault 7;
BA_ "FlexKomSigLaenge" SG_ 624 FtFogLmpFault 16;
BA_ "FlexKomSigName" SG_ 624 FtFogLmpFault "CBC_FltPkt";
BA_ "FlexKomComment" SG_ 624 FtFogLmpFault "CBC fault information packet";
BA_ "FlexKomIsMotorola" SG_ 624 FtFogLmpFault 1;
BA_ "GenSigSNA" SG_ 624 FtFogLmpFault "0h";
BA_ "GenSigSendType" SG_ 624 RearFogLmpFault 5;
BA_ "GenSigCycleTime" SG_ 624 RearFogLmpFault 1000;
BA_ "FlexKomSigStartValue" SG_ 624 RearFogLmpFault "0000h";
BA_ "GenSigTimeout_IC" SG_ 624 RearFogLmpFault 10500;
BA_ "FlexKomSID" SG_ 624 RearFogLmpFault 1673;
BA_ "FlexKomSigStartPos" SG_ 624 RearFogLmpFault 7;
BA_ "FlexKomSigLaenge" SG_ 624 RearFogLmpFault 16;
BA_ "FlexKomSigName" SG_ 624 RearFogLmpFault "CBC_FltPkt";
BA_ "FlexKomComment" SG_ 624 RearFogLmpFault "CBC fault information packet";
BA_ "FlexKomIsMotorola" SG_ 624 RearFogLmpFault 1;
BA_ "GenSigSNA" SG_ 624 RearFogLmpFault "0h";
BA_ "GenSigSendType" SG_ 624 SpLmpFault 5;
BA_ "GenSigCycleTime" SG_ 624 SpLmpFault 1000;
BA_ "FlexKomSigStartValue" SG_ 624 SpLmpFault "0000h";
BA_ "GenSigTimeout_IC" SG_ 624 SpLmpFault 10500;
BA_ "FlexKomSID" SG_ 624 SpLmpFault 1673;
BA_ "FlexKomSigStartPos" SG_ 624 SpLmpFault 7;
BA_ "FlexKomSigLaenge" SG_ 624 SpLmpFault 16;
BA_ "FlexKomSigName" SG_ 624 SpLmpFault "CBC_FltPkt";
BA_ "FlexKomComment" SG_ 624 SpLmpFault "CBC fault information packet";
BA_ "FlexKomIsMotorola" SG_ 624 SpLmpFault 1;
BA_ "GenSigSNA" SG_ 624 SpLmpFault "0h";
BA_ "GenSigSendType" SG_ 624 RevLmpFault 5;
BA_ "GenSigCycleTime" SG_ 624 RevLmpFault 1000;
BA_ "FlexKomSigStartValue" SG_ 624 RevLmpFault "0000h";
BA_ "GenSigTimeout_IC" SG_ 624 RevLmpFault 10500;
BA_ "FlexKomSID" SG_ 624 RevLmpFault 1673;
BA_ "FlexKomSigStartPos" SG_ 624 RevLmpFault 7;
BA_ "FlexKomSigLaenge" SG_ 624 RevLmpFault 16;
BA_ "FlexKomSigName" SG_ 624 RevLmpFault "CBC_FltPkt";
BA_ "FlexKomComment" SG_ 624 RevLmpFault "CBC fault information packet";
BA_ "FlexKomIsMotorola" SG_ 624 RevLmpFault 1;
BA_ "GenSigSNA" SG_ 624 RevLmpFault "0h";
BA_ "GenSigSendType" SG_ 624 PlateLmpFault 5;
BA_ "GenSigCycleTime" SG_ 624 PlateLmpFault 1000;
BA_ "FlexKomSigStartValue" SG_ 624 PlateLmpFault "0000h";
BA_ "GenSigTimeout_IC" SG_ 624 PlateLmpFault 10500;
BA_ "FlexKomSID" SG_ 624 PlateLmpFault 1673;
BA_ "FlexKomSigStartPos" SG_ 624 PlateLmpFault 7;
BA_ "FlexKomSigLaenge" SG_ 624 PlateLmpFault 16;
BA_ "FlexKomSigName" SG_ 624 PlateLmpFault "CBC_FltPkt";
BA_ "FlexKomComment" SG_ 624 PlateLmpFault "CBC fault information packet";
BA_ "FlexKomIsMotorola" SG_ 624 PlateLmpFault 1;
BA_ "GenSigSNA" SG_ 624 PlateLmpFault "0h";
BA_ "GenSigSendType" SG_ 624 TrlrSpTurnFault 5;
BA_ "GenSigCycleTime" SG_ 624 TrlrSpTurnFault 1000;
BA_ "FlexKomSigStartValue" SG_ 624 TrlrSpTurnFault "0000h";
BA_ "GenSigTimeout_IC" SG_ 624 TrlrSpTurnFault 10500;
BA_ "FlexKomSID" SG_ 624 TrlrSpTurnFault 1673;
BA_ "FlexKomSigStartPos" SG_ 624 TrlrSpTurnFault 7;
BA_ "FlexKomSigLaenge" SG_ 624 TrlrSpTurnFault 16;
BA_ "FlexKomSigName" SG_ 624 TrlrSpTurnFault "CBC_FltPkt";
BA_ "FlexKomComment" SG_ 624 TrlrSpTurnFault "CBC fault information packet";
BA_ "FlexKomIsMotorola" SG_ 624 TrlrSpTurnFault 1;
BA_ "GenSigSNA" SG_ 624 TrlrSpTurnFault "0h";
BA_ "GenSigSendType" SG_ 624 TrlrPrkFault 5;
BA_ "GenSigCycleTime" SG_ 624 TrlrPrkFault 1000;
BA_ "FlexKomSigStartValue" SG_ 624 TrlrPrkFault "0000h";
BA_ "GenSigTimeout_IC" SG_ 624 TrlrPrkFault 10500;
BA_ "FlexKomSID" SG_ 624 TrlrPrkFault 1673;
BA_ "FlexKomSigStartPos" SG_ 624 TrlrPrkFault 7;
BA_ "FlexKomSigLaenge" SG_ 624 TrlrPrkFault 16;
BA_ "FlexKomSigName" SG_ 624 TrlrPrkFault "CBC_FltPkt";
BA_ "FlexKomComment" SG_ 624 TrlrPrkFault "CBC fault information packet";
BA_ "FlexKomIsMotorola" SG_ 624 TrlrPrkFault 1;
BA_ "GenSigSNA" SG_ 624 TrlrPrkFault "0h";
BA_ "GenSigSendType" SG_ 624 HlSwFault 5;
BA_ "GenSigCycleTime" SG_ 624 HlSwFault 1000;
BA_ "FlexKomSigStartValue" SG_ 624 HlSwFault "0000h";
BA_ "GenSigTimeout_IC" SG_ 624 HlSwFault 10500;
BA_ "FlexKomSID" SG_ 624 HlSwFault 1673;
BA_ "FlexKomSigStartPos" SG_ 624 HlSwFault 7;
BA_ "FlexKomSigLaenge" SG_ 624 HlSwFault 16;
BA_ "FlexKomSigName" SG_ 624 HlSwFault "CBC_FltPkt";
BA_ "FlexKomComment" SG_ 624 HlSwFault "CBC fault information packet";
BA_ "FlexKomIsMotorola" SG_ 624 HlSwFault 1;
BA_ "GenSigSNA" SG_ 624 HlSwFault "0h";
BA_ "GenSigSendType" SG_ 624 AmbLgtSnsrFault 5;
BA_ "GenSigCycleTime" SG_ 624 AmbLgtSnsrFault 1000;
BA_ "FlexKomSigStartValue" SG_ 624 AmbLgtSnsrFault "0000h";
BA_ "GenSigTimeout_IC" SG_ 624 AmbLgtSnsrFault 10500;
BA_ "FlexKomSID" SG_ 624 AmbLgtSnsrFault 1673;
BA_ "FlexKomSigStartPos" SG_ 624 AmbLgtSnsrFault 7;
BA_ "FlexKomSigLaenge" SG_ 624 AmbLgtSnsrFault 16;
BA_ "FlexKomSigName" SG_ 624 AmbLgtSnsrFault "CBC_FltPkt";
BA_ "FlexKomComment" SG_ 624 AmbLgtSnsrFault "CBC fault information packet";
BA_ "FlexKomIsMotorola" SG_ 624 AmbLgtSnsrFault 1;
BA_ "GenSigSNA" SG_ 624 AmbLgtSnsrFault "0h";
BA_ "GenSigSendType" SG_ 624 AHB_Fault 5;
BA_ "GenSigCycleTime" SG_ 624 AHB_Fault 1000;
BA_ "FlexKomSigStartValue" SG_ 624 AHB_Fault "0000h";
BA_ "GenSigTimeout_IC" SG_ 624 AHB_Fault 10500;
BA_ "FlexKomSID" SG_ 624 AHB_Fault 1673;
BA_ "FlexKomSigStartPos" SG_ 624 AHB_Fault 7;
BA_ "FlexKomSigLaenge" SG_ 624 AHB_Fault 16;
BA_ "FlexKomSigName" SG_ 624 AHB_Fault "CBC_FltPkt";
BA_ "FlexKomComment" SG_ 624 AHB_Fault "CBC fault information packet";
BA_ "FlexKomIsMotorola" SG_ 624 AHB_Fault 1;
BA_ "GenSigSNA" SG_ 624 AHB_Fault "0h";
BA_ "GenSigSendType" SG_ 624 LgtSensFlt 5;
BA_ "GenSigCycleTime" SG_ 624 LgtSensFlt 1000;
BA_ "FlexKomSigStartValue" SG_ 624 LgtSensFlt "0000h";
BA_ "GenSigTimeout_IC" SG_ 624 LgtSensFlt 10500;
BA_ "FlexKomSID" SG_ 624 LgtSensFlt 1673;
BA_ "FlexKomSigStartPos" SG_ 624 LgtSensFlt 7;
BA_ "FlexKomSigLaenge" SG_ 624 LgtSensFlt 16;
BA_ "FlexKomSigName" SG_ 624 LgtSensFlt "CBC_FltPkt";
BA_ "FlexKomComment" SG_ 624 LgtSensFlt "CBC fault information packet";
BA_ "FlexKomIsMotorola" SG_ 624 LgtSensFlt 1;
BA_ "GenSigSNA" SG_ 624 LgtSensFlt "0h";
BA_ "GenSigSendType" SG_ 624 FuelTxfrSts 5;
BA_ "GenSigCycleTime" SG_ 624 FuelTxfrSts 1000;
BA_ "FlexKomSigStartValue" SG_ 624 FuelTxfrSts "00h";
BA_ "FlexKomSID" SG_ 624 FuelTxfrSts 2041;
BA_ "FlexKomSigStartPos" SG_ 624 FuelTxfrSts 43;
BA_ "FlexKomSigLaenge" SG_ 624 FuelTxfrSts 2;
BA_ "FlexKomSigName" SG_ 624 FuelTxfrSts "FuelTxfrSts";
BA_ "FlexKomComment" SG_ 624 FuelTxfrSts "Fuel transfer relay status";
BA_ "FlexKomIsMotorola" SG_ 624 FuelTxfrSts 1;
BA_ "GenSigSNA" SG_ 624 FuelTxfrSts "3h";
BA_ "GenSigSendType" SG_ 624 SecurePkSts 5;
BA_ "GenSigCycleTime" SG_ 624 SecurePkSts 1000;
BA_ "FlexKomSigStartValue" SG_ 624 SecurePkSts "00h";
BA_ "GenSigTimeout_IC" SG_ 624 SecurePkSts 10500;
BA_ "FlexKomSID" SG_ 624 SecurePkSts 1997;
BA_ "FlexKomSigStartPos" SG_ 624 SecurePkSts 46;
BA_ "FlexKomSigLaenge" SG_ 624 SecurePkSts 3;
BA_ "FlexKomSigName" SG_ 624 SecurePkSts "SecurePkSts";
BA_ "FlexKomComment" SG_ 624 SecurePkSts "Secure park status";
BA_ "FlexKomIsMotorola" SG_ 624 SecurePkSts 1;
BA_ "GenSigSNA" SG_ 624 SecurePkSts "7h";
BA_ "GenSigSendType" SG_ 624 HAZARD_STATUS 5;
BA_ "GenSigCycleTime" SG_ 624 HAZARD_STATUS 1000;
BA_ "FlexKomSigStartValue" SG_ 624 HAZARD_STATUS "00h";
BA_ "FlexKomSID" SG_ 624 HAZARD_STATUS 1958;
BA_ "FlexKomSigStartPos" SG_ 624 HAZARD_STATUS 47;
BA_ "FlexKomSigLaenge" SG_ 624 HAZARD_STATUS 1;
BA_ "FlexKomSigName" SG_ 624 HAZARD_STATUS "HAZARD_STATUS";
BA_ "FlexKomComment" SG_ 624 HAZARD_STATUS "Hazard lamps; active = [1]";
BA_ "FlexKomIsMotorola" SG_ 624 HAZARD_STATUS 1;
BA_ "GenSigSNA" SG_ 624 HAZARD_STATUS "0h";
BA_ "GenSigCycleTime" SG_ 624 EngineOffTimer 1000;
BA_ "FlexKomSigStartValue" SG_ 624 EngineOffTimer "0FFFh";
BA_ "GenSigStartValue" SG_ 624 EngineOffTimer 4095;
BA_ "FlexKomSID" SG_ 624 EngineOffTimer 1906;
BA_ "FlexKomSigStartPos" SG_ 624 EngineOffTimer 55;
BA_ "FlexKomSigLaenge" SG_ 624 EngineOffTimer 16;
BA_ "FlexKomSigName" SG_ 624 EngineOffTimer "EngineOffTimer";
BA_ "FlexKomComment" SG_ 624 EngineOffTimer "Engine off timer - engine off ignition NOT lock.";
BA_ "FlexKomIsMotorola" SG_ 624 EngineOffTimer 1;
BA_ "GenSigSNA" SG_ 624 EngineOffTimer "FFFh";
BA_ "GenSigSendType" SG_ 624 HL_Stat 5;
BA_ "GenSigCycleTime" SG_ 624 HL_Stat 1000;
BA_ "FlexKomSigStartValue" SG_ 624 HL_Stat "00h";
BA_ "FlexKomSID" SG_ 624 HL_Stat 1760;
BA_ "FlexKomSigStartPos" SG_ 624 HL_Stat 54;
BA_ "FlexKomSigLaenge" SG_ 624 HL_Stat 2;
BA_ "FlexKomSigName" SG_ 624 HL_Stat "HL_Stat";
BA_ "FlexKomComment" SG_ 624 HL_Stat "Headlamp status";
BA_ "FlexKomIsMotorola" SG_ 624 HL_Stat 1;
BA_ "GenSigSNA" SG_ 624 HL_Stat "0h";
BA_ "GenSigSendType" SG_ 624 PNC_ALM_ACT 5;
BA_ "GenSigCycleTime" SG_ 624 PNC_ALM_ACT 1000;
BA_ "FlexKomSigStartValue" SG_ 624 PNC_ALM_ACT "00h";
BA_ "FlexKomSID" SG_ 624 PNC_ALM_ACT 756;
BA_ "FlexKomSigStartPos" SG_ 624 PNC_ALM_ACT 55;
BA_ "FlexKomSigLaenge" SG_ 624 PNC_ALM_ACT 1;
BA_ "FlexKomSigName" SG_ 624 PNC_ALM_ACT "PNC_ALM_ACT";
BA_ "FlexKomComment" SG_ 624 PNC_ALM_ACT "Panic alarm active; [1] = True";
BA_ "FlexKomIsMotorola" SG_ 624 PNC_ALM_ACT 1;
BA_ "GenSigSNA" SG_ 624 PNC_ALM_ACT "0h";
BA_ "GenSigCycleTime" SG_ 632 CC_SetSpdDspl 100;
BA_ "FlexKomSigStartValue" SG_ 632 CC_SetSpdDspl "FFh";
BA_ "GenSigStartValue" SG_ 632 CC_SetSpdDspl 255;
BA_ "GenSigTimeout_IC" SG_ 632 CC_SetSpdDspl 1050;
BA_ "FlexKomSID" SG_ 632 CC_SetSpdDspl 1361;
BA_ "FlexKomSigStartPos" SG_ 632 CC_SetSpdDspl 7;
BA_ "FlexKomSigLaenge" SG_ 632 CC_SetSpdDspl 8;
BA_ "FlexKomSigName" SG_ 632 CC_SetSpdDspl "CC_SetSpdDspl";
BA_ "FlexKomComment" SG_ 632 CC_SetSpdDspl "Cruise control set speed for display (kmph only)";
BA_ "FlexKomIsMotorola" SG_ 632 CC_SetSpdDspl 1;
BA_ "GenSigSNA" SG_ 632 CC_SetSpdDspl "FFh";
BA_ "GenSigCycleTime" SG_ 632 EngDrvMdStat 100;
BA_ "FlexKomSigStartValue" SG_ 632 EngDrvMdStat "00h";
BA_ "GenSigTimeout_CBC" SG_ 632 EngDrvMdStat 1050;
BA_ "FlexKomSID" SG_ 632 EngDrvMdStat 1763;
BA_ "FlexKomSigStartPos" SG_ 632 EngDrvMdStat 10;
BA_ "FlexKomSigLaenge" SG_ 632 EngDrvMdStat 3;
BA_ "FlexKomSigName" SG_ 632 EngDrvMdStat "EngDrvMdStat";
BA_ "FlexKomComment" SG_ 632 EngDrvMdStat "Engine driving mode status";
BA_ "FlexKomIsMotorola" SG_ 632 EngDrvMdStat 1;
BA_ "GenSigSNA" SG_ 632 EngDrvMdStat "7h";
BA_ "GenSigCycleTime" SG_ 632 IdleShutDwnApply 100;
BA_ "FlexKomSigStartValue" SG_ 632 IdleShutDwnApply "00h";
BA_ "GenSigTimeout_IC" SG_ 632 IdleShutDwnApply 1050;
BA_ "FlexKomSID" SG_ 632 IdleShutDwnApply 1983;
BA_ "FlexKomSigStartPos" SG_ 632 IdleShutDwnApply 11;
BA_ "FlexKomSigLaenge" SG_ 632 IdleShutDwnApply 1;
BA_ "FlexKomSigName" SG_ 632 IdleShutDwnApply "IdleShutDwnApply";
BA_ "FlexKomComment" SG_ 632 IdleShutDwnApply "Idle Shut down applied; 1 = True";
BA_ "FlexKomIsMotorola" SG_ 632 IdleShutDwnApply 1;
BA_ "GenSigSNA" SG_ 632 IdleShutDwnApply "0h";
BA_ "GenSigCycleTime" SG_ 632 EVPmpStat 100;
BA_ "FlexKomSigStartValue" SG_ 632 EVPmpStat "00h";
BA_ "FlexKomSID" SG_ 632 EVPmpStat 1418;
BA_ "FlexKomSigStartPos" SG_ 632 EVPmpStat 13;
BA_ "FlexKomSigLaenge" SG_ 632 EVPmpStat 2;
BA_ "FlexKomSigName" SG_ 632 EVPmpStat "EVPmpStat";
BA_ "FlexKomComment" SG_ 632 EVPmpStat "Electric vacuum pump status";
BA_ "FlexKomIsMotorola" SG_ 632 EVPmpStat 1;
BA_ "GenSigSNA" SG_ 632 EVPmpStat "3h";
BA_ "GenSigCycleTime" SG_ 632 EconShftRq 100;
BA_ "FlexKomSigStartValue" SG_ 632 EconShftRq "00h";
BA_ "GenSigTimeout_IC" SG_ 632 EconShftRq 1050;
BA_ "FlexKomSID" SG_ 632 EconShftRq 1642;
BA_ "FlexKomSigStartPos" SG_ 632 EconShftRq 15;
BA_ "FlexKomSigLaenge" SG_ 632 EconShftRq 2;
BA_ "FlexKomSigName" SG_ 632 EconShftRq "EconShftRq";
BA_ "FlexKomComment" SG_ 632 EconShftRq "Economy transmission shift request";
BA_ "FlexKomIsMotorola" SG_ 632 EconShftRq 1;
BA_ "GenSigSNA" SG_ 632 EconShftRq "3h";
BA_ "GenSigCycleTime" SG_ 632 CoolVlvPos 100;
BA_ "FlexKomSigStartValue" SG_ 632 CoolVlvPos "FFh";
BA_ "GenSigStartValue" SG_ 632 CoolVlvPos 255;
BA_ "GenSigTimeout_CBC" SG_ 632 CoolVlvPos 1050;
BA_ "FlexKomSID" SG_ 632 CoolVlvPos 1446;
BA_ "FlexKomSigStartPos" SG_ 632 CoolVlvPos 23;
BA_ "FlexKomSigLaenge" SG_ 632 CoolVlvPos 8;
BA_ "FlexKomSigName" SG_ 632 CoolVlvPos "CoolVlvPos";
BA_ "FlexKomComment" SG_ 632 CoolVlvPos "Coolant (3-way) valve position";
BA_ "FlexKomIsMotorola" SG_ 632 CoolVlvPos 1;
BA_ "GenSigSNA" SG_ 632 CoolVlvPos "FFh";
BA_ "GenSigCycleTime" SG_ 632 VehMassCalc 100;
BA_ "FlexKomSigStartValue" SG_ 632 VehMassCalc "FF00h";
BA_ "GenSigStartValue" SG_ 632 VehMassCalc 255;
BA_ "FlexKomSID" SG_ 632 VehMassCalc 1524;
BA_ "FlexKomSigStartPos" SG_ 632 VehMassCalc 31;
BA_ "FlexKomSigLaenge" SG_ 632 VehMassCalc 16;
BA_ "FlexKomSigName" SG_ 632 VehMassCalc "VehMassPkt";
BA_ "FlexKomComment" SG_ 632 VehMassCalc "Vehicle mass calculation packet";
BA_ "FlexKomIsMotorola" SG_ 632 VehMassCalc 1;
BA_ "GenSigSNA" SG_ 632 VehMassCalc "FFh";
BA_ "GenSigCycleTime" SG_ 632 VehMassCnfd 100;
BA_ "FlexKomSigStartValue" SG_ 632 VehMassCnfd "FF00h";
BA_ "FlexKomSID" SG_ 632 VehMassCnfd 1524;
BA_ "FlexKomSigStartPos" SG_ 632 VehMassCnfd 31;
BA_ "FlexKomSigLaenge" SG_ 632 VehMassCnfd 16;
BA_ "FlexKomSigName" SG_ 632 VehMassCnfd "VehMassPkt";
BA_ "FlexKomComment" SG_ 632 VehMassCnfd "Vehicle mass calculation packet";
BA_ "FlexKomIsMotorola" SG_ 632 VehMassCnfd 1;
BA_ "GenSigSNA" SG_ 632 VehMassCnfd "7h";
BA_ "GenSigCycleTime" SG_ 632 EnblFuelTxfr 100;
BA_ "FlexKomSigStartValue" SG_ 632 EnblFuelTxfr "00h";
BA_ "FlexKomSID" SG_ 632 EnblFuelTxfr 2040;
BA_ "FlexKomSigStartPos" SG_ 632 EnblFuelTxfr 35;
BA_ "FlexKomSigLaenge" SG_ 632 EnblFuelTxfr 1;
BA_ "FlexKomSigName" SG_ 632 EnblFuelTxfr "EnblFuelTxfr";
BA_ "FlexKomComment" SG_ 632 EnblFuelTxfr "Enable fuel transfer; True = [1]";
BA_ "FlexKomIsMotorola" SG_ 632 EnblFuelTxfr 1;
BA_ "GenSigSNA" SG_ 632 EnblFuelTxfr "0h";
BA_ "GenSigCycleTime" SG_ 632 PerfShftRq 100;
BA_ "FlexKomSigStartValue" SG_ 632 PerfShftRq "00h";
BA_ "GenSigTimeout_IC" SG_ 632 PerfShftRq 1050;
BA_ "FlexKomSID" SG_ 632 PerfShftRq 1984;
BA_ "FlexKomSigStartPos" SG_ 632 PerfShftRq 37;
BA_ "FlexKomSigLaenge" SG_ 632 PerfShftRq 2;
BA_ "FlexKomSigName" SG_ 632 PerfShftRq "PerfShftRq";
BA_ "FlexKomComment" SG_ 632 PerfShftRq "Performance transmission shift request";
BA_ "FlexKomIsMotorola" SG_ 632 PerfShftRq 1;
BA_ "GenSigSNA" SG_ 632 PerfShftRq "3h";
BA_ "GenSigCycleTime" SG_ 632 CC_SetSpdDsplMPH 100;
BA_ "FlexKomSigStartValue" SG_ 632 CC_SetSpdDsplMPH "FFh";
BA_ "GenSigStartValue" SG_ 632 CC_SetSpdDsplMPH 255;
BA_ "GenSigTimeout_IC" SG_ 632 CC_SetSpdDsplMPH 1050;
BA_ "FlexKomSID" SG_ 632 CC_SetSpdDsplMPH 1610;
BA_ "FlexKomSigStartPos" SG_ 632 CC_SetSpdDsplMPH 47;
BA_ "FlexKomSigLaenge" SG_ 632 CC_SetSpdDsplMPH 8;
BA_ "FlexKomSigName" SG_ 632 CC_SetSpdDsplMPH "CC_SetSpdDsplMPH";
BA_ "FlexKomComment" SG_ 632 CC_SetSpdDsplMPH "Cruise control set speed for display in miles per ";
BA_ "FlexKomIsMotorola" SG_ 632 CC_SetSpdDsplMPH 1;
BA_ "GenSigSNA" SG_ 632 CC_SetSpdDsplMPH "FFh";
BA_ "GenSigCycleTime" SG_ 632 SpStSwStat 100;
BA_ "FlexKomSigStartValue" SG_ 632 SpStSwStat "0000h";
BA_ "GenSigTimeout_CBC" SG_ 632 SpStSwStat 1050;
BA_ "GenSigTimeout_IC" SG_ 632 SpStSwStat 1050;
BA_ "GenSigTimeout_ORC" SG_ 632 SpStSwStat 350;
BA_ "FlexKomSID" SG_ 632 SpStSwStat 1567;
BA_ "FlexKomSigStartPos" SG_ 632 SpStSwStat 55;
BA_ "FlexKomSigLaenge" SG_ 632 SpStSwStat 16;
BA_ "FlexKomSigName" SG_ 632 SpStSwStat "SpStPacket";
BA_ "FlexKomComment" SG_ 632 SpStSwStat "Stop start packet";
BA_ "FlexKomIsMotorola" SG_ 632 SpStSwStat 1;
BA_ "GenSigSNA" SG_ 632 SpStSwStat "3h";
BA_ "GenSigCycleTime" SG_ 632 SpStTachMd 100;
BA_ "FlexKomSigStartValue" SG_ 632 SpStTachMd "0000h";
BA_ "GenSigTimeout_CBC" SG_ 632 SpStTachMd 1050;
BA_ "GenSigTimeout_IC" SG_ 632 SpStTachMd 1050;
BA_ "FlexKomSID" SG_ 632 SpStTachMd 1567;
BA_ "FlexKomSigStartPos" SG_ 632 SpStTachMd 55;
BA_ "FlexKomSigLaenge" SG_ 632 SpStTachMd 16;
BA_ "FlexKomSigName" SG_ 632 SpStTachMd "SpStPacket";
BA_ "FlexKomComment" SG_ 632 SpStTachMd "Stop start packet";
BA_ "FlexKomIsMotorola" SG_ 632 SpStTachMd 1;
BA_ "GenSigSNA" SG_ 632 SpStTachMd "3h";
BA_ "GenSigCycleTime" SG_ 632 SpStWarnStat 100;
BA_ "FlexKomSigStartValue" SG_ 632 SpStWarnStat "0000h";
BA_ "GenSigTimeout_IC" SG_ 632 SpStWarnStat 1050;
BA_ "GenSigTimeout_ORC" SG_ 632 SpStWarnStat 350;
BA_ "FlexKomSID" SG_ 632 SpStWarnStat 1567;
BA_ "FlexKomSigStartPos" SG_ 632 SpStWarnStat 55;
BA_ "FlexKomSigLaenge" SG_ 632 SpStWarnStat 16;
BA_ "FlexKomSigName" SG_ 632 SpStWarnStat "SpStPacket";
BA_ "FlexKomComment" SG_ 632 SpStWarnStat "Stop start packet";
BA_ "FlexKomIsMotorola" SG_ 632 SpStWarnStat 1;
BA_ "GenSigSNA" SG_ 632 SpStWarnStat "Fh";
BA_ "GenSigCycleTime" SG_ 632 SpStDispstat 100;
BA_ "FlexKomSigStartValue" SG_ 632 SpStDispstat "0000h";
BA_ "GenSigTimeout_IC" SG_ 632 SpStDispstat 1050;
BA_ "GenSigTimeout_ORC" SG_ 632 SpStDispstat 350;
BA_ "FlexKomSID" SG_ 632 SpStDispstat 1567;
BA_ "FlexKomSigStartPos" SG_ 632 SpStDispstat 55;
BA_ "FlexKomSigLaenge" SG_ 632 SpStDispstat 16;
BA_ "FlexKomSigName" SG_ 632 SpStDispstat "SpStPacket";
BA_ "FlexKomComment" SG_ 632 SpStDispstat "Stop start packet";
BA_ "FlexKomIsMotorola" SG_ 632 SpStDispstat 1;
BA_ "GenSigSNA" SG_ 632 SpStDispstat "3Fh";
BA_ "GenSigCycleTime" SG_ 632 SpStIndRq 100;
BA_ "FlexKomSigStartValue" SG_ 632 SpStIndRq "0000h";
BA_ "FlexKomSID" SG_ 632 SpStIndRq 1567;
BA_ "FlexKomSigStartPos" SG_ 632 SpStIndRq 55;
BA_ "FlexKomSigLaenge" SG_ 632 SpStIndRq 16;
BA_ "FlexKomSigName" SG_ 632 SpStIndRq "SpStPacket";
BA_ "FlexKomComment" SG_ 632 SpStIndRq "Stop start packet";
BA_ "FlexKomIsMotorola" SG_ 632 SpStIndRq 1;
BA_ "GenSigSNA" SG_ 632 SpStIndRq "0h";
BA_ "GenSigCycleTime" SG_ 632 SpStChmRq 100;
BA_ "FlexKomSigStartValue" SG_ 632 SpStChmRq "0000h";
BA_ "FlexKomSID" SG_ 632 SpStChmRq 1567;
BA_ "FlexKomSigStartPos" SG_ 632 SpStChmRq 55;
BA_ "FlexKomSigLaenge" SG_ 632 SpStChmRq 16;
BA_ "FlexKomSigName" SG_ 632 SpStChmRq "SpStPacket";
BA_ "FlexKomComment" SG_ 632 SpStChmRq "Stop start packet";
BA_ "FlexKomIsMotorola" SG_ 632 SpStChmRq 1;
BA_ "GenSigSNA" SG_ 632 SpStChmRq "0h";
BA_ "GenSigCycleTime" SG_ 639 IBS_Q_received 1000;
BA_ "FlexKomSigStartValue" SG_ 639 IBS_Q_received "FFFFFFFF00000000h";
BA_ "GenSigStartValue" SG_ 639 IBS_Q_received 65535;
BA_ "FlexKomSID" SG_ 639 IBS_Q_received 1855;
BA_ "FlexKomSigStartPos" SG_ 639 IBS_Q_received 7;
BA_ "FlexKomSigLaenge" SG_ 639 IBS_Q_received 64;
BA_ "FlexKomSigName" SG_ 639 IBS_Q_received "GW_IBS_DataPkt";
BA_ "FlexKomComment" SG_ 639 IBS_Q_received "LIN to CAN C IBS data";
BA_ "FlexKomIsMotorola" SG_ 639 IBS_Q_received 1;
BA_ "GenSigSNA" SG_ 639 IBS_Q_received "FFFFh";
BA_ "GenSigCycleTime" SG_ 639 IBS_Q_released 1000;
BA_ "FlexKomSigStartValue" SG_ 639 IBS_Q_released "FFFFFFFF00000000h";
BA_ "GenSigStartValue" SG_ 639 IBS_Q_released 65535;
BA_ "FlexKomSID" SG_ 639 IBS_Q_released 1855;
BA_ "FlexKomSigStartPos" SG_ 639 IBS_Q_released 7;
BA_ "FlexKomSigLaenge" SG_ 639 IBS_Q_released 64;
BA_ "FlexKomSigName" SG_ 639 IBS_Q_released "GW_IBS_DataPkt";
BA_ "FlexKomComment" SG_ 639 IBS_Q_released "LIN to CAN C IBS data";
BA_ "FlexKomIsMotorola" SG_ 639 IBS_Q_released 1;
BA_ "GenSigSNA" SG_ 639 IBS_Q_released "FFFFh";
BA_ "GenSigCycleTime" SG_ 639 IBS_Tm_Lst_Reset_Sec 1000;
BA_ "FlexKomSigStartValue" SG_ 639 IBS_Tm_Lst_Reset_Sec "FFFFFFFF00000000h";
BA_ "FlexKomSID" SG_ 639 IBS_Tm_Lst_Reset_Sec 1855;
BA_ "FlexKomSigStartPos" SG_ 639 IBS_Tm_Lst_Reset_Sec 7;
BA_ "FlexKomSigLaenge" SG_ 639 IBS_Tm_Lst_Reset_Sec 64;
BA_ "FlexKomSigName" SG_ 639 IBS_Tm_Lst_Reset_Sec "GW_IBS_DataPkt";
BA_ "FlexKomComment" SG_ 639 IBS_Tm_Lst_Reset_Sec "LIN to CAN C IBS data";
BA_ "FlexKomIsMotorola" SG_ 639 IBS_Tm_Lst_Reset_Sec 1;
BA_ "GenSigSNA" SG_ 639 IBS_Tm_Lst_Reset_Sec "FFFFh";
BA_ "GenSigCycleTime" SG_ 639 IBS_Tm_Lst_Reset_Days 1000;
BA_ "FlexKomSigStartValue" SG_ 639 IBS_Tm_Lst_Reset_Days "FFFFFFFF00000000h";
BA_ "FlexKomSID" SG_ 639 IBS_Tm_Lst_Reset_Days 1855;
BA_ "FlexKomSigStartPos" SG_ 639 IBS_Tm_Lst_Reset_Days 7;
BA_ "FlexKomSigLaenge" SG_ 639 IBS_Tm_Lst_Reset_Days 64;
BA_ "FlexKomSigName" SG_ 639 IBS_Tm_Lst_Reset_Days "GW_IBS_DataPkt";
BA_ "FlexKomComment" SG_ 639 IBS_Tm_Lst_Reset_Days "LIN to CAN C IBS data";
BA_ "FlexKomIsMotorola" SG_ 639 IBS_Tm_Lst_Reset_Days 1;
BA_ "GenSigSNA" SG_ 639 IBS_Tm_Lst_Reset_Days "FFFh";
BA_ "GenSigSendType" SG_ 640 Mem_D_Pos_Rq 2;
BA_ "GenSigCycleTimeActive" SG_ 640 Mem_D_Pos_Rq 100;
BA_ "FlexKomSigStartValue" SG_ 640 Mem_D_Pos_Rq "00h";
BA_ "FlexKomSID" SG_ 640 Mem_D_Pos_Rq 466;
BA_ "FlexKomSigStartPos" SG_ 640 Mem_D_Pos_Rq 1;
BA_ "FlexKomSigLaenge" SG_ 640 Mem_D_Pos_Rq 2;
BA_ "FlexKomSigName" SG_ 640 Mem_D_Pos_Rq "Mem_D_Pos_Rq";
BA_ "FlexKomComment" SG_ 640 Mem_D_Pos_Rq "Memory driver - position request";
BA_ "FlexKomIsMotorola" SG_ 640 Mem_D_Pos_Rq 1;
BA_ "GenSigSNA" SG_ 640 Mem_D_Pos_Rq "0h";
BA_ "GenSigSendType" SG_ 640 Mem_D_Rc_Rq 2;
BA_ "GenSigCycleTimeActive" SG_ 640 Mem_D_Rc_Rq 100;
BA_ "FlexKomSigStartValue" SG_ 640 Mem_D_Rc_Rq "00h";
BA_ "FlexKomSID" SG_ 640 Mem_D_Rc_Rq 467;
BA_ "FlexKomSigStartPos" SG_ 640 Mem_D_Rc_Rq 2;
BA_ "FlexKomSigLaenge" SG_ 640 Mem_D_Rc_Rq 1;
BA_ "FlexKomSigName" SG_ 640 Mem_D_Rc_Rq "Mem_D_Rc_Rq";
BA_ "FlexKomComment" SG_ 640 Mem_D_Rc_Rq "Memory driver - recall position";
BA_ "FlexKomIsMotorola" SG_ 640 Mem_D_Rc_Rq 1;
BA_ "GenSigSNA" SG_ 640 Mem_D_Rc_Rq "0h";
BA_ "GenSigSendType" SG_ 640 Mem_D_Sv_Rq 2;
BA_ "GenSigCycleTimeActive" SG_ 640 Mem_D_Sv_Rq 100;
BA_ "FlexKomSigStartValue" SG_ 640 Mem_D_Sv_Rq "00h";
BA_ "FlexKomSID" SG_ 640 Mem_D_Sv_Rq 468;
BA_ "FlexKomSigStartPos" SG_ 640 Mem_D_Sv_Rq 3;
BA_ "FlexKomSigLaenge" SG_ 640 Mem_D_Sv_Rq 1;
BA_ "FlexKomSigName" SG_ 640 Mem_D_Sv_Rq "Mem_D_Sv_Rq";
BA_ "FlexKomComment" SG_ 640 Mem_D_Sv_Rq "Memory driver - save position";
BA_ "FlexKomIsMotorola" SG_ 640 Mem_D_Sv_Rq 1;
BA_ "GenSigSNA" SG_ 640 Mem_D_Sv_Rq "0h";
BA_ "GenSigSendType" SG_ 656 UConnSeed1 1;
BA_ "FlexKomSigStartValue" SG_ 656 UConnSeed1 "00000000h";
BA_ "FlexKomSID" SG_ 656 UConnSeed1 1794;
BA_ "FlexKomSigStartPos" SG_ 656 UConnSeed1 7;
BA_ "FlexKomSigLaenge" SG_ 656 UConnSeed1 32;
BA_ "FlexKomSigName" SG_ 656 UConnSeed1 "RF_CharPkt";
BA_ "FlexKomComment" SG_ 656 UConnSeed1 "RF hub characters";
BA_ "FlexKomIsMotorola" SG_ 656 UConnSeed1 1;
BA_ "GenSigSNA" SG_ 656 UConnSeed1 "0h";
BA_ "GenSigSendType" SG_ 656 UConnSeed2 1;
BA_ "FlexKomSigStartValue" SG_ 656 UConnSeed2 "00000000h";
BA_ "FlexKomSID" SG_ 656 UConnSeed2 1794;
BA_ "FlexKomSigStartPos" SG_ 656 UConnSeed2 7;
BA_ "FlexKomSigLaenge" SG_ 656 UConnSeed2 32;
BA_ "FlexKomSigName" SG_ 656 UConnSeed2 "RF_CharPkt";
BA_ "FlexKomComment" SG_ 656 UConnSeed2 "RF hub characters";
BA_ "FlexKomIsMotorola" SG_ 656 UConnSeed2 1;
BA_ "GenSigSNA" SG_ 656 UConnSeed2 "0h";
BA_ "GenSigSendType" SG_ 656 UConnSeed3 1;
BA_ "FlexKomSigStartValue" SG_ 656 UConnSeed3 "00000000h";
BA_ "FlexKomSID" SG_ 656 UConnSeed3 1794;
BA_ "FlexKomSigStartPos" SG_ 656 UConnSeed3 7;
BA_ "FlexKomSigLaenge" SG_ 656 UConnSeed3 32;
BA_ "FlexKomSigName" SG_ 656 UConnSeed3 "RF_CharPkt";
BA_ "FlexKomComment" SG_ 656 UConnSeed3 "RF hub characters";
BA_ "FlexKomIsMotorola" SG_ 656 UConnSeed3 1;
BA_ "GenSigSNA" SG_ 656 UConnSeed3 "0h";
BA_ "GenSigSendType" SG_ 656 UConnSeed4 1;
BA_ "FlexKomSigStartValue" SG_ 656 UConnSeed4 "00000000h";
BA_ "FlexKomSID" SG_ 656 UConnSeed4 1794;
BA_ "FlexKomSigStartPos" SG_ 656 UConnSeed4 7;
BA_ "FlexKomSigLaenge" SG_ 656 UConnSeed4 32;
BA_ "FlexKomSigName" SG_ 656 UConnSeed4 "RF_CharPkt";
BA_ "FlexKomComment" SG_ 656 UConnSeed4 "RF hub characters";
BA_ "FlexKomIsMotorola" SG_ 656 UConnSeed4 1;
BA_ "GenSigSNA" SG_ 656 UConnSeed4 "0h";
BA_ "GenSigCycleTime" SG_ 658 MotorTorqueOverlaySteeringReq 10;
BA_ "FlexKomSigStartValue" SG_ 658 MotorTorqueOverlaySteeringReq "0000000000FFh";
BA_ "FlexKomSID" SG_ 658 MotorTorqueOverlaySteeringReq 1908;
BA_ "FlexKomSigStartPos" SG_ 658 MotorTorqueOverlaySteeringReq 7;
BA_ "FlexKomSigLaenge" SG_ 658 MotorTorqueOverlaySteeringReq 48;
BA_ "FlexKomSigName" SG_ 658 MotorTorqueOverlaySteeringReq "HaLF_StrCtrl";
BA_ "FlexKomComment" SG_ 658 MotorTorqueOverlaySteeringReq "Half steering control packet";
BA_ "FlexKomIsMotorola" SG_ 658 MotorTorqueOverlaySteeringReq 1;
BA_ "GenSigSNA" SG_ 658 MotorTorqueOverlaySteeringReq "0h";
BA_ "GenSigCycleTime" SG_ 658 MTO_HALFSystemSts 10;
BA_ "FlexKomSigStartValue" SG_ 658 MTO_HALFSystemSts "0000000000FFh";
BA_ "FlexKomSID" SG_ 658 MTO_HALFSystemSts 1908;
BA_ "FlexKomSigStartPos" SG_ 658 MTO_HALFSystemSts 7;
BA_ "FlexKomSigLaenge" SG_ 658 MTO_HALFSystemSts 48;
BA_ "FlexKomSigName" SG_ 658 MTO_HALFSystemSts "HaLF_StrCtrl";
BA_ "FlexKomComment" SG_ 658 MTO_HALFSystemSts "Half steering control packet";
BA_ "FlexKomIsMotorola" SG_ 658 MTO_HALFSystemSts 1;
BA_ "GenSigSNA" SG_ 658 MTO_HALFSystemSts "0h";
BA_ "GenSigCycleTime" SG_ 658 MotorTorqueOverlayIntActivation 10;
BA_ "FlexKomSigStartValue" SG_ 658 MotorTorqueOverlayIntActivation "0000000000FFh";
BA_ "FlexKomSID" SG_ 658 MotorTorqueOverlayIntActivation 1908;
BA_ "FlexKomSigStartPos" SG_ 658 MotorTorqueOverlayIntActivation 7;
BA_ "FlexKomSigLaenge" SG_ 658 MotorTorqueOverlayIntActivation 48;
BA_ "FlexKomSigName" SG_ 658 MotorTorqueOverlayIntActivation "HaLF_StrCtrl";
BA_ "FlexKomComment" SG_ 658 MotorTorqueOverlayIntActivation "Half steering control packet";
BA_ "FlexKomIsMotorola" SG_ 658 MotorTorqueOverlayIntActivation 1;
BA_ "GenSigSNA" SG_ 658 MotorTorqueOverlayIntActivation "0h";
BA_ "GenSigCycleTime" SG_ 658 MTO_HALFDriveStyleSts 10;
BA_ "FlexKomSigStartValue" SG_ 658 MTO_HALFDriveStyleSts "0000000000FFh";
BA_ "FlexKomSID" SG_ 658 MTO_HALFDriveStyleSts 1908;
BA_ "FlexKomSigStartPos" SG_ 658 MTO_HALFDriveStyleSts 7;
BA_ "FlexKomSigLaenge" SG_ 658 MTO_HALFDriveStyleSts 48;
BA_ "FlexKomSigName" SG_ 658 MTO_HALFDriveStyleSts "HaLF_StrCtrl";
BA_ "FlexKomComment" SG_ 658 MTO_HALFDriveStyleSts "Half steering control packet";
BA_ "FlexKomIsMotorola" SG_ 658 MTO_HALFDriveStyleSts 1;
BA_ "GenSigSNA" SG_ 658 MTO_HALFDriveStyleSts "7h";
BA_ "GenSigCycleTime" SG_ 658 MC_292h 10;
BA_ "FlexKomSigStartValue" SG_ 658 MC_292h "0000000000FFh";
BA_ "FlexKomSID" SG_ 658 MC_292h 1908;
BA_ "FlexKomSigStartPos" SG_ 658 MC_292h 7;
BA_ "FlexKomSigLaenge" SG_ 658 MC_292h 48;
BA_ "FlexKomSigName" SG_ 658 MC_292h "HaLF_StrCtrl";
BA_ "FlexKomComment" SG_ 658 MC_292h "Half steering control packet";
BA_ "FlexKomIsMotorola" SG_ 658 MC_292h 1;
BA_ "GenSigSNA" SG_ 658 MC_292h "0h";
BA_ "GenSigCycleTime" SG_ 658 CRC_292h 10;
BA_ "FlexKomSigStartValue" SG_ 658 CRC_292h "0000000000FFh";
BA_ "GenSigStartValue" SG_ 658 CRC_292h 255;
BA_ "FlexKomSID" SG_ 658 CRC_292h 1908;
BA_ "FlexKomSigStartPos" SG_ 658 CRC_292h 7;
BA_ "FlexKomSigLaenge" SG_ 658 CRC_292h 48;
BA_ "FlexKomSigName" SG_ 658 CRC_292h "HaLF_StrCtrl";
BA_ "FlexKomComment" SG_ 658 CRC_292h "Half steering control packet";
BA_ "FlexKomIsMotorola" SG_ 658 CRC_292h 1;
BA_ "GenSigSNA" SG_ 658 CRC_292h "FFh";
BA_ "GenSigCycleTime" SG_ 660 TO_Req 20;
BA_ "FlexKomSigStartValue" SG_ 660 TO_Req "00000000C00000FFh";
BA_ "FlexKomSID" SG_ 660 TO_Req 1909;
BA_ "FlexKomSigStartPos" SG_ 660 TO_Req 7;
BA_ "FlexKomSigLaenge" SG_ 660 TO_Req 64;
BA_ "FlexKomSigName" SG_ 660 TO_Req "DST_TOC";
BA_ "FlexKomComment" SG_ 660 TO_Req "DST_TOC";
BA_ "FlexKomIsMotorola" SG_ 660 TO_Req 1;
BA_ "GenSigSNA" SG_ 660 TO_Req "0h";
BA_ "GenSigCycleTime" SG_ 660 TOC_Fault 20;
BA_ "FlexKomSigStartValue" SG_ 660 TOC_Fault "00000000C00000FFh";
BA_ "FlexKomSID" SG_ 660 TOC_Fault 1909;
BA_ "FlexKomSigStartPos" SG_ 660 TOC_Fault 7;
BA_ "FlexKomSigLaenge" SG_ 660 TOC_Fault 64;
BA_ "FlexKomSigName" SG_ 660 TOC_Fault "DST_TOC";
BA_ "FlexKomComment" SG_ 660 TOC_Fault "DST_TOC";
BA_ "FlexKomIsMotorola" SG_ 660 TOC_Fault 1;
BA_ "GenSigSNA" SG_ 660 TOC_Fault "3h";
BA_ "GenSigCycleTime" SG_ 660 TOC_Act_Req 20;
BA_ "FlexKomSigStartValue" SG_ 660 TOC_Act_Req "00000000C00000FFh";
BA_ "FlexKomSID" SG_ 660 TOC_Act_Req 1909;
BA_ "FlexKomSigStartPos" SG_ 660 TOC_Act_Req 7;
BA_ "FlexKomSigLaenge" SG_ 660 TOC_Act_Req 64;
BA_ "FlexKomSigName" SG_ 660 TOC_Act_Req "DST_TOC";
BA_ "FlexKomComment" SG_ 660 TOC_Act_Req "DST_TOC";
BA_ "FlexKomIsMotorola" SG_ 660 TOC_Act_Req 1;
BA_ "GenSigSNA" SG_ 660 TOC_Act_Req "3h";
BA_ "GenSigCycleTime" SG_ 660 BrkPrss_One 20;
BA_ "FlexKomSigStartValue" SG_ 660 BrkPrss_One "00000000C00000FFh";
BA_ "FlexKomSID" SG_ 660 BrkPrss_One 1909;
BA_ "FlexKomSigStartPos" SG_ 660 BrkPrss_One 7;
BA_ "FlexKomSigLaenge" SG_ 660 BrkPrss_One 64;
BA_ "FlexKomSigName" SG_ 660 BrkPrss_One "DST_TOC";
BA_ "FlexKomComment" SG_ 660 BrkPrss_One "DST_TOC";
BA_ "FlexKomIsMotorola" SG_ 660 BrkPrss_One 1;
BA_ "GenSigSNA" SG_ 660 BrkPrss_One "0h";
BA_ "GenSigCycleTime" SG_ 660 BrkPrss_Two 20;
BA_ "FlexKomSigStartValue" SG_ 660 BrkPrss_Two "00000000C00000FFh";
BA_ "FlexKomSID" SG_ 660 BrkPrss_Two 1909;
BA_ "FlexKomSigStartPos" SG_ 660 BrkPrss_Two 7;
BA_ "FlexKomSigLaenge" SG_ 660 BrkPrss_Two 64;
BA_ "FlexKomSigName" SG_ 660 BrkPrss_Two "DST_TOC";
BA_ "FlexKomComment" SG_ 660 BrkPrss_Two "DST_TOC";
BA_ "FlexKomIsMotorola" SG_ 660 BrkPrss_Two 1;
BA_ "GenSigSNA" SG_ 660 BrkPrss_Two "0h";
BA_ "GenSigCycleTime" SG_ 660 SyncPos 20;
BA_ "FlexKomSigStartValue" SG_ 660 SyncPos "00000000C00000FFh";
BA_ "GenSigStartValue" SG_ 660 SyncPos 6;
BA_ "FlexKomSID" SG_ 660 SyncPos 1909;
BA_ "FlexKomSigStartPos" SG_ 660 SyncPos 7;
BA_ "FlexKomSigLaenge" SG_ 660 SyncPos 64;
BA_ "FlexKomSigName" SG_ 660 SyncPos "DST_TOC";
BA_ "FlexKomComment" SG_ 660 SyncPos "DST_TOC";
BA_ "FlexKomIsMotorola" SG_ 660 SyncPos 1;
BA_ "GenSigSNA" SG_ 660 SyncPos "7h";
BA_ "GenSigCycleTime" SG_ 660 TOC_Sts 20;
BA_ "FlexKomSigStartValue" SG_ 660 TOC_Sts "00000000C00000FFh";
BA_ "FlexKomSID" SG_ 660 TOC_Sts 1909;
BA_ "FlexKomSigStartPos" SG_ 660 TOC_Sts 7;
BA_ "FlexKomSigLaenge" SG_ 660 TOC_Sts 64;
BA_ "FlexKomSigName" SG_ 660 TOC_Sts "DST_TOC";
BA_ "FlexKomComment" SG_ 660 TOC_Sts "DST_TOC";
BA_ "FlexKomIsMotorola" SG_ 660 TOC_Sts 1;
BA_ "GenSigSNA" SG_ 660 TOC_Sts "Fh";
BA_ "GenSigCycleTime" SG_ 660 MC_294h 20;
BA_ "FlexKomSigStartValue" SG_ 660 MC_294h "00000000C00000FFh";
BA_ "FlexKomSID" SG_ 660 MC_294h 1909;
BA_ "FlexKomSigStartPos" SG_ 660 MC_294h 7;
BA_ "FlexKomSigLaenge" SG_ 660 MC_294h 64;
BA_ "FlexKomSigName" SG_ 660 MC_294h "DST_TOC";
BA_ "FlexKomComment" SG_ 660 MC_294h "DST_TOC";
BA_ "FlexKomIsMotorola" SG_ 660 MC_294h 1;
BA_ "GenSigSNA" SG_ 660 MC_294h "0h";
BA_ "GenSigCycleTime" SG_ 660 CRC_294h 20;
BA_ "FlexKomSigStartValue" SG_ 660 CRC_294h "00000000C00000FFh";
BA_ "GenSigStartValue" SG_ 660 CRC_294h 255;
BA_ "FlexKomSID" SG_ 660 CRC_294h 1909;
BA_ "FlexKomSigStartPos" SG_ 660 CRC_294h 7;
BA_ "FlexKomSigLaenge" SG_ 660 CRC_294h 64;
BA_ "FlexKomSigName" SG_ 660 CRC_294h "DST_TOC";
BA_ "FlexKomComment" SG_ 660 CRC_294h "DST_TOC";
BA_ "FlexKomIsMotorola" SG_ 660 CRC_294h 1;
BA_ "GenSigSNA" SG_ 660 CRC_294h "FFh";
BA_ "GenSigCycleTime" SG_ 669 BSMBrkReq 20;
BA_ "FlexKomSigStartValue" SG_ 669 BSMBrkReq "0000FFh";
BA_ "FlexKomSID" SG_ 669 BSMBrkReq 2013;
BA_ "FlexKomSigStartPos" SG_ 669 BSMBrkReq 7;
BA_ "FlexKomSigLaenge" SG_ 669 BSMBrkReq 24;
BA_ "FlexKomSigName" SG_ 669 BSMBrkReq "EPB_A1_Pkt";
BA_ "FlexKomComment" SG_ 669 BSMBrkReq "EPB_A1 message packet";
BA_ "FlexKomIsMotorola" SG_ 669 BSMBrkReq 1;
BA_ "GenSigSNA" SG_ 669 BSMBrkReq "0h";
BA_ "GenSigCycleTime" SG_ 669 BSMBrkReqActive 20;
BA_ "FlexKomSigStartValue" SG_ 669 BSMBrkReqActive "0000FFh";
BA_ "FlexKomSID" SG_ 669 BSMBrkReqActive 2013;
BA_ "FlexKomSigStartPos" SG_ 669 BSMBrkReqActive 7;
BA_ "FlexKomSigLaenge" SG_ 669 BSMBrkReqActive 24;
BA_ "FlexKomSigName" SG_ 669 BSMBrkReqActive "EPB_A1_Pkt";
BA_ "FlexKomComment" SG_ 669 BSMBrkReqActive "EPB_A1 message packet";
BA_ "FlexKomIsMotorola" SG_ 669 BSMBrkReqActive 1;
BA_ "GenSigSNA" SG_ 669 BSMBrkReqActive "0h";
BA_ "GenSigCycleTime" SG_ 669 EPBHoldSts 20;
BA_ "FlexKomSigStartValue" SG_ 669 EPBHoldSts "0000FFh";
BA_ "GenSigTimeout_ORC" SG_ 669 EPBHoldSts 70;
BA_ "FlexKomSID" SG_ 669 EPBHoldSts 2013;
BA_ "FlexKomSigStartPos" SG_ 669 EPBHoldSts 7;
BA_ "FlexKomSigLaenge" SG_ 669 EPBHoldSts 24;
BA_ "FlexKomSigName" SG_ 669 EPBHoldSts "EPB_A1_Pkt";
BA_ "FlexKomComment" SG_ 669 EPBHoldSts "EPB_A1 message packet";
BA_ "FlexKomIsMotorola" SG_ 669 EPBHoldSts 1;
BA_ "GenSigSNA" SG_ 669 EPBHoldSts "0h";
BA_ "GenSigCycleTime" SG_ 669 MC_EPB_A1 20;
BA_ "FlexKomSigStartValue" SG_ 669 MC_EPB_A1 "0000FFh";
BA_ "FlexKomSID" SG_ 669 MC_EPB_A1 2013;
BA_ "FlexKomSigStartPos" SG_ 669 MC_EPB_A1 7;
BA_ "FlexKomSigLaenge" SG_ 669 MC_EPB_A1 24;
BA_ "FlexKomSigName" SG_ 669 MC_EPB_A1 "EPB_A1_Pkt";
BA_ "FlexKomComment" SG_ 669 MC_EPB_A1 "EPB_A1 message packet";
BA_ "FlexKomIsMotorola" SG_ 669 MC_EPB_A1 1;
BA_ "GenSigSNA" SG_ 669 MC_EPB_A1 "0h";
BA_ "GenSigCycleTime" SG_ 669 CRC_EPB_A1 20;
BA_ "FlexKomSigStartValue" SG_ 669 CRC_EPB_A1 "0000FFh";
BA_ "GenSigStartValue" SG_ 669 CRC_EPB_A1 255;
BA_ "FlexKomSID" SG_ 669 CRC_EPB_A1 2013;
BA_ "FlexKomSigStartPos" SG_ 669 CRC_EPB_A1 7;
BA_ "FlexKomSigLaenge" SG_ 669 CRC_EPB_A1 24;
BA_ "FlexKomSigName" SG_ 669 CRC_EPB_A1 "EPB_A1_Pkt";
BA_ "FlexKomComment" SG_ 669 CRC_EPB_A1 "EPB_A1 message packet";
BA_ "FlexKomIsMotorola" SG_ 669 CRC_EPB_A1 1;
BA_ "GenSigSNA" SG_ 669 CRC_EPB_A1 "FFh";
BA_ "GenSigCycleTime" SG_ 671 TorqueOverlaySteeringReq 20;
BA_ "FlexKomSigStartValue" SG_ 671 TorqueOverlaySteeringReq "00000000000000FFh";
BA_ "FlexKomSID" SG_ 671 TorqueOverlaySteeringReq 1907;
BA_ "FlexKomSigStartPos" SG_ 671 TorqueOverlaySteeringReq 7;
BA_ "FlexKomSigLaenge" SG_ 671 TorqueOverlaySteeringReq 64;
BA_ "FlexKomSigName" SG_ 671 TorqueOverlaySteeringReq "PTS_StrCtrl";
BA_ "FlexKomComment" SG_ 671 TorqueOverlaySteeringReq "PTS steering control packet";
BA_ "FlexKomIsMotorola" SG_ 671 TorqueOverlaySteeringReq 1;
BA_ "GenSigSNA" SG_ 671 TorqueOverlaySteeringReq "0h";
BA_ "GenSigCycleTime" SG_ 671 ManeuverPhase 20;
BA_ "FlexKomSigStartValue" SG_ 671 ManeuverPhase "00000000000000FFh";
BA_ "FlexKomSID" SG_ 671 ManeuverPhase 1907;
BA_ "FlexKomSigStartPos" SG_ 671 ManeuverPhase 7;
BA_ "FlexKomSigLaenge" SG_ 671 ManeuverPhase 64;
BA_ "FlexKomSigName" SG_ 671 ManeuverPhase "PTS_StrCtrl";
BA_ "FlexKomComment" SG_ 671 ManeuverPhase "PTS steering control packet";
BA_ "FlexKomIsMotorola" SG_ 671 ManeuverPhase 1;
BA_ "GenSigSNA" SG_ 671 ManeuverPhase "0h";
BA_ "GenSigCycleTime" SG_ 671 PTSDriveStyleReqSts 20;
BA_ "FlexKomSigStartValue" SG_ 671 PTSDriveStyleReqSts "00000000000000FFh";
BA_ "FlexKomSID" SG_ 671 PTSDriveStyleReqSts 1907;
BA_ "FlexKomSigStartPos" SG_ 671 PTSDriveStyleReqSts 7;
BA_ "FlexKomSigLaenge" SG_ 671 PTSDriveStyleReqSts 64;
BA_ "FlexKomSigName" SG_ 671 PTSDriveStyleReqSts "PTS_StrCtrl";
BA_ "FlexKomComment" SG_ 671 PTSDriveStyleReqSts "PTS steering control packet";
BA_ "FlexKomIsMotorola" SG_ 671 PTSDriveStyleReqSts 1;
BA_ "GenSigSNA" SG_ 671 PTSDriveStyleReqSts "0h";
BA_ "GenSigCycleTime" SG_ 671 PTSSystemFault 20;
BA_ "FlexKomSigStartValue" SG_ 671 PTSSystemFault "00000000000000FFh";
BA_ "GenSigTimeout_IC" SG_ 671 PTSSystemFault 210;
BA_ "FlexKomSID" SG_ 671 PTSSystemFault 1907;
BA_ "FlexKomSigStartPos" SG_ 671 PTSSystemFault 7;
BA_ "FlexKomSigLaenge" SG_ 671 PTSSystemFault 64;
BA_ "FlexKomSigName" SG_ 671 PTSSystemFault "PTS_StrCtrl";
BA_ "FlexKomComment" SG_ 671 PTSSystemFault "PTS steering control packet";
BA_ "FlexKomIsMotorola" SG_ 671 PTSSystemFault 1;
BA_ "GenSigSNA" SG_ 671 PTSSystemFault "0h";
BA_ "GenSigCycleTime" SG_ 671 TorqueOverlayIntActivation 20;
BA_ "FlexKomSigStartValue" SG_ 671 TorqueOverlayIntActivation "00000000000000FFh";
BA_ "FlexKomSID" SG_ 671 TorqueOverlayIntActivation 1907;
BA_ "FlexKomSigStartPos" SG_ 671 TorqueOverlayIntActivation 7;
BA_ "FlexKomSigLaenge" SG_ 671 TorqueOverlayIntActivation 64;
BA_ "FlexKomSigName" SG_ 671 TorqueOverlayIntActivation "PTS_StrCtrl";
BA_ "FlexKomComment" SG_ 671 TorqueOverlayIntActivation "PTS steering control packet";
BA_ "FlexKomIsMotorola" SG_ 671 TorqueOverlayIntActivation 1;
BA_ "GenSigSNA" SG_ 671 TorqueOverlayIntActivation "0h";
BA_ "GenSigCycleTime" SG_ 671 PTS_ManoeuvreMode 20;
BA_ "FlexKomSigStartValue" SG_ 671 PTS_ManoeuvreMode "00000000000000FFh";
BA_ "GenSigTimeout_IC" SG_ 671 PTS_ManoeuvreMode 210;
BA_ "FlexKomSID" SG_ 671 PTS_ManoeuvreMode 1907;
BA_ "FlexKomSigStartPos" SG_ 671 PTS_ManoeuvreMode 7;
BA_ "FlexKomSigLaenge" SG_ 671 PTS_ManoeuvreMode 64;
BA_ "FlexKomSigName" SG_ 671 PTS_ManoeuvreMode "PTS_StrCtrl";
BA_ "FlexKomComment" SG_ 671 PTS_ManoeuvreMode "PTS steering control packet";
BA_ "FlexKomIsMotorola" SG_ 671 PTS_ManoeuvreMode 1;
BA_ "GenSigSNA" SG_ 671 PTS_ManoeuvreMode "7h";
BA_ "GenSigCycleTime" SG_ 671 MC_29Fh 20;
BA_ "FlexKomSigStartValue" SG_ 671 MC_29Fh "00000000000000FFh";
BA_ "FlexKomSID" SG_ 671 MC_29Fh 1907;
BA_ "FlexKomSigStartPos" SG_ 671 MC_29Fh 7;
BA_ "FlexKomSigLaenge" SG_ 671 MC_29Fh 64;
BA_ "FlexKomSigName" SG_ 671 MC_29Fh "PTS_StrCtrl";
BA_ "FlexKomComment" SG_ 671 MC_29Fh "PTS steering control packet";
BA_ "FlexKomIsMotorola" SG_ 671 MC_29Fh 1;
BA_ "GenSigSNA" SG_ 671 MC_29Fh "0h";
BA_ "GenSigCycleTime" SG_ 671 CRC_29Fh 20;
BA_ "FlexKomSigStartValue" SG_ 671 CRC_29Fh "00000000000000FFh";
BA_ "GenSigStartValue" SG_ 671 CRC_29Fh 255;
BA_ "FlexKomSID" SG_ 671 CRC_29Fh 1907;
BA_ "FlexKomSigStartPos" SG_ 671 CRC_29Fh 7;
BA_ "FlexKomSigLaenge" SG_ 671 CRC_29Fh 64;
BA_ "FlexKomSigName" SG_ 671 CRC_29Fh "PTS_StrCtrl";
BA_ "FlexKomComment" SG_ 671 CRC_29Fh "PTS steering control packet";
BA_ "FlexKomIsMotorola" SG_ 671 CRC_29Fh 1;
BA_ "GenSigSNA" SG_ 671 CRC_29Fh "FFh";
BA_ "GenSigCycleTime" SG_ 672 MIL_OnRq 100;
BA_ "FlexKomSigStartValue" SG_ 672 MIL_OnRq "00h";
BA_ "GenSigTimeout_IC" SG_ 672 MIL_OnRq 1050;
BA_ "GenSigTimeout_ORC" SG_ 672 MIL_OnRq 350;
BA_ "FlexKomSID" SG_ 672 MIL_OnRq 714;
BA_ "FlexKomSigLaenge" SG_ 672 MIL_OnRq 1;
BA_ "FlexKomSigName" SG_ 672 MIL_OnRq "MIL_OnRq";
BA_ "FlexKomComment" SG_ 672 MIL_OnRq "MIL on request from the engine";
BA_ "FlexKomIsMotorola" SG_ 672 MIL_OnRq 1;
BA_ "GenSigSNA" SG_ 672 MIL_OnRq "0h";
BA_ "GenSigCycleTime" SG_ 672 MIL_IND_BLINK 100;
BA_ "FlexKomSigStartValue" SG_ 672 MIL_IND_BLINK "00h";
BA_ "GenSigTimeout_IC" SG_ 672 MIL_IND_BLINK 1050;
BA_ "GenSigTimeout_ORC" SG_ 672 MIL_IND_BLINK 350;
BA_ "FlexKomSID" SG_ 672 MIL_IND_BLINK 713;
BA_ "FlexKomSigStartPos" SG_ 672 MIL_IND_BLINK 1;
BA_ "FlexKomSigLaenge" SG_ 672 MIL_IND_BLINK 1;
BA_ "FlexKomSigName" SG_ 672 MIL_IND_BLINK "MIL_IND_BLINK";
BA_ "FlexKomComment" SG_ 672 MIL_IND_BLINK "Request MIL blink (OBD II)";
BA_ "FlexKomIsMotorola" SG_ 672 MIL_IND_BLINK 1;
BA_ "GenSigSNA" SG_ 672 MIL_IND_BLINK "0h";
BA_ "GenSigCycleTime" SG_ 672 ETC_IND_LMP 100;
BA_ "FlexKomSigStartValue" SG_ 672 ETC_IND_LMP "00h";
BA_ "GenSigTimeout_IC" SG_ 672 ETC_IND_LMP 1050;
BA_ "GenSigTimeout_ETM" SG_ 672 ETC_IND_LMP 1050;
BA_ "FlexKomSID" SG_ 672 ETC_IND_LMP 712;
BA_ "FlexKomSigStartPos" SG_ 672 ETC_IND_LMP 3;
BA_ "FlexKomSigLaenge" SG_ 672 ETC_IND_LMP 2;
BA_ "FlexKomSigName" SG_ 672 ETC_IND_LMP "ETC_IND_LMP";
BA_ "FlexKomComment" SG_ 672 ETC_IND_LMP "ETC faulty, indicator lamp request";
BA_ "FlexKomIsMotorola" SG_ 672 ETC_IND_LMP 1;
BA_ "GenSigSNA" SG_ 672 ETC_IND_LMP "3h";
BA_ "GenSigCycleTime" SG_ 672 MZR_MODE_ACT 100;
BA_ "FlexKomSigStartValue" SG_ 672 MZR_MODE_ACT "00h";
BA_ "GenSigTimeout_IC" SG_ 672 MZR_MODE_ACT 1050;
BA_ "GenSigTimeout_ETM" SG_ 672 MZR_MODE_ACT 1050;
BA_ "FlexKomSID" SG_ 672 MZR_MODE_ACT 715;
BA_ "FlexKomSigStartPos" SG_ 672 MZR_MODE_ACT 4;
BA_ "FlexKomSigLaenge" SG_ 672 MZR_MODE_ACT 1;
BA_ "FlexKomSigName" SG_ 672 MZR_MODE_ACT "MZR_MODE_ACT";
BA_ "FlexKomComment" SG_ 672 MZR_MODE_ACT "Mizer mode active (enabled = [1])";
BA_ "FlexKomIsMotorola" SG_ 672 MZR_MODE_ACT 1;
BA_ "GenSigSNA" SG_ 672 MZR_MODE_ACT "0h";
BA_ "GenSigCycleTime" SG_ 672 FUEL_SAV_MD_ACT 100;
BA_ "FlexKomSigStartValue" SG_ 672 FUEL_SAV_MD_ACT "03h";
BA_ "GenSigStartValue" SG_ 672 FUEL_SAV_MD_ACT 3;
BA_ "GenSigTimeout_CBC" SG_ 672 FUEL_SAV_MD_ACT 1050;
BA_ "GenSigTimeout_IC" SG_ 672 FUEL_SAV_MD_ACT 1050;
BA_ "FlexKomSID" SG_ 672 FUEL_SAV_MD_ACT 1083;
BA_ "FlexKomSigStartPos" SG_ 672 FUEL_SAV_MD_ACT 6;
BA_ "FlexKomSigLaenge" SG_ 672 FUEL_SAV_MD_ACT 2;
BA_ "FlexKomSigName" SG_ 672 FUEL_SAV_MD_ACT "FUEL_SAV_MD_ACT";
BA_ "FlexKomComment" SG_ 672 FUEL_SAV_MD_ACT "Engine operating in fuel efficient manner";
BA_ "FlexKomIsMotorola" SG_ 672 FUEL_SAV_MD_ACT 1;
BA_ "GenSigSNA" SG_ 672 FUEL_SAV_MD_ACT "3h";
BA_ "GenSigCycleTime" SG_ 672 OIL_IND_LMP_FLSH 100;
BA_ "FlexKomSigStartValue" SG_ 672 OIL_IND_LMP_FLSH "00h";
BA_ "GenSigTimeout_IC" SG_ 672 OIL_IND_LMP_FLSH 1050;
BA_ "FlexKomSID" SG_ 672 OIL_IND_LMP_FLSH 716;
BA_ "FlexKomSigStartPos" SG_ 672 OIL_IND_LMP_FLSH 8;
BA_ "FlexKomSigLaenge" SG_ 672 OIL_IND_LMP_FLSH 1;
BA_ "FlexKomSigName" SG_ 672 OIL_IND_LMP_FLSH "OIL_IND_LMP_FLSH";
BA_ "FlexKomComment" SG_ 672 OIL_IND_LMP_FLSH "Oil indicator lamp flash (for in plant use)";
BA_ "FlexKomIsMotorola" SG_ 672 OIL_IND_LMP_FLSH 1;
BA_ "GenSigSNA" SG_ 672 OIL_IND_LMP_FLSH "0h";
BA_ "GenSigCycleTime" SG_ 672 AutoOilChg 100;
BA_ "FlexKomSigStartValue" SG_ 672 AutoOilChg "00h";
BA_ "GenSigTimeout_IC" SG_ 672 AutoOilChg 1050;
BA_ "FlexKomSID" SG_ 672 AutoOilChg 686;
BA_ "FlexKomSigStartPos" SG_ 672 AutoOilChg 9;
BA_ "FlexKomSigLaenge" SG_ 672 AutoOilChg 1;
BA_ "FlexKomSigName" SG_ 672 AutoOilChg "AutoOilChg";
BA_ "FlexKomComment" SG_ 672 AutoOilChg "Automatic Oil Change Indicator";
BA_ "FlexKomIsMotorola" SG_ 672 AutoOilChg 1;
BA_ "GenSigSNA" SG_ 672 AutoOilChg "0h";
BA_ "GenSigCycleTime" SG_ 672 EngOilIndLmp_On_Rq 100;
BA_ "FlexKomSigStartValue" SG_ 672 EngOilIndLmp_On_Rq "00h";
BA_ "GenSigTimeout_IC" SG_ 672 EngOilIndLmp_On_Rq 1050;
BA_ "GenSigTimeout_ETM" SG_ 672 EngOilIndLmp_On_Rq 1050;
BA_ "FlexKomSID" SG_ 672 EngOilIndLmp_On_Rq 1080;
BA_ "FlexKomSigStartPos" SG_ 672 EngOilIndLmp_On_Rq 10;
BA_ "FlexKomSigLaenge" SG_ 672 EngOilIndLmp_On_Rq 1;
BA_ "FlexKomSigName" SG_ 672 EngOilIndLmp_On_Rq "EngOilIndLmp_On_Rq";
BA_ "FlexKomComment" SG_ 672 EngOilIndLmp_On_Rq "Request oil level/oil pressure indicator lamp";
BA_ "FlexKomIsMotorola" SG_ 672 EngOilIndLmp_On_Rq 1;
BA_ "GenSigSNA" SG_ 672 EngOilIndLmp_On_Rq "1h";
BA_ "GenSigCycleTime" SG_ 672 OIL_TEMP_IND_RQ 100;
BA_ "FlexKomSigStartValue" SG_ 672 OIL_TEMP_IND_RQ "00h";
BA_ "GenSigTimeout_IC" SG_ 672 OIL_TEMP_IND_RQ 1050;
BA_ "GenSigTimeout_ETM" SG_ 672 OIL_TEMP_IND_RQ 1050;
BA_ "FlexKomSID" SG_ 672 OIL_TEMP_IND_RQ 718;
BA_ "FlexKomSigStartPos" SG_ 672 OIL_TEMP_IND_RQ 14;
BA_ "FlexKomSigLaenge" SG_ 672 OIL_TEMP_IND_RQ 4;
BA_ "FlexKomSigName" SG_ 672 OIL_TEMP_IND_RQ "OIL_TEMP_RQ";
BA_ "FlexKomComment" SG_ 672 OIL_TEMP_IND_RQ "Engine oil overtemp. indicator/chime request";
BA_ "FlexKomIsMotorola" SG_ 672 OIL_TEMP_IND_RQ 1;
BA_ "GenSigSNA" SG_ 672 OIL_TEMP_IND_RQ "3h";
BA_ "GenSigCycleTime" SG_ 672 OIL_TEMP_CHM_RQ 100;
BA_ "FlexKomSigStartValue" SG_ 672 OIL_TEMP_CHM_RQ "00h";
BA_ "GenSigTimeout_IC" SG_ 672 OIL_TEMP_CHM_RQ 1050;
BA_ "FlexKomSID" SG_ 672 OIL_TEMP_CHM_RQ 718;
BA_ "FlexKomSigStartPos" SG_ 672 OIL_TEMP_CHM_RQ 14;
BA_ "FlexKomSigLaenge" SG_ 672 OIL_TEMP_CHM_RQ 4;
BA_ "FlexKomSigName" SG_ 672 OIL_TEMP_CHM_RQ "OIL_TEMP_RQ";
BA_ "FlexKomComment" SG_ 672 OIL_TEMP_CHM_RQ "Engine oil overtemp. indicator/chime request";
BA_ "FlexKomIsMotorola" SG_ 672 OIL_TEMP_CHM_RQ 1;
BA_ "GenSigSNA" SG_ 672 OIL_TEMP_CHM_RQ "0h";
BA_ "GenSigCycleTime" SG_ 672 ChkFuelCap 100;
BA_ "FlexKomSigStartValue" SG_ 672 ChkFuelCap "00h";
BA_ "GenSigTimeout_IC" SG_ 672 ChkFuelCap 1050;
BA_ "GenSigTimeout_ETM" SG_ 672 ChkFuelCap 1050;
BA_ "FlexKomSID" SG_ 672 ChkFuelCap 1082;
BA_ "FlexKomSigStartPos" SG_ 672 ChkFuelCap 15;
BA_ "FlexKomSigLaenge" SG_ 672 ChkFuelCap 1;
BA_ "FlexKomSigName" SG_ 672 ChkFuelCap "ChkFuelCap";
BA_ "FlexKomComment" SG_ 672 ChkFuelCap "Check fuel cap";
BA_ "FlexKomIsMotorola" SG_ 672 ChkFuelCap 1;
BA_ "GenSigSNA" SG_ 672 ChkFuelCap "0h";
BA_ "GenSigCycleTime" SG_ 672 OIL_PRESS 100;
BA_ "FlexKomSigStartValue" SG_ 672 OIL_PRESS "FFh";
BA_ "GenSigStartValue" SG_ 672 OIL_PRESS 255;
BA_ "GenSigTimeout_CBC" SG_ 672 OIL_PRESS 1050;
BA_ "GenSigTimeout_IC" SG_ 672 OIL_PRESS 1050;
BA_ "FlexKomSID" SG_ 672 OIL_PRESS 717;
BA_ "FlexKomSigStartPos" SG_ 672 OIL_PRESS 23;
BA_ "FlexKomSigLaenge" SG_ 672 OIL_PRESS 8;
BA_ "FlexKomSigName" SG_ 672 OIL_PRESS "OIL_PRESS";
BA_ "FlexKomComment" SG_ 672 OIL_PRESS "Oil pressure";
BA_ "FlexKomIsMotorola" SG_ 672 OIL_PRESS 1;
BA_ "GenSigSNA" SG_ 672 OIL_PRESS "FFh";
BA_ "GenSigCycleTime" SG_ 672 EngOilTemp 100;
BA_ "FlexKomSigStartValue" SG_ 672 EngOilTemp "FFh";
BA_ "GenSigStartValue" SG_ 672 EngOilTemp 255;
BA_ "GenSigTimeout_CBC" SG_ 672 EngOilTemp 1050;
BA_ "GenSigTimeout_IC" SG_ 672 EngOilTemp 1050;
BA_ "FlexKomSID" SG_ 672 EngOilTemp 440;
BA_ "FlexKomSigStartPos" SG_ 672 EngOilTemp 31;
BA_ "FlexKomSigLaenge" SG_ 672 EngOilTemp 8;
BA_ "FlexKomSigName" SG_ 672 EngOilTemp "EngOilTemp";
BA_ "FlexKomComment" SG_ 672 EngOilTemp "Oil temperature";
BA_ "FlexKomIsMotorola" SG_ 672 EngOilTemp 1;
BA_ "GenSigSNA" SG_ 672 EngOilTemp "FFh";
BA_ "GenSigCycleTime" SG_ 672 FuelCons 100;
BA_ "FlexKomSigStartValue" SG_ 672 FuelCons "FFFFh";
BA_ "GenSigStartValue" SG_ 672 FuelCons 65535;
BA_ "GenSigTimeout_CBC" SG_ 672 FuelCons 1050;
BA_ "GenSigTimeout_IC" SG_ 672 FuelCons 1050;
BA_ "FlexKomSID" SG_ 672 FuelCons 443;
BA_ "FlexKomSigStartPos" SG_ 672 FuelCons 39;
BA_ "FlexKomSigLaenge" SG_ 672 FuelCons 16;
BA_ "FlexKomSigName" SG_ 672 FuelCons "FuelCons";
BA_ "FlexKomComment" SG_ 672 FuelCons "Fuel consumption";
BA_ "FlexKomIsMotorola" SG_ 672 FuelCons 1;
BA_ "GenSigSNA" SG_ 672 FuelCons "FFFFh";
BA_ "GenSigCycleTime" SG_ 672 DefFuelEcon 100;
BA_ "FlexKomSigStartValue" SG_ 672 DefFuelEcon "FFh";
BA_ "GenSigStartValue" SG_ 672 DefFuelEcon 255;
BA_ "GenSigTimeout_IC" SG_ 672 DefFuelEcon 1050;
BA_ "FlexKomSID" SG_ 672 DefFuelEcon 709;
BA_ "FlexKomSigStartPos" SG_ 672 DefFuelEcon 55;
BA_ "FlexKomSigLaenge" SG_ 672 DefFuelEcon 8;
BA_ "FlexKomSigName" SG_ 672 DefFuelEcon "DefFuelEcon";
BA_ "FlexKomComment" SG_ 672 DefFuelEcon "Default fuel economy";
BA_ "FlexKomIsMotorola" SG_ 672 DefFuelEcon 1;
BA_ "GenSigSNA" SG_ 672 DefFuelEcon "FFh";
BA_ "GenSigCycleTime" SG_ 672 EngRun_Stat 100;
BA_ "FlexKomSigStartValue" SG_ 672 EngRun_Stat "07h";
BA_ "GenSigStartValue" SG_ 672 EngRun_Stat 7;
BA_ "GenSigTimeout_CBC" SG_ 672 EngRun_Stat 1050;
BA_ "GenSigTimeout_IC" SG_ 672 EngRun_Stat 1050;
BA_ "FlexKomSID" SG_ 672 EngRun_Stat 1081;
BA_ "FlexKomSigStartPos" SG_ 672 EngRun_Stat 58;
BA_ "FlexKomSigLaenge" SG_ 672 EngRun_Stat 3;
BA_ "FlexKomSigName" SG_ 672 EngRun_Stat "EngRun_Stat";
BA_ "FlexKomComment" SG_ 672 EngRun_Stat "Engine running state";
BA_ "FlexKomIsMotorola" SG_ 672 EngRun_Stat 1;
BA_ "GenSigSNA" SG_ 672 EngRun_Stat "7h";
BA_ "GenSigCycleTime" SG_ 672 RedntHdStat 100;
BA_ "FlexKomSigStartValue" SG_ 672 RedntHdStat "00h";
BA_ "GenSigTimeout_IC" SG_ 672 RedntHdStat 1050;
BA_ "FlexKomSID" SG_ 672 RedntHdStat 1407;
BA_ "FlexKomSigStartPos" SG_ 672 RedntHdStat 60;
BA_ "FlexKomSigLaenge" SG_ 672 RedntHdStat 2;
BA_ "FlexKomSigName" SG_ 672 RedntHdStat "RedntHdStat";
BA_ "FlexKomComment" SG_ 672 RedntHdStat "Redundant Hood Status";
BA_ "FlexKomIsMotorola" SG_ 672 RedntHdStat 1;
BA_ "GenSigSNA" SG_ 672 RedntHdStat "3h";
VAL_ 530 DEF_LOW 3 "SNA" 2 "BLINK" 1 "CONT" 0 "OFF" ;
VAL_ 530 PFW_Stat 15 "SNA" 14 "PWR_RED_RL" 13 "RegActPFW_StatRL" 12 "REG_CMPL_RL" 11 "SER_REQ_RL" 10 "SerRqPFW_StatRL" 9 "RegRqPFW_StatRL" 6 "PWR_RED" 5 "RegActPFW_Stat" 4 "REG_CMPL" 3 "SER_REQ" 2 "SerRqPFW_Stat" 1 "RegRqPFW_Stat" 0 "PFW_MN" ;
VAL_ 530 PrcntCplt 15 "SNA" ;
VAL_ 530 FuelFltrHtrReq 3 "SNA" 2 "ND" 1 "ON" 0 "OFF" ;
VAL_ 530 ECM_HMI_Timer_RQ 7 "SNA" 2 "TMR30" 1 "TMR60" 0 "TMR120" ;
VAL_ 530 PreHtIndLmp_On_Rq 0 "SNA" ;
VAL_ 530 EngOilTemp_Above_Max 1 "SNA" ;
VAL_ 530 PFW 3 "SNA" 2 "PFW2" 1 "PFW1" 0 "OK" ;
VAL_ 530 ParticleFltrCorrOffset 15 "SNA" ;
VAL_ 530 WtrFuelIndLmp_On_Rq 0 "SNA" ;
VAL_ 530 PF_RgnActv 0 "SNA" ;
VAL_ 530 Adblue_Stat 63 "SNA" 57 "DEFQW10_RL" 56 "DEFQW9_RL" 55 "DEFQW8_RL" 54 "DEFQW7_RL" 53 "DEFQW6_RL" 52 "DEFQW5_RL" 51 "DEFQW4_RL" 50 "DEFQW3_RL" 49 "DEFQW2_RL" 48 "DEFQW1_RL" 47 "DEFLW15_RL" 46 "DEFLW14_RL" 45 "DEFLW13_RL" 44 "DEFLW12_RL" 43 "DEFLW11_RL" 42 "DEFLW10_RL" 41 "DEFLW9_RL" 40 "DEFLW8_RL" 39 "DEFLW7_RL" 38 "DEFLW6_RL" 37 "DEFLW5_RL" 36 "DEFLW4_RL" 35 "DEFLW3_RL" 34 "DEFLW2_RL" 33 "DEFLW1_RL" 25 "DEFQW10" 24 "DEFQW9" 23 "DEFQW8" 22 "DEFQW7" 21 "DEFQW6" 20 "DEFQW5" 19 "DEFQW4" 18 "DEFQW3" 17 "DEFQW2" 16 "DEFQW1" 15 "DEFLW15" 14 "DEFLW14" 13 "DEFLW13" 12 "DEFLW12" 11 "DEFLW11" 10 "DEFLW10" 9 "DEFLW9" 8 "DEFLW8" 7 "DEFLW7" 6 "DEFLW6" 5 "DEFLW5" 4 "DEFLW4" 3 "DEFLW3" 2 "DEFLW2" 1 "DEFLW1" 0 "OK" ;
VAL_ 530 Adblue_FL_LVL 255 "SNA" ;
VAL_ 530 AdblueRemainDist 65535 "SNA" ;
VAL_ 532 IBS_V_BATT 16383 "SNA" ;
VAL_ 532 IBS_I_BATT 65535 "SNA" ;
VAL_ 532 IBS_T_BATT 255 "SNA" ;
VAL_ 532 IBS_PreWakeupVoltage 1023 "SNA" ;
VAL_ 532 IBS_Current_Status 3 "SATURATED" 2 "HW_DEFECT" 1 "OPEN_CKT" 0 "NO_ERROR" ;
VAL_ 532 IBS_Voltage_Status 3 "SATURATED" 2 "HW_DEFECT" 1 "OPEN_CKT" 0 "NO_ERROR" ;
VAL_ 532 IBS_Temp_Status 3 "SATURATED" 2 "HW_DEFECT" 1 "OPEN_CKT" 0 "NO_ERROR" ;
VAL_ 532 IBS_I_RANGE 3 "SNA" 2 "Range_I1500" 1 "Range_I200" 0 "Range_I1" ;
VAL_ 536 Presf_Lvl 15 "SNA" 10 "LVL8" 9 "LVL7" 7 "LVL6" 6 "LVL5" 5 "LVL4" 4 "LVL3" 3 "LVL2" 2 "LVL1" 1 "PRESF_ACCEL_RESET_NOT_EXCD" 0 "PRESF_ACCEL_RESET_EXCD" ;
VAL_ 542 PTRInfo 3 "SUPPLIER" 1 "CPN" 0 "SN" ;
VAL_ 544 StrClmTrq 2047 "SNA" ;
VAL_ 544 TOI_Act_Sts 15 "SNA" 8 "INACT" 7 "DST_TOI_UCF" 6 "DST_TOI_OCF" 5 "DST_TOI_MCF" 4 "DENIED" 3 "READY" 2 "DST_TOI_PNA" 1 "DST_TOI_TNA" 0 "TOI_DEACT" ;
VAL_ 544 StrClmTrqVD 0 "SNA" ;
VAL_ 544 HALFTorqueOverlayIntActivated 0 "SNA" ;
VAL_ 557 StW_TempSts 255 "SNA" ;
VAL_ 557 StW_TempSensSts 3 "SNA" 2 "OPN" 1 "SHRT" 0 "OK" ;
VAL_ 557 Command_01 3 "SNA" 1 "PSD" 0 "NOT_PSD" ;
VAL_ 557 Command_02 3 "SNA" 1 "PSD" 0 "NOT_PSD" ;
VAL_ 557 Command_03 3 "SNA" 1 "PSD" 0 "NOT_PSD" ;
VAL_ 557 Command_04 3 "SNA" 1 "PSD" 0 "NOT_PSD" ;
VAL_ 557 Command_05 3 "SNA" 1 "PSD" 0 "NOT_PSD" ;
VAL_ 557 Command_06 3 "SNA" 1 "PSD" 0 "NOT_PSD" ;
VAL_ 557 Command_07 3 "SNA" 1 "PSD" 0 "NOT_PSD" ;
VAL_ 557 Command_08 3 "SNA" 1 "PSD" 0 "NOT_PSD" ;
VAL_ 557 Command_09 3 "SNA" 1 "PSD" 0 "NOT_PSD" ;
VAL_ 557 Command_10 3 "SNA" 1 "PSD" 0 "NOT_PSD" ;
VAL_ 557 Command_11 3 "SNA" 1 "PSD" 0 "NOT_PSD" ;
VAL_ 557 Command_12 3 "SNA" 1 "PSD" 0 "NOT_PSD" ;
VAL_ 557 Command_13 3 "SNA" 1 "PSD" 0 "NOT_PSD" ;
VAL_ 557 Command_14 3 "SNA" 1 "PSD" 0 "NOT_PSD" ;
VAL_ 557 Command_15 3 "SNA" 1 "PSD" 0 "NOT_PSD" ;
VAL_ 557 Command_16 3 "SNA" 1 "PSD" 0 "NOT_PSD" ;
VAL_ 559 ActlAccelPdlPosn 255 "SNA" ;
VAL_ 559 AirFuelRatio 255 "SNA" ;
VAL_ 559 IntkAirTempIntrClr 255 "SNA" ;
VAL_ 559 LTR_CoolantTemp 255 "SNA" ;
VAL_ 559 ECM_DrvDoor 3 "SNA" 2 "FAULT" 1 "CLOSED" 0 "OPEN" ;
VAL_ 560 AC_RQ 0 "SNA" ;
VAL_ 560 AC_SEL 0 "SNA" ;
VAL_ 560 PTC_Enbl 1 "SNA" ;
VAL_ 560 EVAP_TEMP 255 "SNA" ;
VAL_ 560 EvapTempTar 255 "SNA" ;
VAL_ 560 SpSt_DsblHVAC 7 "SNA" 5 "EBL" 4 "FT_DEFROST" 3 "MAX_AC" 2 "CABIN_LO" 1 "CABIN_HI" 0 "SPST_ON" ;
VAL_ 564 IBS_SOF_V 255 "SNA" ;
VAL_ 564 IBS_SOF_V_Accuracy 3 "SNA" 2 "ACCURACY_2" 1 "ACCURACY_1" 0 "ACCURACY_0" ;
VAL_ 564 Converter_1_State 3 "TEMP_PREWARN" 2 "ERROR" 1 "STAND_BY" 0 "ACTIVE" ;
VAL_ 564 Converter_1_Mode 3 "NA" 2 "TEST" 1 "END_OF_LINE" 0 "NORMAL" ;
VAL_ 564 AM_ECM_Trace 3 "SNA" 2 "AM_ECM_TRACE" 0 "DEFAULT" ;
VAL_ 564 IBS_SOF_V1 255 "SNA" ;
VAL_ 584 PN14_Key_Off_Load_Shed 3 "SNA" 2 "RES" 1 "KEY_OFF_LS_RQ" 0 "NO_KEY_OFF_LS_RQ" ;
VAL_ 584 IBS_SOC 255 "SNA" ;
VAL_ 584 IBS_SOF_Q 255 "SNA" ;
VAL_ 584 IBS_SOH_Q 255 "SNA" ;
VAL_ 584 IBS_SOF_t 1023 "SNA" ;
VAL_ 584 IBS_SOC_Accuracy 3 "SNA" 2 "ACCURACY_2" 1 "ACCURACY_1" 0 "ACCURACY_0" ;
VAL_ 584 IBS_SOF_Q_Accuracy 3 "SNA" 2 "ACCURACY_2" 1 "ACCURACY_1" 0 "ACCURACY_0" ;
VAL_ 584 IBS_SOH_Q_Accuracy 3 "SNA" 2 "ACCURACY_2" 1 "ACCURACY_1" 0 "ACCURACY_0" ;
VAL_ 584 IBS_SOF_t_Accuracy 3 "SNA" 2 "ACCURACY_2" 1 "ACCURACY_1" 0 "ACCURACY_0" ;
VAL_ 608 RR_PTS_Dist 255 "SNA" ;
VAL_ 608 PTS_STAT_Front 3 "SNA" 2 "BLINK" 1 "CONT" 0 "OFF" ;
VAL_ 624 FuelTxfrSts 3 "SNA" 2 "FAULT" 1 "ON" 0 "OFF" ;
VAL_ 624 SecurePkSts 7 "SNA" 3 "FOB" 2 "ACTIVE" 1 "ENABLED" 0 "DISABLED" ;
VAL_ 624 EngineOffTimer 4095 "SNA" ;
VAL_ 624 HL_Stat 3 "LOW_HI" 2 "HI" 1 "LOW" 0 "OFF" ;
VAL_ 632 CC_SetSpdDspl 255 "SNA" ;
VAL_ 632 EngDrvMdStat 7 "SNA" 4 "SPORT_PLUS" 3 "TRACK" 2 "SPORT" 1 "ECO" 0 "NORMAL" ;
VAL_ 632 EVPmpStat 3 "SNA" 2 "FAULT" 1 "ON" 0 "OFF" ;
VAL_ 632 EconShftRq 3 "SNA" 2 "DOWN" 1 "UP" 0 "NONE" ;
VAL_ 632 CoolVlvPos 255 "SNA" ;
VAL_ 632 VehMassCalc 255 "SNA" ;
VAL_ 632 VehMassCnfd 7 "SNA" 5 "CL_FIVE" 4 "CL_FOUR" 3 "CL_THREE" 2 "CL_TWO" 1 "CL_ONE" 0 "CL_ZERO" ;
VAL_ 632 PerfShftRq 3 "SNA" 2 "SHIFT" 1 "SOON" 0 "NONE" ;
VAL_ 632 CC_SetSpdDsplMPH 255 "SNA" ;
VAL_ 632 SpStSwStat 3 "SNA" 2 "BLINK" 1 "CONT" 0 "OFF" ;
VAL_ 632 SpStTachMd 3 "SNA" 2 "SPST" 1 "OFF" 0 "STD" ;
VAL_ 632 SpStWarnStat 15 "SNA" 14 "Park_Inhib" 13 "PSG_DR_INHIB" 12 "Hood_Inhib" 11 "Prk_Brk_Inhib" 10 "SYSFLT" 9 "BATT" 8 "KEY" 7 "TX_INHIB" 6 "DR_INHIB" 5 "D_AND_SB" 4 "D_OR_SB" 3 "ACTIVE" 2 "START" 1 "STARTING" 0 "NONE" ;
VAL_ 632 SpStDispstat 63 "SNA" 38 "BATT_HIGH" 37 "ACC_SET" 36 "PSG_DR_INHIB" 35 "DPF_Regen" 34 "Hood_Inhib" 33 "Park_Inhib" 32 "Prk_Brk_Inhib" 31 "Eng_Temp_Lo" 30 "Eng_Temp_Hi" 29 "ST_WHEEL" 28 "EBL" 27 "FT_DEFROST" 26 "MAX_HVAC" 25 "CABIN" 24 "DR_AJAR" 23 "SB" 22 "ENG_TEMP" 21 "AMB_TEMP" 20 "INCLINE" 19 "LF" 18 "T4WD_L" 17 "TM" 16 "BATT_CHG" 15 "PEDAL" 14 "HOOD" 13 "OFF" 12 "READY" 11 "NR" 10 "SYSFLT" 9 "BATT" 8 "KEY" 7 "TX_INHIB" 6 "DR_INHIB" 5 "D_AND_SB" 4 "D_OR_SB" 3 "ACTIVE" 2 "START" 1 "STARTING" 0 "NONE" ;
VAL_ 639 IBS_Q_received 65535 "SNA" ;
VAL_ 639 IBS_Q_released 65535 "SNA" ;
VAL_ 639 IBS_Tm_Lst_Reset_Sec 65535 "SNA" ;
VAL_ 639 IBS_Tm_Lst_Reset_Days 4095 "SNA" ;
VAL_ 640 Mem_D_Pos_Rq 2 "MEMPOS2" 1 "MEMPOS1" 0 "IDLE" ;
VAL_ 658 MTO_HALFDriveStyleSts 7 "SNA" 5 "TRACPLUS" 4 "SPORT_PLUS" 3 "WINTER" 2 "SPORT" 1 "CITY" 0 "NORMAL" ;
VAL_ 660 TOC_Fault 3 "SNA" 1 "FAULT" 0 "AVAIL" ;
VAL_ 660 TOC_Act_Req 3 "SNA" 1 "ACTIVE" 0 "NOT" ;
VAL_ 660 SyncPos 7 "SNA" 4 "NS" 3 "TEMP" 2 "PRESS" 1 "HIGH" 0 "LOW" ;
VAL_ 660 TOC_Sts 15 "SNA" 7 "TOC_UCF" 6 "TOC_OCF" 5 "TOC_MCF" 3 "TOC_Ready" 2 "TOC_PNA" 1 "TOC_TNA" 0 "TOC_Deactivation" ;
VAL_ 669 EPBHoldSts 5 "BSU" 4 "DC" 3 "Releasing" 2 "Applying" 1 "APPLIED" 0 "REL" ;
VAL_ 671 PTS_ManoeuvreMode 7 "SNA" 4 "OVER" 3 "PULL_OUT" 2 "PERP" 1 "PARA" 0 "None" ;
VAL_ 672 ETC_IND_LMP 3 "SNA" 2 "ON_Flashing" 1 "ON" 0 "OFF" ;
VAL_ 672 FUEL_SAV_MD_ACT 3 "SNA" 2 "ON" 1 "OFF" 0 "NOT_AVAIL" ;
VAL_ 672 EngOilIndLmp_On_Rq 1 "SNA" ;
VAL_ 672 OIL_TEMP_IND_RQ 3 "SNA" 2 "IND_LMP_FLASH" 1 "IND_LMP_ON" 0 "IND_LMP_OFF" ;
VAL_ 672 OIL_TEMP_CHM_RQ 3 "FAST_CHM" 2 "SLOW_CHM" 1 "1_CHM" 0 "NO_CHM" ;
VAL_ 672 OIL_PRESS 255 "SNA" ;
VAL_ 672 EngOilTemp 255 "SNA" ;
VAL_ 672 FuelCons 65535 "SNA" ;
VAL_ 672 DefFuelEcon 255 "SNA" ;
VAL_ 672 EngRun_Stat 7 "SNA" 6 "NDEF6" 5 "LIMITED" 4 "UNLIMITED" 3 "IDLE_STBL" 2 "IDLE_UNSTBL" 1 "START" 0 "STOP" ;
VAL_ 672 RedntHdStat 3 "SNA" 2 "Open" 1 "Ajar" 0 "Closed" ;
